[part 1 of 3: package /STLASWCs]
AUTOSAR XML (schema 00044)
package /STLASWCs
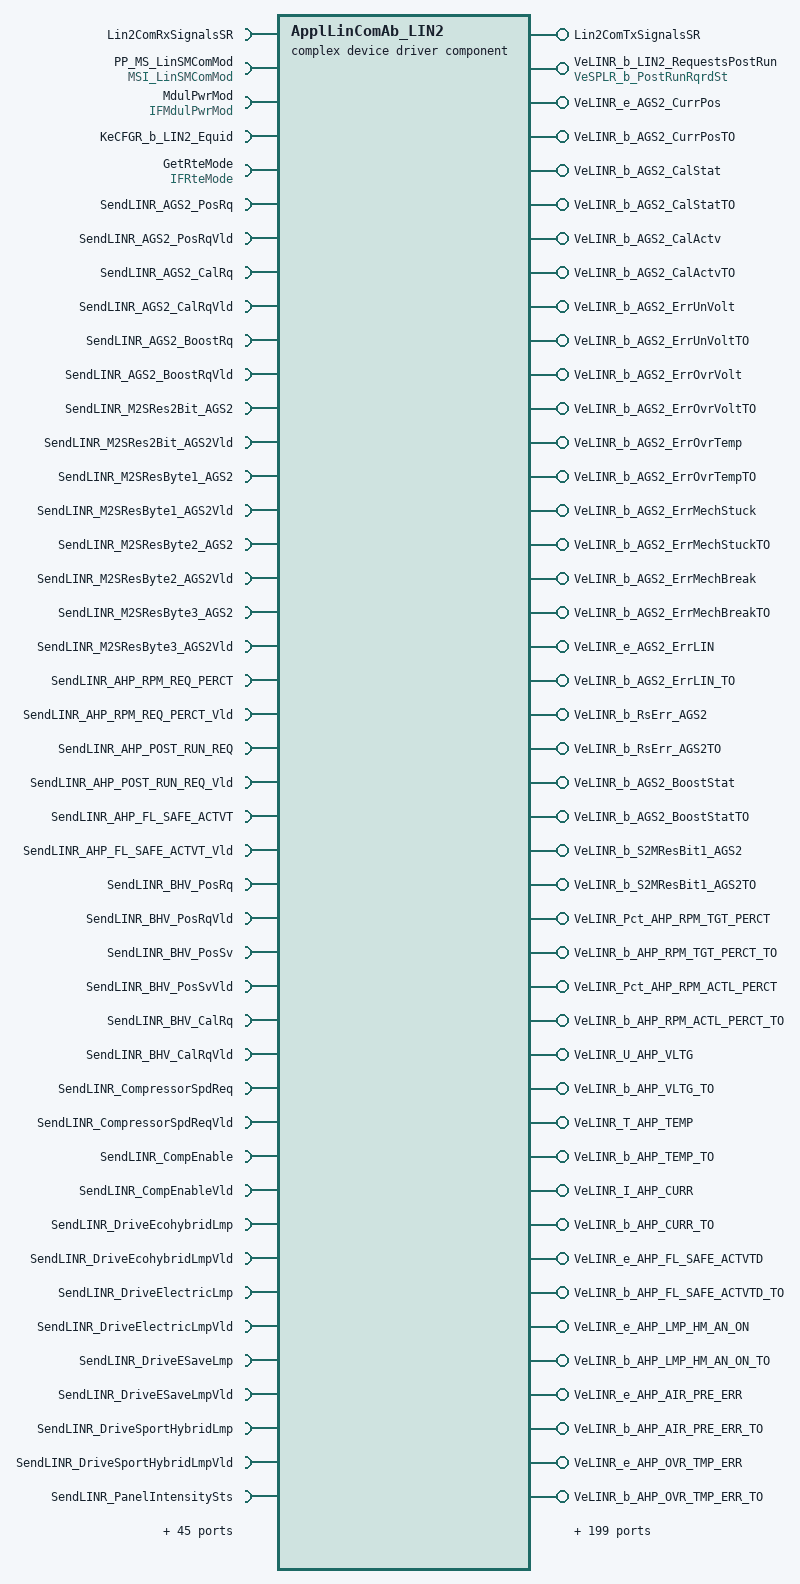
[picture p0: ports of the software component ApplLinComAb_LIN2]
  complex device driver sw component type ApplLinComAb_LIN2  # Application CAN Communication Abstraction Component - is responsible with receiving and sending CAN data from/to the lower BSW COM layers
    provide port Lin2ComTxSignalsSR: provided-interface=Lin2ComTxSignalsSR
      provided-com-specs:
        data-element=COMTXL_AGS2_PosRq_ECM_AGS2_DEMAND_Lin2, init-value=constant-reference=COMTXL_AGS2_PosRq_ECM_AGS2_DEMAND_Lin2_Init
        data-element=COMTXL_AGS2_CalRq_ECM_AGS2_DEMAND_Lin2, init-value=constant-reference=COMTXL_AGS2_CalRq_ECM_AGS2_DEMAND_Lin2_Init
        data-element=COMTXL_AGS2_BoostRq_ECM_AGS2_DEMAND_Lin2, init-value=constant-reference=COMTXL_AGS2_BoostRq_ECM_AGS2_DEMAND_Lin2_Init
        data-element=COMTXL_M2SRes2Bit_AGS2_ECM_AGS2_DEMAND_Lin2, init-value=constant-reference=COMTXL_M2SRes2Bit_AGS2_ECM_AGS2_DEMAND_Lin2_Init
        data-element=COMTXL_M2SResByte{1..3}_AGS2_ECM_AGS2_DEMAND_Lin2, init-value=constant-reference=COMTXL_M2SResByte{1..3}_AGS2_ECM_AGS2_DEMAND_Lin2_Init
        data-element=COMTXL_AHP_RPM_REQ_PERCT_AHP_REQ_GLOBAL_Lin2, init-value=constant-reference=COMTXL_AHP_RPM_REQ_PERCT_AHP_REQ_GLOBAL_Lin2_Init
        data-element=COMTXL_AHP_POST_RUN_REQ_AHP_REQ_GLOBAL_Lin2, init-value=constant-reference=COMTXL_AHP_POST_RUN_REQ_AHP_REQ_GLOBAL_Lin2_Init
        data-element=COMTXL_AHP_FL_SAFE_ACTVT_AHP_REQ_GLOBAL_Lin2, init-value=constant-reference=COMTXL_AHP_FL_SAFE_ACTVT_AHP_REQ_GLOBAL_Lin2_Init
        data-element=COMTXL_BHV_PosRq_BHV_REQ_Lin2, init-value=constant-reference=COMTXL_BHV_PosRq_BHV_REQ_Lin2_Init
        data-element=COMTXL_BHV_PosSv_BHV_REQ_Lin2, init-value=constant-reference=COMTXL_BHV_PosSv_BHV_REQ_Lin2_Init
        data-element=COMTXL_BHV_CalRq_BHV_REQ_Lin2, init-value=constant-reference=COMTXL_BHV_CalRq_BHV_REQ_Lin2_Init
        data-element=COMTXL_CompressorSpdReq_COMP_REQ_Lin2, init-value=constant-reference=COMTXL_CompressorSpdReq_COMP_REQ_Lin2_Init
        data-element=COMTXL_CompEnable_COMP_REQ_Lin2, init-value=constant-reference=COMTXL_CompEnable_COMP_REQ_Lin2_Init
        data-element=COMTXL_DriveEcohybridLmp_MASTER_ESBM_1_Lin2, init-value=constant-reference=COMTXL_DriveEcohybridLmp_MASTER_ESBM_1_Lin2_Init
        data-element=COMTXL_DriveElectricLmp_MASTER_ESBM_1_Lin2, init-value=constant-reference=COMTXL_DriveElectricLmp_MASTER_ESBM_1_Lin2_Init
        data-element=COMTXL_DriveESaveLmp_MASTER_ESBM_1_Lin2, init-value=constant-reference=COMTXL_DriveESaveLmp_MASTER_ESBM_1_Lin2_Init
        data-element=COMTXL_DriveSportHybridLmp_MASTER_ESBM_1_Lin2, init-value=constant-reference=COMTXL_DriveSportHybridLmp_MASTER_ESBM_1_Lin2_Init
        data-element=COMTXL_PanelIntensitySts_MASTER_ESBM_1_Lin2, init-value=constant-reference=COMTXL_PanelIntensitySts_MASTER_ESBM_1_Lin2_Init
        data-element=COMTXL_DAY_LGT_MD_MASTER_ESBM_1_Lin2, init-value=constant-reference=COMTXL_DAY_LGT_MD_MASTER_ESBM_1_Lin2_Init
        data-element=COMTXL_PECP_RPM_REQ_PERCT_PECP_REQ_GLOBAL_Lin2, init-value=constant-reference=COMTXL_PECP_RPM_REQ_PERCT_PECP_REQ_GLOBAL_Lin2_Init
        data-element=COMTXL_PECP_POST_RUN_REQ_PECP_REQ_GLOBAL_Lin2, init-value=constant-reference=COMTXL_PECP_POST_RUN_REQ_PECP_REQ_GLOBAL_Lin2_Init
        data-element=COMTXL_PECP_FL_SAFE_ACTVT_PECP_REQ_GLOBAL_Lin2, init-value=constant-reference=COMTXL_PECP_FL_SAFE_ACTVT_PECP_REQ_GLOBAL_Lin2_Init
        data-element=COMTXL_PowerPanel_LED_A_Command_PowerPanel_REQ_Lin2, init-value=constant-reference=COMTXL_PowerPanel_LED_A_Command_PowerPanel_REQ_Lin2_Init
        data-element=COMTXL_PowerPanel_LED_B_Command_PowerPanel_REQ_Lin2, init-value=constant-reference=COMTXL_PowerPanel_LED_B_Command_PowerPanel_REQ_Lin2_Init
        data-element=COMTXL_DAY_LGT_MD_PowerPanel_PowerPanel_REQ_Lin2, init-value=constant-reference=COMTXL_DAY_LGT_MD_PowerPanel_PowerPanel_REQ_Lin2_Init
        data-element=COMTXL_OEXV_PosRq_OEXV_REQ_Lin2, init-value=constant-reference=COMTXL_OEXV_PosRq_OEXV_REQ_Lin2_Init
        data-element=COMTXL_OEXV_CalCmd_OEXV_REQ_Lin2, init-value=constant-reference=COMTXL_OEXV_CalCmd_OEXV_REQ_Lin2_Init
        data-element=COMTXL_PowerPanel_LED_C_Command_PowerPanel_REQ_Lin2, init-value=constant-reference=COMTXL_PowerPanel_LED_C_Command_PowerPanel_REQ_Lin2_Init
        data-element=COMTXL_PowerPanel_LED_A_Color_Command_PowerPanel_REQ_Lin2, init-value=constant-reference=COMTXL_PowerPanel_LED_A_Color_Command_PowerPanel_REQ_Lin2_Init
        data-element=COMTXL_PowerPanel_LED_B_Color_Command_PowerPanel_REQ_Lin2, init-value=constant-reference=COMTXL_PowerPanel_LED_B_Color_Command_PowerPanel_REQ_Lin2_Init
        data-element=COMTXL_PowerPanel_LED_C_Color_Command_PowerPanel_REQ_Lin2, init-value=constant-reference=COMTXL_PowerPanel_LED_C_Color_Command_PowerPanel_REQ_Lin2_Init
    provide port VeLINR_b_LIN2_RequestsPostRun: nonqueued-sender-com-spec{data-element=VeSPLR_b_PostRunRqrdSt, init-value=1}, provided-interface=VeSPLR_b_PostRunRqrdSt  # Indicates LIN is ready for power down
    5 x require port:
      Lin2ComRxSignalsSR: required-interface=Lin2ComRxSignalsSR
        required-com-specs:
          data-element=COMRXL_AGS2_CurrPos_AGS2_ECM_STATUS_Lin2, alive-timeout=2.5, handle-never-received=true, init-value=constant-reference=COMRXL_AGS2_CurrPos_AGS2_ECM_STATUS_Lin2_Init
          data-element=COMRXL_AGS2_CalStat_AGS2_ECM_STATUS_Lin2, alive-timeout=2.5, handle-never-received=true, init-value=constant-reference=COMRXL_AGS2_CalStat_AGS2_ECM_STATUS_Lin2_Init
          data-element=COMRXL_AGS2_CalActv_AGS2_ECM_STATUS_Lin2, alive-timeout=2.5, handle-never-received=true, init-value=constant-reference=COMRXL_AGS2_CalActv_AGS2_ECM_STATUS_Lin2_Init
          data-element=COMRXL_AGS2_ErrUnVolt_AGS2_ECM_STATUS_Lin2, alive-timeout=2.5, handle-never-received=true, init-value=constant-reference=COMRXL_AGS2_ErrUnVolt_AGS2_ECM_STATUS_Lin2_Init
          data-element=COMRXL_AGS2_ErrOvrVolt_AGS2_ECM_STATUS_Lin2, alive-timeout=2.5, handle-never-received=true, init-value=constant-reference=COMRXL_AGS2_ErrOvrVolt_AGS2_ECM_STATUS_Lin2_Init
          data-element=COMRXL_AGS2_ErrOvrTemp_AGS2_ECM_STATUS_Lin2, alive-timeout=2.5, handle-never-received=true, init-value=constant-reference=COMRXL_AGS2_ErrOvrTemp_AGS2_ECM_STATUS_Lin2_Init
          data-element=COMRXL_AGS2_ErrMechStuck_AGS2_ECM_STATUS_Lin2, alive-timeout=2.5, handle-never-received=true, init-value=constant-reference=COMRXL_AGS2_ErrMechStuck_AGS2_ECM_STATUS_Lin2_Init
          data-element=COMRXL_AGS2_ErrMechBreak_AGS2_ECM_STATUS_Lin2, alive-timeout=2.5, handle-never-received=true, init-value=constant-reference=COMRXL_AGS2_ErrMechBreak_AGS2_ECM_STATUS_Lin2_Init
          data-element=COMRXL_AGS2_ErrLIN_AGS2_ECM_STATUS_Lin2, alive-timeout=2.5, handle-never-received=true, init-value=constant-reference=COMRXL_AGS2_ErrLIN_AGS2_ECM_STATUS_Lin2_Init
          data-element=COMRXL_RsErr_AGS2_AGS2_ECM_STATUS_Lin2, alive-timeout=2.5, handle-never-received=true, init-value=constant-reference=COMRXL_RsErr_AGS2_AGS2_ECM_STATUS_Lin2_Init
          data-element=COMRXL_AGS2_BoostStat_AGS2_ECM_STATUS_Lin2, alive-timeout=2.5, handle-never-received=true, init-value=constant-reference=COMRXL_AGS2_BoostStat_AGS2_ECM_STATUS_Lin2_Init
          data-element=COMRXL_S2MResBit1_AGS2_AGS2_ECM_STATUS_Lin2, alive-timeout=2.5, handle-never-received=true, init-value=constant-reference=COMRXL_S2MResBit1_AGS2_AGS2_ECM_STATUS_Lin2_Init
          data-element=COMRXL_AHP_RPM_TGT_PERCT_AHP_STAT_GLOBAL_Lin2, alive-timeout=2.5, handle-never-received=true, init-value=constant-reference=COMRXL_AHP_RPM_TGT_PERCT_AHP_STAT_GLOBAL_Lin2_Init
          data-element=COMRXL_AHP_RPM_ACTL_PERCT_AHP_STAT_GLOBAL_Lin2, alive-timeout=2.5, handle-never-received=true, init-value=constant-reference=COMRXL_AHP_RPM_ACTL_PERCT_AHP_STAT_GLOBAL_Lin2_Init
          data-element=COMRXL_AHP_VLTG_AHP_STAT_GLOBAL_Lin2, alive-timeout=2.5, handle-never-received=true, init-value=constant-reference=COMRXL_AHP_VLTG_AHP_STAT_GLOBAL_Lin2_Init
          data-element=COMRXL_AHP_TEMP_AHP_STAT_GLOBAL_Lin2, alive-timeout=2.5, handle-never-received=true, init-value=constant-reference=COMRXL_AHP_TEMP_AHP_STAT_GLOBAL_Lin2_Init
          data-element=COMRXL_AHP_CURR_AHP_STAT_GLOBAL_Lin2, alive-timeout=2.5, handle-never-received=true, init-value=constant-reference=COMRXL_AHP_CURR_AHP_STAT_GLOBAL_Lin2_Init
          data-element=COMRXL_AHP_FL_SAFE_ACTVTD_AHP_STAT_GLOBAL_Lin2, alive-timeout=2.5, handle-never-received=true, init-value=constant-reference=COMRXL_AHP_FL_SAFE_ACTVTD_AHP_STAT_GLOBAL_Lin2_Init
          data-element=COMRXL_AHP_LMP_HM_AN_ON_AHP_STAT_GLOBAL_Lin2, alive-timeout=2.5, handle-never-received=true, init-value=constant-reference=COMRXL_AHP_LMP_HM_AN_ON_AHP_STAT_GLOBAL_Lin2_Init
          data-element=COMRXL_AHP_AIR_PRE_ERR_AHP_STAT_GLOBAL_Lin2, alive-timeout=2.5, handle-never-received=true, init-value=constant-reference=COMRXL_AHP_AIR_PRE_ERR_AHP_STAT_GLOBAL_Lin2_Init
          data-element=COMRXL_AHP_OVR_TMP_ERR_AHP_STAT_GLOBAL_Lin2, alive-timeout=2.5, handle-never-received=true, init-value=constant-reference=COMRXL_AHP_OVR_TMP_ERR_AHP_STAT_GLOBAL_Lin2_Init
          data-element=COMRXL_AHP_OVR_CUR_ERR_AHP_STAT_GLOBAL_Lin2, alive-timeout=2.5, handle-never-received=true, init-value=constant-reference=COMRXL_AHP_OVR_CUR_ERR_AHP_STAT_GLOBAL_Lin2_Init
          data-element=COMRXL_AHP_DR_RN_ERR_AHP_STAT_GLOBAL_Lin2, alive-timeout=2.5, handle-never-received=true, init-value=constant-reference=COMRXL_AHP_DR_RN_ERR_AHP_STAT_GLOBAL_Lin2_Init
          data-element=COMRXL_AHP_VLTG_ERR_AHP_STAT_GLOBAL_Lin2, alive-timeout=2.5, handle-never-received=true, init-value=constant-reference=COMRXL_AHP_VLTG_ERR_AHP_STAT_GLOBAL_Lin2_Init
          data-element=COMRXL_AHP_DBLK_ACTV_AHP_STAT_GLOBAL_Lin2, alive-timeout=2.5, handle-never-received=true, init-value=constant-reference=COMRXL_AHP_DBLK_ACTV_AHP_STAT_GLOBAL_Lin2_Init
          data-element=COMRXL_AHP_MONTRNG_RPM_AHP_STAT_GLOBAL_Lin2, alive-timeout=2.5, handle-never-received=true, init-value=constant-reference=COMRXL_AHP_MONTRNG_RPM_AHP_STAT_GLOBAL_Lin2_Init
          data-element=COMRXL_AHP_NODE_ERR_AHP_STAT_GLOBAL_Lin2, alive-timeout=2.5, handle-never-received=true, init-value=constant-reference=COMRXL_AHP_NODE_ERR_AHP_STAT_GLOBAL_Lin2_Init
          data-element=COMRXL_AHP_POST_RUN_STAT_AHP_STAT_GLOBAL_Lin2, alive-timeout=2.5, handle-never-received=true, init-value=constant-reference=COMRXL_AHP_POST_RUN_STAT_AHP_STAT_GLOBAL_Lin2_Init
          data-element=COMRXL_RsErr_AHP_PUMP_AHP_STAT_GLOBAL_Lin2, alive-timeout=2.5, handle-never-received=true, init-value=constant-reference=COMRXL_RsErr_AHP_PUMP_AHP_STAT_GLOBAL_Lin2_Init
          data-element=COMRXL_AHP_SUPPLIER_AHP_VER_Lin2, alive-timeout=2.5, handle-never-received=true, init-value=constant-reference=COMRXL_AHP_SUPPLIER_AHP_VER_Lin2_Init
          data-element=COMRXL_BHV_PosAct_BHV_STAT_V2_Lin2, alive-timeout=2.5, handle-never-received=true, init-value=constant-reference=COMRXL_BHV_PosAct_BHV_STAT_V2_Lin2_Init
          data-element=COMRXL_BHV_ERR_BHV_STAT_V2_Lin2, alive-timeout=2.5, handle-never-received=true, init-value=constant-reference=COMRXL_BHV_ERR_BHV_STAT_V2_Lin2_Init
          data-element=COMRXL_BHV_Sts_BHV_STAT_V2_Lin2, alive-timeout=2.5, handle-never-received=true, init-value=constant-reference=COMRXL_BHV_Sts_BHV_STAT_V2_Lin2_Init
          data-element=COMRXL_RsErr_BHV_BHV_STAT_V2_Lin2, alive-timeout=2.5, handle-never-received=true, init-value=constant-reference=COMRXL_RsErr_BHV_BHV_STAT_V2_Lin2_Init
          data-element=COMRXL_CompFaultStat_EAC_STAT_Lin2, alive-timeout=2.5, handle-never-received=true, init-value=constant-reference=COMRXL_CompFaultStat_EAC_STAT_Lin2_Init
          data-element=COMRXL_CompStat_EAC_STAT_Lin2, alive-timeout=2.5, handle-never-received=true, init-value=constant-reference=COMRXL_CompStat_EAC_STAT_Lin2_Init
          data-element=COMRXL_CompressorSpd_EAC_STAT_Lin2, alive-timeout=2.5, handle-never-received=true, init-value=constant-reference=COMRXL_CompressorSpd_EAC_STAT_Lin2_Init
          data-element=COMRXL_CompSpdIncrReq_EAC_STAT_Lin2, alive-timeout=2.5, handle-never-received=true, init-value=constant-reference=COMRXL_CompSpdIncrReq_EAC_STAT_Lin2_Init
          data-element=COMRXL_CompElecPwr_EAC_STAT_Lin2, alive-timeout=2.5, handle-never-received=true, init-value=constant-reference=COMRXL_CompElecPwr_EAC_STAT_Lin2_Init
          data-element=COMRXL_CompBoardTemp_EAC_STAT_Lin2, alive-timeout=2.5, handle-never-received=true, init-value=constant-reference=COMRXL_CompBoardTemp_EAC_STAT_Lin2_Init
          data-element=COMRXL_CompIGBTTemp_EAC_STAT_Lin2, alive-timeout=2.5, handle-never-received=true, init-value=constant-reference=COMRXL_CompIGBTTemp_EAC_STAT_Lin2_Init
          data-element=COMRXL_CompElecCurr_EAC_STAT_Lin2, alive-timeout=2.5, handle-never-received=true, init-value=constant-reference=COMRXL_CompElecCurr_EAC_STAT_Lin2_Init
          data-element=COMRXL_CompHVInput_EAC_STAT_Lin2, alive-timeout=2.5, handle-never-received=true, init-value=constant-reference=COMRXL_CompHVInput_EAC_STAT_Lin2_Init
          data-element=COMRXL_DriveMdReq_ESBM_1_Lin2, alive-timeout=2.5, handle-never-received=true, init-value=constant-reference=COMRXL_DriveMdReq_ESBM_1_Lin2_Init
          data-element=COMRXL_HybridModeRq_LIN_ESBM_1_Lin2, alive-timeout=2.5, handle-never-received=true, init-value=constant-reference=COMRXL_HybridModeRq_LIN_ESBM_1_Lin2_Init
          data-element=COMRXL_ESaveModeRq_LIN_ESBM_1_Lin2, alive-timeout=2.5, handle-never-received=true, init-value=constant-reference=COMRXL_ESaveModeRq_LIN_ESBM_1_Lin2_Init
          data-element=COMRXL_ElectricModeRq_LIN_ESBM_1_Lin2, alive-timeout=2.5, handle-never-received=true, init-value=constant-reference=COMRXL_ElectricModeRq_LIN_ESBM_1_Lin2_Init
          data-element=COMRXL_RsErr_ESBM_ESBM_1_Lin2, alive-timeout=2.5, handle-never-received=true, init-value=constant-reference=COMRXL_RsErr_ESBM_ESBM_1_Lin2_Init
          data-element=COMRXL_PECP_RPM_TGT_PERCT_PECP_STAT_GLOBAL_Lin2, alive-timeout=2.5, handle-never-received=true, init-value=constant-reference=COMRXL_PECP_RPM_TGT_PERCT_PECP_STAT_GLOBAL_Lin2_Init
          data-element=COMRXL_PECP_RPM_ACTL_PERCT_PECP_STAT_GLOBAL_Lin2, alive-timeout=2.5, handle-never-received=true, init-value=constant-reference=COMRXL_PECP_RPM_ACTL_PERCT_PECP_STAT_GLOBAL_Lin2_Init
          data-element=COMRXL_PECP_VLTG_PECP_STAT_GLOBAL_Lin2, alive-timeout=2.5, handle-never-received=true, init-value=constant-reference=COMRXL_PECP_VLTG_PECP_STAT_GLOBAL_Lin2_Init
          data-element=COMRXL_PECP_TEMP_PECP_STAT_GLOBAL_Lin2, alive-timeout=2.5, handle-never-received=true, init-value=constant-reference=COMRXL_PECP_TEMP_PECP_STAT_GLOBAL_Lin2_Init
          data-element=COMRXL_PECP_CURR_PECP_STAT_GLOBAL_Lin2, alive-timeout=2.5, handle-never-received=true, init-value=constant-reference=COMRXL_PECP_CURR_PECP_STAT_GLOBAL_Lin2_Init
          data-element=COMRXL_PECP_FL_SAFE_ACTVTD_PECP_STAT_GLOBAL_Lin2, alive-timeout=2.5, handle-never-received=true, init-value=constant-reference=COMRXL_PECP_FL_SAFE_ACTVTD_PECP_STAT_GLOBAL_Lin2_Init
          data-element=COMRXL_PECP_LMP_HM_AN_ON_PECP_STAT_GLOBAL_Lin2, alive-timeout=2.5, handle-never-received=true, init-value=constant-reference=COMRXL_PECP_LMP_HM_AN_ON_PECP_STAT_GLOBAL_Lin2_Init
          data-element=COMRXL_PECP_AIR_PRE_ERR_PECP_STAT_GLOBAL_Lin2, alive-timeout=2.5, handle-never-received=true, init-value=constant-reference=COMRXL_PECP_AIR_PRE_ERR_PECP_STAT_GLOBAL_Lin2_Init
          data-element=COMRXL_PECP_OVR_TMP_ERR_PECP_STAT_GLOBAL_Lin2, alive-timeout=2.5, handle-never-received=true, init-value=constant-reference=COMRXL_PECP_OVR_TMP_ERR_PECP_STAT_GLOBAL_Lin2_Init
          data-element=COMRXL_PECP_OVR_CUR_ERR_PECP_STAT_GLOBAL_Lin2, alive-timeout=2.5, handle-never-received=true, init-value=constant-reference=COMRXL_PECP_OVR_CUR_ERR_PECP_STAT_GLOBAL_Lin2_Init
          data-element=COMRXL_PECP_DR_RN_ERR_PECP_STAT_GLOBAL_Lin2, alive-timeout=2.5, handle-never-received=true, init-value=constant-reference=COMRXL_PECP_DR_RN_ERR_PECP_STAT_GLOBAL_Lin2_Init
          data-element=COMRXL_PECP_VLTG_ERR_PECP_STAT_GLOBAL_Lin2, alive-timeout=2.5, handle-never-received=true, init-value=constant-reference=COMRXL_PECP_VLTG_ERR_PECP_STAT_GLOBAL_Lin2_Init
          data-element=COMRXL_PECP_DBLK_ACTV_PECP_STAT_GLOBAL_Lin2, alive-timeout=2.5, handle-never-received=true, init-value=constant-reference=COMRXL_PECP_DBLK_ACTV_PECP_STAT_GLOBAL_Lin2_Init
          data-element=COMRXL_PECP_MONTRNG_RPM_PECP_STAT_GLOBAL_Lin2, alive-timeout=2.5, handle-never-received=true, init-value=constant-reference=COMRXL_PECP_MONTRNG_RPM_PECP_STAT_GLOBAL_Lin2_Init
          data-element=COMRXL_PECP_NODE_ERR_PECP_STAT_GLOBAL_Lin2, alive-timeout=2.5, handle-never-received=true, init-value=constant-reference=COMRXL_PECP_NODE_ERR_PECP_STAT_GLOBAL_Lin2_Init
          data-element=COMRXL_PECP_POST_RUN_STAT_PECP_STAT_GLOBAL_Lin2, alive-timeout=2.5, handle-never-received=true, init-value=constant-reference=COMRXL_PECP_POST_RUN_STAT_PECP_STAT_GLOBAL_Lin2_Init
          data-element=COMRXL_RsErr_PECP_PUMP_PECP_STAT_GLOBAL_Lin2, alive-timeout=2.5, handle-never-received=true, init-value=constant-reference=COMRXL_RsErr_PECP_PUMP_PECP_STAT_GLOBAL_Lin2_Init
          data-element=COMRXL_PECP_SUPPLIER_PECP_VER_Lin2, alive-timeout=2.5, handle-never-received=true, init-value=constant-reference=COMRXL_PECP_SUPPLIER_PECP_VER_Lin2_Init
          data-element=COMRXL_PowerPanel_Button_State_PowerPanel_STAT_Lin2, alive-timeout=2.5, handle-never-received=true, init-value=constant-reference=COMRXL_PowerPanel_Button_State_PowerPanel_STAT_Lin2_Init
          data-element=COMRXL_PowerPanel_Lid_Switch_Sts_120A_PowerPanel_STAT_Lin2, alive-timeout=2.5, handle-never-received=true, init-value=constant-reference=COMRXL_PowerPanel_Lid_Switch_Sts_120A_PowerPanel_STAT_Lin2_Init
          data-element=COMRXL_PowerPanel_Lid_Switch_Sts_120B_PowerPanel_STAT_Lin2, alive-timeout=2.5, handle-never-received=true, init-value=constant-reference=COMRXL_PowerPanel_Lid_Switch_Sts_120B_PowerPanel_STAT_Lin2_Init
          data-element=COMRXL_PowerPanel_Lid_Switch_Sts_240_PowerPanel_STAT_Lin2, alive-timeout=2.5, handle-never-received=true, init-value=constant-reference=COMRXL_PowerPanel_Lid_Switch_Sts_240_PowerPanel_STAT_Lin2_Init
          data-element=COMRXL_PowerPanel_Fault_Reason_PowerPanel_STAT_Lin2, alive-timeout=2.5, handle-never-received=true, init-value=constant-reference=COMRXL_PowerPanel_Fault_Reason_PowerPanel_STAT_Lin2_Init
          data-element=COMRXL_RsErr_SPP_PowerPanel_STAT_Lin2, alive-timeout=2.5, handle-never-received=true, init-value=constant-reference=COMRXL_RsErr_SPP_PowerPanel_STAT_Lin2_Init
          data-element=COMRXL_AHP_VERSION_AHP_VER_Lin2, alive-timeout=2.5, handle-never-received=true, init-value=constant-reference=COMRXL_AHP_VERSION_AHP_VER_Lin2_Init
          data-element=COMRXL_PECP_VERSION_PECP_VER_Lin2, alive-timeout=2.5, handle-never-received=true, init-value=constant-reference=COMRXL_PECP_VERSION_PECP_VER_Lin2_Init
          data-element=COMRXL_S2MResByte1_AGS2_AGS2_ECM_STATUS_Lin2, alive-timeout=2.5, handle-never-received=true, init-value=constant-reference=COMRXL_S2MResByte1_AGS2_AGS2_ECM_STATUS_Lin2_Init
          data-element=COMRXL_S2MResByte2_AGS2_AGS2_ECM_STATUS_Lin2, alive-timeout=2.5, handle-never-received=true, init-value=constant-reference=COMRXL_S2MResByte2_AGS2_AGS2_ECM_STATUS_Lin2_Init
          data-element=COMRXL_BHV_MotorVolt_BHV_STAT_V2_Lin2, alive-timeout=2.5, handle-never-received=true, init-value=constant-reference=COMRXL_BHV_MotorVolt_BHV_STAT_V2_Lin2_Init
          data-element=COMRXL_BHV_CalStat_BHV_STAT_V2_Lin2, alive-timeout=2.5, handle-never-received=true, init-value=constant-reference=COMRXL_BHV_CalStat_BHV_STAT_V2_Lin2_Init
          data-element=COMRXL_OEXV_PosAct_OEXV_STAT_Lin2, alive-timeout=2.5, handle-never-received=true, init-value=constant-reference=COMRXL_OEXV_PosAct_OEXV_STAT_Lin2_Init
          data-element=COMRXL_OEXV_CalStat_OEXV_STAT_Lin2, alive-timeout=2.5, handle-never-received=true, init-value=constant-reference=COMRXL_OEXV_CalStat_OEXV_STAT_Lin2_Init
          data-element=COMRXL_OEXV_CalRq_OEXV_STAT_Lin2, alive-timeout=2.5, handle-never-received=true, init-value=constant-reference=COMRXL_OEXV_CalRq_OEXV_STAT_Lin2_Init
          data-element=COMRXL_RsErr_OEXV_OEXV_STAT_Lin2, alive-timeout=2.5, handle-never-received=true, init-value=constant-reference=COMRXL_RsErr_OEXV_OEXV_STAT_Lin2_Init
          data-element=COMRXL_OEXV_Sts_OEXV_STAT_Lin2, alive-timeout=2.5, handle-never-received=true, init-value=constant-reference=COMRXL_OEXV_Sts_OEXV_STAT_Lin2_Init
          data-element=COMRXL_OEXV_ERR_OEXV_STAT_Lin2, alive-timeout=2.5, handle-never-received=true, init-value=constant-reference=COMRXL_OEXV_ERR_OEXV_STAT_Lin2_Init
          data-element=COMRXL_OEXV_SupplyVolt_OEXV_STAT_Lin2, alive-timeout=2.5, handle-never-received=true, init-value=constant-reference=COMRXL_OEXV_SupplyVolt_OEXV_STAT_Lin2_Init
          data-element=COMRXL_OEXV_Refrigerant_Pressure_OEXV_STAT_Lin2, alive-timeout=2.5, handle-never-received=true, init-value=constant-reference=COMRXL_OEXV_Refrigerant_Pressure_OEXV_STAT_Lin2_Init
          data-element=COMRXL_OEXV_Board_Temp_OEXV_STAT_Lin2, alive-timeout=2.5, handle-never-received=true, init-value=constant-reference=COMRXL_OEXV_Board_Temp_OEXV_STAT_Lin2_Init
          data-element=COMRXL_OEXV_Refrigerant_Temp_OEXV_STAT_Lin2, alive-timeout=2.5, handle-never-received=true, init-value=constant-reference=COMRXL_OEXV_Refrigerant_Temp_OEXV_STAT_Lin2_Init
          data-element=COMRXL_CompFaultStat_800_EAC_STAT_800_Lin2, alive-timeout=2.5, handle-never-received=true, init-value=constant-reference=COMRXL_CompFaultStat_800_EAC_STAT_800_Lin2_Init
          data-element=COMRXL_CompStat_800_EAC_STAT_800_Lin2, alive-timeout=2.5, handle-never-received=true, init-value=constant-reference=COMRXL_CompStat_800_EAC_STAT_800_Lin2_Init
          data-element=COMRXL_CompressorSpd_800_EAC_STAT_800_Lin2, alive-timeout=2.5, handle-never-received=true, init-value=constant-reference=COMRXL_CompressorSpd_800_EAC_STAT_800_Lin2_Init
          data-element=COMRXL_CompSpdIncrReq_800_EAC_STAT_800_Lin2, alive-timeout=2.5, handle-never-received=true, init-value=constant-reference=COMRXL_CompSpdIncrReq_800_EAC_STAT_800_Lin2_Init
          data-element=COMRXL_RsErr_EAC2_800_EAC_STAT_800_Lin2, alive-timeout=2.5, handle-never-received=true, init-value=constant-reference=COMRXL_RsErr_EAC2_800_EAC_STAT_800_Lin2_Init
          data-element=COMRXL_CompElecPwr_800_EAC_STAT_800_Lin2, alive-timeout=2.5, handle-never-received=true, init-value=constant-reference=COMRXL_CompElecPwr_800_EAC_STAT_800_Lin2_Init
          data-element=COMRXL_CompBoardTemp_800_EAC_STAT_800_Lin2, alive-timeout=2.5, handle-never-received=true, init-value=constant-reference=COMRXL_CompBoardTemp_800_EAC_STAT_800_Lin2_Init
          data-element=COMRXL_CompIGBTTemp_800_EAC_STAT_800_Lin2, alive-timeout=2.5, handle-never-received=true, init-value=constant-reference=COMRXL_CompIGBTTemp_800_EAC_STAT_800_Lin2_Init
          data-element=COMRXL_CompElecCurr_800_EAC_STAT_800_Lin2, alive-timeout=2.5, handle-never-received=true, init-value=constant-reference=COMRXL_CompElecCurr_800_EAC_STAT_800_Lin2_Init
          data-element=COMRXL_CompHVInput_800_EAC_STAT_800_Lin2, alive-timeout=2.5, handle-never-received=true, init-value=constant-reference=COMRXL_CompHVInput_800_EAC_STAT_800_Lin2_Init
          data-element=COMRXL_PowerPanel_LED_A_Feedback_PowerPanel_STAT_Lin2, alive-timeout=2.5, handle-never-received=true, init-value=constant-reference=COMRXL_PowerPanel_LED_A_Feedback_PowerPanel_STAT_Lin2_Init
          data-element=COMRXL_PowerPanel_LED_B_Feedback_PowerPanel_STAT_Lin2, alive-timeout=2.5, handle-never-received=true, init-value=constant-reference=COMRXL_PowerPanel_LED_B_Feedback_PowerPanel_STAT_Lin2_Init
          data-element=COMRXL_PowerPanel_LED_C_Feedback_PowerPanel_STAT_Lin2, alive-timeout=2.5, handle-never-received=true, init-value=constant-reference=COMRXL_PowerPanel_LED_C_Feedback_PowerPanel_STAT_Lin2_Init
          data-element=COMRXL_PowerPanel_LED_A_FailStatus_PowerPanel_STAT_Lin2, alive-timeout=2.5, handle-never-received=true, init-value=constant-reference=COMRXL_PowerPanel_LED_A_FailStatus_PowerPanel_STAT_Lin2_Init
          data-element=COMRXL_PowerPanel_LED_B_FailStatus_PowerPanel_STAT_Lin2, alive-timeout=2.5, handle-never-received=true, init-value=constant-reference=COMRXL_PowerPanel_LED_B_FailStatus_PowerPanel_STAT_Lin2_Init
          data-element=COMRXL_PowerPanel_LED_C_FailStatus_PowerPanel_STAT_Lin2, alive-timeout=2.5, handle-never-received=true, init-value=constant-reference=COMRXL_PowerPanel_LED_C_FailStatus_PowerPanel_STAT_Lin2_Init
          data-element=COMRXL_PowerPanel_LED_A_Color_Feedback_PowerPanel_STAT_Lin2, alive-timeout=2.5, handle-never-received=true, init-value=constant-reference=COMRXL_PowerPanel_LED_A_Color_Feedback_PowerPanel_STAT_Lin2_Init
          data-element=COMRXL_PowerPanel_LED_B_Color_Feedback_PowerPanel_STAT_Lin2, alive-timeout=2.5, handle-never-received=true, init-value=constant-reference=COMRXL_PowerPanel_LED_B_Color_Feedback_PowerPanel_STAT_Lin2_Init
          data-element=COMRXL_PowerPanel_LED_C_Color_Feedback_PowerPanel_STAT_Lin2, alive-timeout=2.5, handle-never-received=true, init-value=constant-reference=COMRXL_PowerPanel_LED_C_Color_Feedback_PowerPanel_STAT_Lin2_Init
          data-element=COMRXL_PowerPanel_LIN_Checksum_Error_PowerPanel_STAT_Lin2, alive-timeout=2.5, handle-never-received=true, init-value=constant-reference=COMRXL_PowerPanel_LIN_Checksum_Error_PowerPanel_STAT_Lin2_Init
          data-element=COMRXL_PowerPanel_LIN_Data_Error_PowerPanel_STAT_Lin2, alive-timeout=2.5, handle-never-received=true, init-value=constant-reference=COMRXL_PowerPanel_LIN_Data_Error_PowerPanel_STAT_Lin2_Init
          data-element=COMRXL_PowerPanel_LIN_Parity_Error_PowerPanel_STAT_Lin2, alive-timeout=2.5, handle-never-received=true, init-value=constant-reference=COMRXL_PowerPanel_LIN_Parity_Error_PowerPanel_STAT_Lin2_Init
          data-element=COMRXL_PowerPanel_Gnd_Fault_Detected_PowerPanel_STAT_Lin2, alive-timeout=2.5, handle-never-received=true, init-value=constant-reference=COMRXL_PowerPanel_Gnd_Fault_Detected_PowerPanel_STAT_Lin2_Init
          data-element=COMRXL_RsErr_EAC2_EAC_STAT_Lin2, alive-timeout=2.5, handle-never-received=true, init-value=constant-reference=COMRXL_RsErr_EAC2_EAC_STAT_Lin2_Init
          data-element=COMRXL_PowerPanel_Fault_PowerPanel_STAT_Lin2, alive-timeout=2.5, handle-never-received=true, init-value=constant-reference=COMRXL_PowerPanel_Fault_PowerPanel_STAT_Lin2_Init
          data-element=COMRXL_PowerPanel_RatedPower_PowerPanel_STAT_Lin2, alive-timeout=2.5, handle-never-received=true, init-value=constant-reference=COMRXL_PowerPanel_RatedPower_PowerPanel_STAT_Lin2_Init
          data-element=COMRXL_PowerPanel_Current_Draw_Sens2_PowerPanel_STAT_Lin2, alive-timeout=2.5, handle-never-received=true, init-value=constant-reference=COMRXL_PowerPanel_Current_Draw_Sens2_PowerPanel_STAT_Lin2_Init
          data-element=COMRXL_PowerPanel_AC_Present_Sens1_PowerPanel_STAT_Lin2, alive-timeout=2.5, handle-never-received=true, init-value=constant-reference=COMRXL_PowerPanel_AC_Present_Sens1_PowerPanel_STAT_Lin2_Init
          data-element=COMRXL_PowerPanel_AC_Present_Sens2_PowerPanel_STAT_Lin2, alive-timeout=2.5, handle-never-received=true, init-value=constant-reference=COMRXL_PowerPanel_AC_Present_Sens2_PowerPanel_STAT_Lin2_Init
          data-element=COMRXL_PowerPanel_Current_Draw_Sens1_PowerPanel_STAT_Lin2, alive-timeout=2.5, handle-never-received=true, init-value=constant-reference=COMRXL_PowerPanel_Current_Draw_Sens1_PowerPanel_STAT_Lin2_Init
      PP_MS_LinSMComMod: mode-switch-receiver-com-spec=MDGP_MSI_LinSMComMod, required-interface=MSI_LinSMComMod  # Mode switch port used to indicate Linsm comm state
      MdulPwrMod: mode-switch-receiver-com-spec=AppMode_MDGP_ESH_Mode, required-interface=IFMdulPwrMod  # Mode switch port used to indicate ECU state
      KeCFGR_b_LIN2_Equid: parameter-require-com-spec{init-value=Value:1, parameter=KeCFGR_b_LIN2_Equid}, required-interface=KeCFGR_b_LIN2_Equid
      GetRteMode: client-com-spec=GetMODR_b_InPostRunMode, required-interface=IFRteMode
    151 x provide port:
      VeLINR_e_AGS2_CurrPos: nonqueued-sender-com-spec{data-element=VeLINR_e_AGS2_CurrPos, init-value=VeLINR_e_AGS2_CurrPosValue:0}, provided-interface=VeLINR_e_AGS2_CurrPos
      VeLINR_b_AGS2_CurrPosTO: nonqueued-sender-com-spec{data-element=VeLINR_b_AGS2_CurrPosTO, init-value=VeLINR_b_AGS2_CurrPosTOValue:0}, provided-interface=VeLINR_b_AGS2_CurrPosTO
      VeLINR_b_AGS2_CalStat: nonqueued-sender-com-spec{data-element=VeLINR_b_AGS2_CalStat, init-value=VeLINR_b_AGS2_CalStatValue:0}, provided-interface=VeLINR_b_AGS2_CalStat
      VeLINR_b_AGS2_CalStatTO: nonqueued-sender-com-spec{data-element=VeLINR_b_AGS2_CalStatTO, init-value=VeLINR_b_AGS2_CalStatTOValue:0}, provided-interface=VeLINR_b_AGS2_CalStatTO
      VeLINR_b_AGS2_CalActv: nonqueued-sender-com-spec{data-element=VeLINR_b_AGS2_CalActv, init-value=VeLINR_b_AGS2_CalActvValue:0}, provided-interface=VeLINR_b_AGS2_CalActv
      VeLINR_b_AGS2_CalActvTO: nonqueued-sender-com-spec{data-element=VeLINR_b_AGS2_CalActvTO, init-value=VeLINR_b_AGS2_CalActvTOValue:0}, provided-interface=VeLINR_b_AGS2_CalActvTO
      VeLINR_b_AGS2_ErrUnVolt: nonqueued-sender-com-spec{data-element=VeLINR_b_AGS2_ErrUnVolt, init-value=VeLINR_b_AGS2_ErrUnVoltValue:0}, provided-interface=VeLINR_b_AGS2_ErrUnVolt
      VeLINR_b_AGS2_ErrUnVoltTO: nonqueued-sender-com-spec{data-element=VeLINR_b_AGS2_ErrUnVoltTO, init-value=VeLINR_b_AGS2_ErrUnVoltTOValue:0}, provided-interface=VeLINR_b_AGS2_ErrUnVoltTO
      VeLINR_b_AGS2_ErrOvrVolt: nonqueued-sender-com-spec{data-element=VeLINR_b_AGS2_ErrOvrVolt, init-value=VeLINR_b_AGS2_ErrOvrVoltValue:0}, provided-interface=VeLINR_b_AGS2_ErrOvrVolt
      VeLINR_b_AGS2_ErrOvrVoltTO: nonqueued-sender-com-spec{data-element=VeLINR_b_AGS2_ErrOvrVoltTO, init-value=VeLINR_b_AGS2_ErrOvrVoltTOValue:0}, provided-interface=VeLINR_b_AGS2_ErrOvrVoltTO
      VeLINR_b_AGS2_ErrOvrTemp: nonqueued-sender-com-spec{data-element=VeLINR_b_AGS2_ErrOvrTemp, init-value=VeLINR_b_AGS2_ErrOvrTempValue:0}, provided-interface=VeLINR_b_AGS2_ErrOvrTemp
      VeLINR_b_AGS2_ErrOvrTempTO: nonqueued-sender-com-spec{data-element=VeLINR_b_AGS2_ErrOvrTempTO, init-value=VeLINR_b_AGS2_ErrOvrTempTOValue:0}, provided-interface=VeLINR_b_AGS2_ErrOvrTempTO
      VeLINR_b_AGS2_ErrMechStuck: nonqueued-sender-com-spec{data-element=VeLINR_b_AGS2_ErrMechStuck, init-value=VeLINR_b_AGS2_ErrMechStuckValue:0}, provided-interface=VeLINR_b_AGS2_ErrMechStuck
      VeLINR_b_AGS2_ErrMechStuckTO: nonqueued-sender-com-spec{data-element=VeLINR_b_AGS2_ErrMechStuckTO, init-value=VeLINR_b_AGS2_ErrMechStuckTOValue:0}, provided-interface=VeLINR_b_AGS2_ErrMechStuckTO
      VeLINR_b_AGS2_ErrMechBreak: nonqueued-sender-com-spec{data-element=VeLINR_b_AGS2_ErrMechBreak, init-value=VeLINR_b_AGS2_ErrMechBreakValue:0}, provided-interface=VeLINR_b_AGS2_ErrMechBreak
      VeLINR_b_AGS2_ErrMechBreakTO: nonqueued-sender-com-spec{data-element=VeLINR_b_AGS2_ErrMechBreakTO, init-value=VeLINR_b_AGS2_ErrMechBreakTOValue:0}, provided-interface=VeLINR_b_AGS2_ErrMechBreakTO
      VeLINR_e_AGS2_ErrLIN: nonqueued-sender-com-spec{data-element=VeLINR_e_AGS2_ErrLIN, init-value=VeLINR_e_AGS2_ErrLINValue:0}, provided-interface=VeLINR_e_AGS2_ErrLIN
      VeLINR_b_AGS2_ErrLIN_TO: nonqueued-sender-com-spec{data-element=VeLINR_b_AGS2_ErrLIN_TO, init-value=VeLINR_b_AGS2_ErrLIN_TOValue:0}, provided-interface=VeLINR_b_AGS2_ErrLIN_TO
      VeLINR_b_RsErr_AGS2: nonqueued-sender-com-spec{data-element=VeLINR_b_RsErr_AGS2, init-value=VeLINR_b_RsErr_AGS2Value:0}, provided-interface=VeLINR_b_RsErr_AGS2
      VeLINR_b_RsErr_AGS2TO: nonqueued-sender-com-spec{data-element=VeLINR_b_RsErr_AGS2TO, init-value=VeLINR_b_RsErr_AGS2TOValue:0}, provided-interface=VeLINR_b_RsErr_AGS2TO
      VeLINR_b_AGS2_BoostStat: nonqueued-sender-com-spec{data-element=VeLINR_b_AGS2_BoostStat, init-value=VeLINR_b_AGS2_BoostStatValue:0}, provided-interface=VeLINR_b_AGS2_BoostStat
      VeLINR_b_AGS2_BoostStatTO: nonqueued-sender-com-spec{data-element=VeLINR_b_AGS2_BoostStatTO, init-value=VeLINR_b_AGS2_BoostStatTOValue:0}, provided-interface=VeLINR_b_AGS2_BoostStatTO
      VeLINR_b_S2MResBit1_AGS2: nonqueued-sender-com-spec{data-element=VeLINR_b_S2MResBit1_AGS2, init-value=VeLINR_b_S2MResBit1_AGS2Value:0}, provided-interface=VeLINR_b_S2MResBit1_AGS2
      VeLINR_b_S2MResBit1_AGS2TO: nonqueued-sender-com-spec{data-element=VeLINR_b_S2MResBit1_AGS2TO, init-value=VeLINR_b_S2MResBit1_AGS2TOValue:0}, provided-interface=VeLINR_b_S2MResBit1_AGS2TO
      VeLINR_Pct_AHP_RPM_TGT_PERCT: nonqueued-sender-com-spec{data-element=VeLINR_Pct_AHP_RPM_TGT_PERCT, init-value=VeLINR_Pct_AHP_RPM_TGT_PERCTValue:100.3935}, provided-interface=VeLINR_Pct_AHP_RPM_TGT_PERCT
      VeLINR_b_AHP_RPM_TGT_PERCT_TO: nonqueued-sender-com-spec{data-element=VeLINR_b_AHP_RPM_TGT_PERCT_TO, init-value=VeLINR_b_AHP_RPM_TGT_PERCT_TOValue:0}, provided-interface=VeLINR_b_AHP_RPM_TGT_PERCT_TO
      VeLINR_Pct_AHP_RPM_ACTL_PERCT: nonqueued-sender-com-spec{data-element=VeLINR_Pct_AHP_RPM_ACTL_PERCT, init-value=VeLINR_Pct_AHP_RPM_ACTL_PERCTValue:100.3935}, provided-interface=VeLINR_Pct_AHP_RPM_ACTL_PERCT
      VeLINR_b_AHP_RPM_ACTL_PERCT_TO: nonqueued-sender-com-spec{data-element=VeLINR_b_AHP_RPM_ACTL_PERCT_TO, init-value=VeLINR_b_AHP_RPM_ACTL_PERCT_TOValue:0}, provided-interface=VeLINR_b_AHP_RPM_ACTL_PERCT_TO
      VeLINR_U_AHP_VLTG: nonqueued-sender-com-spec{data-element=VeLINR_U_AHP_VLTG, init-value=VeLINR_U_AHP_VLTGValue:25.5}, provided-interface=VeLINR_U_AHP_VLTG
      VeLINR_b_AHP_VLTG_TO: nonqueued-sender-com-spec{data-element=VeLINR_b_AHP_VLTG_TO, init-value=VeLINR_b_AHP_VLTG_TOValue:0}, provided-interface=VeLINR_b_AHP_VLTG_TO
      VeLINR_T_AHP_TEMP: nonqueued-sender-com-spec{data-element=VeLINR_T_AHP_TEMP, init-value=VeLINR_T_AHP_TEMPValue:205}, provided-interface=VeLINR_T_AHP_TEMP
      VeLINR_b_AHP_TEMP_TO: nonqueued-sender-com-spec{data-element=VeLINR_b_AHP_TEMP_TO, init-value=VeLINR_b_AHP_TEMP_TOValue:0}, provided-interface=VeLINR_b_AHP_TEMP_TO
      VeLINR_I_AHP_CURR: nonqueued-sender-com-spec{data-element=VeLINR_I_AHP_CURR, init-value=VeLINR_I_AHP_CURRValue:51}, provided-interface=VeLINR_I_AHP_CURR
      VeLINR_b_AHP_CURR_TO: nonqueued-sender-com-spec{data-element=VeLINR_b_AHP_CURR_TO, init-value=VeLINR_b_AHP_CURR_TOValue:0}, provided-interface=VeLINR_b_AHP_CURR_TO
      VeLINR_e_AHP_FL_SAFE_ACTVTD: nonqueued-sender-com-spec{data-element=VeLINR_e_AHP_FL_SAFE_ACTVTD, init-value=VeLINR_e_AHP_FL_SAFE_ACTVTDValue:3}, provided-interface=VeLINR_e_AHP_FL_SAFE_ACTVTD
      VeLINR_b_AHP_FL_SAFE_ACTVTD_TO: nonqueued-sender-com-spec{data-element=VeLINR_b_AHP_FL_SAFE_ACTVTD_TO, init-value=VeLINR_b_AHP_FL_SAFE_ACTVTD_TOValue:0}, provided-interface=VeLINR_b_AHP_FL_SAFE_ACTVTD_TO
      VeLINR_e_AHP_LMP_HM_AN_ON: nonqueued-sender-com-spec{data-element=VeLINR_e_AHP_LMP_HM_AN_ON, init-value=VeLINR_e_AHP_LMP_HM_AN_ONValue:3}, provided-interface=VeLINR_e_AHP_LMP_HM_AN_ON
      VeLINR_b_AHP_LMP_HM_AN_ON_TO: nonqueued-sender-com-spec{data-element=VeLINR_b_AHP_LMP_HM_AN_ON_TO, init-value=VeLINR_b_AHP_LMP_HM_AN_ON_TOValue:0}, provided-interface=VeLINR_b_AHP_LMP_HM_AN_ON_TO
      VeLINR_e_AHP_AIR_PRE_ERR: nonqueued-sender-com-spec{data-element=VeLINR_e_AHP_AIR_PRE_ERR, init-value=VeLINR_e_AHP_AIR_PRE_ERRValue:3}, provided-interface=VeLINR_e_AHP_AIR_PRE_ERR
      VeLINR_b_AHP_AIR_PRE_ERR_TO: nonqueued-sender-com-spec{data-element=VeLINR_b_AHP_AIR_PRE_ERR_TO, init-value=VeLINR_b_AHP_AIR_PRE_ERR_TOValue:0}, provided-interface=VeLINR_b_AHP_AIR_PRE_ERR_TO
      VeLINR_e_AHP_OVR_TMP_ERR: nonqueued-sender-com-spec{data-element=VeLINR_e_AHP_OVR_TMP_ERR, init-value=VeLINR_e_AHP_OVR_TMP_ERRValue:3}, provided-interface=VeLINR_e_AHP_OVR_TMP_ERR
      VeLINR_b_AHP_OVR_TMP_ERR_TO: nonqueued-sender-com-spec{data-element=VeLINR_b_AHP_OVR_TMP_ERR_TO, init-value=VeLINR_b_AHP_OVR_TMP_ERR_TOValue:0}, provided-interface=VeLINR_b_AHP_OVR_TMP_ERR_TO
      VeLINR_e_AHP_OVR_CUR_ERR: nonqueued-sender-com-spec{data-element=VeLINR_e_AHP_OVR_CUR_ERR, init-value=VeLINR_e_AHP_OVR_CUR_ERRValue:3}, provided-interface=VeLINR_e_AHP_OVR_CUR_ERR
      VeLINR_b_AHP_OVR_CUR_ERR_TO: nonqueued-sender-com-spec{data-element=VeLINR_b_AHP_OVR_CUR_ERR_TO, init-value=VeLINR_b_AHP_OVR_CUR_ERR_TOValue:0}, provided-interface=VeLINR_b_AHP_OVR_CUR_ERR_TO
      VeLINR_e_AHP_DR_RN_ERR: nonqueued-sender-com-spec{data-element=VeLINR_e_AHP_DR_RN_ERR, init-value=VeLINR_e_AHP_DR_RN_ERRValue:3}, provided-interface=VeLINR_e_AHP_DR_RN_ERR
      VeLINR_b_AHP_DR_RN_ERR_TO: nonqueued-sender-com-spec{data-element=VeLINR_b_AHP_DR_RN_ERR_TO, init-value=VeLINR_b_AHP_DR_RN_ERR_TOValue:0}, provided-interface=VeLINR_b_AHP_DR_RN_ERR_TO
      VeLINR_e_AHP_VLTG_ERR: nonqueued-sender-com-spec{data-element=VeLINR_e_AHP_VLTG_ERR, init-value=VeLINR_e_AHP_VLTG_ERRValue:3}, provided-interface=VeLINR_e_AHP_VLTG_ERR
      VeLINR_b_AHP_VLTG_ERR_TO: nonqueued-sender-com-spec{data-element=VeLINR_b_AHP_VLTG_ERR_TO, init-value=VeLINR_b_AHP_VLTG_ERR_TOValue:0}, provided-interface=VeLINR_b_AHP_VLTG_ERR_TO
      VeLINR_e_AHP_DBLK_ACTV: nonqueued-sender-com-spec{data-element=VeLINR_e_AHP_DBLK_ACTV, init-value=VeLINR_e_AHP_DBLK_ACTVValue:3}, provided-interface=VeLINR_e_AHP_DBLK_ACTV
      VeLINR_b_AHP_DBLK_ACTV_TO: nonqueued-sender-com-spec{data-element=VeLINR_b_AHP_DBLK_ACTV_TO, init-value=VeLINR_b_AHP_DBLK_ACTV_TOValue:0}, provided-interface=VeLINR_b_AHP_DBLK_ACTV_TO
      VeLINR_e_AHP_MONTRNG_RPM: nonqueued-sender-com-spec{data-element=VeLINR_e_AHP_MONTRNG_RPM, init-value=VeLINR_e_AHP_MONTRNG_RPMValue:3}, provided-interface=VeLINR_e_AHP_MONTRNG_RPM
      VeLINR_b_AHP_MONTRNG_RPM_TO: nonqueued-sender-com-spec{data-element=VeLINR_b_AHP_MONTRNG_RPM_TO, init-value=VeLINR_b_AHP_MONTRNG_RPM_TOValue:0}, provided-interface=VeLINR_b_AHP_MONTRNG_RPM_TO
      VeLINR_e_AHP_NODE_ERR: nonqueued-sender-com-spec{data-element=VeLINR_e_AHP_NODE_ERR, init-value=VeLINR_e_AHP_NODE_ERRValue:3}, provided-interface=VeLINR_e_AHP_NODE_ERR
      VeLINR_b_AHP_NODE_ERR_TO: nonqueued-sender-com-spec{data-element=VeLINR_b_AHP_NODE_ERR_TO, init-value=VeLINR_b_AHP_NODE_ERR_TOValue:0}, provided-interface=VeLINR_b_AHP_NODE_ERR_TO
      VeLINR_e_AHP_POST_RUN_STAT: nonqueued-sender-com-spec{data-element=VeLINR_e_AHP_POST_RUN_STAT, init-value=VeLINR_e_AHP_POST_RUN_STATValue:7}, provided-interface=VeLINR_e_AHP_POST_RUN_STAT
      VeLINR_b_AHP_POST_RUN_STAT_TO: nonqueued-sender-com-spec{data-element=VeLINR_b_AHP_POST_RUN_STAT_TO, init-value=VeLINR_b_AHP_POST_RUN_STAT_TOValue:0}, provided-interface=VeLINR_b_AHP_POST_RUN_STAT_TO
      VeLINR_b_RsErr_AHP_PUMP: nonqueued-sender-com-spec{data-element=VeLINR_b_RsErr_AHP_PUMP, init-value=VeLINR_b_RsErr_AHP_PUMPValue:0}, provided-interface=VeLINR_b_RsErr_AHP_PUMP
      VeLINR_b_RsErr_AHP_PUMP_TO: nonqueued-sender-com-spec{data-element=VeLINR_b_RsErr_AHP_PUMP_TO, init-value=VeLINR_b_RsErr_AHP_PUMP_TOValue:0}, provided-interface=VeLINR_b_RsErr_AHP_PUMP_TO
      VeLINR_e_AHP_SUPPLIER: nonqueued-sender-com-spec{data-element=VeLINR_e_AHP_SUPPLIER, init-value=VeLINR_e_AHP_SUPPLIERValue:0}, provided-interface=VeLINR_e_AHP_SUPPLIER
      VeLINR_b_AHP_SUPPLIER_TO: nonqueued-sender-com-spec{data-element=VeLINR_b_AHP_SUPPLIER_TO, init-value=VeLINR_b_AHP_SUPPLIER_TOValue:0}, provided-interface=VeLINR_b_AHP_SUPPLIER_TO
      VeLINR_Pct_BHV_PosAct: nonqueued-sender-com-spec{data-element=VeLINR_Pct_BHV_PosAct, init-value=VeLINR_Pct_BHV_PosActValue:0}, provided-interface=VeLINR_Pct_BHV_PosAct
      VeLINR_b_BHV_PosActTO: nonqueued-sender-com-spec{data-element=VeLINR_b_BHV_PosActTO, init-value=VeLINR_b_BHV_PosActTOValue:0}, provided-interface=VeLINR_b_BHV_PosActTO
      VeLINR_e_BHV_ERR: nonqueued-sender-com-spec{data-element=VeLINR_e_BHV_ERR, init-value=VeLINR_e_BHV_ERRValue:0}, provided-interface=VeLINR_e_BHV_ERR
      VeLINR_b_BHV_ERR_TO: nonqueued-sender-com-spec{data-element=VeLINR_b_BHV_ERR_TO, init-value=VeLINR_b_BHV_ERR_TOValue:0}, provided-interface=VeLINR_b_BHV_ERR_TO
      VeLINR_e_BHV_Sts: nonqueued-sender-com-spec{data-element=VeLINR_e_BHV_Sts, init-value=VeLINR_e_BHV_StsValue:0}, provided-interface=VeLINR_e_BHV_Sts
      VeLINR_b_BHV_StsTO: nonqueued-sender-com-spec{data-element=VeLINR_b_BHV_StsTO, init-value=VeLINR_b_BHV_StsTOValue:0}, provided-interface=VeLINR_b_BHV_StsTO
      VeLINR_b_RsErr_BHV: nonqueued-sender-com-spec{data-element=VeLINR_b_RsErr_BHV, init-value=VeLINR_b_RsErr_BHVValue:0}, provided-interface=VeLINR_b_RsErr_BHV
      VeLINR_b_RsErr_BHV_TO: nonqueued-sender-com-spec{data-element=VeLINR_b_RsErr_BHV_TO, init-value=VeLINR_b_RsErr_BHV_TOValue:0}, provided-interface=VeLINR_b_RsErr_BHV_TO
      VeLINR_e_CompFaultStat: nonqueued-sender-com-spec{data-element=VeLINR_e_CompFaultStat, init-value=VeLINR_e_CompFaultStatValue:0}, provided-interface=VeLINR_e_CompFaultStat
      VeLINR_b_CompFaultStatTO: nonqueued-sender-com-spec{data-element=VeLINR_b_CompFaultStatTO, init-value=VeLINR_b_CompFaultStatTOValue:0}, provided-interface=VeLINR_b_CompFaultStatTO
      VeLINR_e_CompStat: nonqueued-sender-com-spec{data-element=VeLINR_e_CompStat, init-value=VeLINR_e_CompStatValue:0}, provided-interface=VeLINR_e_CompStat
      VeLINR_b_CompStatTO: nonqueued-sender-com-spec{data-element=VeLINR_b_CompStatTO, init-value=VeLINR_b_CompStatTOValue:0}, provided-interface=VeLINR_b_CompStatTO
      VeLINR_n_CompressorSpd: nonqueued-sender-com-spec{data-element=VeLINR_n_CompressorSpd, init-value=VeLINR_n_CompressorSpdValue:0}, provided-interface=VeLINR_n_CompressorSpd
      VeLINR_b_CompressorSpdTO: nonqueued-sender-com-spec{data-element=VeLINR_b_CompressorSpdTO, init-value=VeLINR_b_CompressorSpdTOValue:0}, provided-interface=VeLINR_b_CompressorSpdTO
      VeLINR_b_CompSpdIncrReq: nonqueued-sender-com-spec{data-element=VeLINR_b_CompSpdIncrReq, init-value=VeLINR_b_CompSpdIncrReqValue:0}, provided-interface=VeLINR_b_CompSpdIncrReq
      VeLINR_b_CompSpdIncrReqTO: nonqueued-sender-com-spec{data-element=VeLINR_b_CompSpdIncrReqTO, init-value=VeLINR_b_CompSpdIncrReqTOValue:0}, provided-interface=VeLINR_b_CompSpdIncrReqTO
      VeLINR_P_CompElecPwr: nonqueued-sender-com-spec{data-element=VeLINR_P_CompElecPwr, init-value=VeLINR_P_CompElecPwrValue:0}, provided-interface=VeLINR_P_CompElecPwr
      VeLINR_b_CompElecPwrTO: nonqueued-sender-com-spec{data-element=VeLINR_b_CompElecPwrTO, init-value=VeLINR_b_CompElecPwrTOValue:0}, provided-interface=VeLINR_b_CompElecPwrTO
      VeLINR_T_CompBoardTemp: nonqueued-sender-com-spec{data-element=VeLINR_T_CompBoardTemp, init-value=VeLINR_T_CompBoardTempValue:-40}, provided-interface=VeLINR_T_CompBoardTemp
      VeLINR_b_CompBoardTempTO: nonqueued-sender-com-spec{data-element=VeLINR_b_CompBoardTempTO, init-value=VeLINR_b_CompBoardTempTOValue:0}, provided-interface=VeLINR_b_CompBoardTempTO
      VeLINR_T_CompIGBTTemp: nonqueued-sender-com-spec{data-element=VeLINR_T_CompIGBTTemp, init-value=VeLINR_T_CompIGBTTempValue:-40}, provided-interface=VeLINR_T_CompIGBTTemp
      VeLINR_b_CompIGBTTempTO: nonqueued-sender-com-spec{data-element=VeLINR_b_CompIGBTTempTO, init-value=VeLINR_b_CompIGBTTempTOValue:0}, provided-interface=VeLINR_b_CompIGBTTempTO
      VeLINR_I_CompElecCurr: nonqueued-sender-com-spec{data-element=VeLINR_I_CompElecCurr, init-value=VeLINR_I_CompElecCurrValue:0}, provided-interface=VeLINR_I_CompElecCurr
      VeLINR_b_CompElecCurrTO: nonqueued-sender-com-spec{data-element=VeLINR_b_CompElecCurrTO, init-value=VeLINR_b_CompElecCurrTOValue:0}, provided-interface=VeLINR_b_CompElecCurrTO
      VeLINR_U_CompHVInput: nonqueued-sender-com-spec{data-element=VeLINR_U_CompHVInput, init-value=VeLINR_U_CompHVInputValue:0}, provided-interface=VeLINR_U_CompHVInput
      VeLINR_b_CompHVInputTO: nonqueued-sender-com-spec{data-element=VeLINR_b_CompHVInputTO, init-value=VeLINR_b_CompHVInputTOValue:0}, provided-interface=VeLINR_b_CompHVInputTO
      VeLINR_e_DriveMdReq: nonqueued-sender-com-spec{data-element=VeLINR_e_DriveMdReq, init-value=VeLINR_e_DriveMdReqValue:0}, provided-interface=VeLINR_e_DriveMdReq
      VeLINR_b_DriveMdReqTO: nonqueued-sender-com-spec{data-element=VeLINR_b_DriveMdReqTO, init-value=VeLINR_b_DriveMdReqTOValue:0}, provided-interface=VeLINR_b_DriveMdReqTO
      VeLINR_e_HybridModeRq_LIN: nonqueued-sender-com-spec{data-element=VeLINR_e_HybridModeRq_LIN, init-value=VeLINR_e_HybridModeRq_LINValue:0}, provided-interface=VeLINR_e_HybridModeRq_LIN
      VeLINR_b_HybridModeRq_LIN_TO: nonqueued-sender-com-spec{data-element=VeLINR_b_HybridModeRq_LIN_TO, init-value=VeLINR_b_HybridModeRq_LIN_TOValue:0}, provided-interface=VeLINR_b_HybridModeRq_LIN_TO
      VeLINR_e_ESaveModeRq_LIN: nonqueued-sender-com-spec{data-element=VeLINR_e_ESaveModeRq_LIN, init-value=VeLINR_e_ESaveModeRq_LINValue:0}, provided-interface=VeLINR_e_ESaveModeRq_LIN
      VeLINR_b_ESaveModeRq_LIN_TO: nonqueued-sender-com-spec{data-element=VeLINR_b_ESaveModeRq_LIN_TO, init-value=VeLINR_b_ESaveModeRq_LIN_TOValue:0}, provided-interface=VeLINR_b_ESaveModeRq_LIN_TO
      VeLINR_e_ElectricModeRq_LIN: nonqueued-sender-com-spec{data-element=VeLINR_e_ElectricModeRq_LIN, init-value=VeLINR_e_ElectricModeRq_LINValue:0}, provided-interface=VeLINR_e_ElectricModeRq_LIN
      VeLINR_b_ElectricModeRq_LIN_TO: nonqueued-sender-com-spec{data-element=VeLINR_b_ElectricModeRq_LIN_TO, init-value=VeLINR_b_ElectricModeRq_LIN_TOValue:0}, provided-interface=VeLINR_b_ElectricModeRq_LIN_TO
      VeLINR_b_RsErr_ESBM: nonqueued-sender-com-spec{data-element=VeLINR_b_RsErr_ESBM, init-value=VeLINR_b_RsErr_ESBMValue:0}, provided-interface=VeLINR_b_RsErr_ESBM
      VeLINR_b_RsErr_ESBM_TO: nonqueued-sender-com-spec{data-element=VeLINR_b_RsErr_ESBM_TO, init-value=VeLINR_b_RsErr_ESBM_TOValue:0}, provided-interface=VeLINR_b_RsErr_ESBM_TO
      VeLINR_b_Refrig_Temp_LIN2TO: nonqueued-sender-com-spec{data-element=VeLINR_b_Refrig_Temp_LIN2TO, init-value=VeLINR_b_Refrig_Temp_LIN2TOValue:0}, provided-interface=VeLINR_b_Refrig_Temp_LIN2TO
      VeLINR_Pct_PECP_RPM_TGT_PERCT: nonqueued-sender-com-spec{data-element=VeLINR_Pct_PECP_RPM_TGT_PERCT, init-value=VeLINR_Pct_PECP_RPM_TGT_PERCTValue:100.3935}, provided-interface=VeLINR_Pct_PECP_RPM_TGT_PERCT
      VeLINR_b_PECP_RPM_TGT_PERCT_TO: nonqueued-sender-com-spec{data-element=VeLINR_b_PECP_RPM_TGT_PERCT_TO, init-value=VeLINR_b_PECP_RPM_TGT_PERCT_TOValue:0}, provided-interface=VeLINR_b_PECP_RPM_TGT_PERCT_TO
      VeLINR_Pct_PECP_RPM_ACTL_PERCT: nonqueued-sender-com-spec{data-element=VeLINR_Pct_PECP_RPM_ACTL_PERCT, init-value=VeLINR_Pct_PECP_RPM_ACTL_PERCTValue:100.3935}, provided-interface=VeLINR_Pct_PECP_RPM_ACTL_PERCT
      VeLINR_b_PECP_RPM_ACTL_PERCT_TO: nonqueued-sender-com-spec{data-element=VeLINR_b_PECP_RPM_ACTL_PERCT_TO, init-value=VeLINR_b_PECP_RPM_ACTL_PERCT_TOValue:0}, provided-interface=VeLINR_b_PECP_RPM_ACTL_PERCT_TO
      VeLINR_U_PECP_VLTG: nonqueued-sender-com-spec{data-element=VeLINR_U_PECP_VLTG, init-value=VeLINR_U_PECP_VLTGValue:25.5}, provided-interface=VeLINR_U_PECP_VLTG
      VeLINR_b_PECP_VLTG_TO: nonqueued-sender-com-spec{data-element=VeLINR_b_PECP_VLTG_TO, init-value=VeLINR_b_PECP_VLTG_TOValue:0}, provided-interface=VeLINR_b_PECP_VLTG_TO
      VeLINR_T_PECP_TEMP: nonqueued-sender-com-spec{data-element=VeLINR_T_PECP_TEMP, init-value=VeLINR_T_PECP_TEMPValue:205}, provided-interface=VeLINR_T_PECP_TEMP
      VeLINR_b_PECP_TEMP_TO: nonqueued-sender-com-spec{data-element=VeLINR_b_PECP_TEMP_TO, init-value=VeLINR_b_PECP_TEMP_TOValue:0}, provided-interface=VeLINR_b_PECP_TEMP_TO
      VeLINR_I_PECP_CURR: nonqueued-sender-com-spec{data-element=VeLINR_I_PECP_CURR, init-value=VeLINR_I_PECP_CURRValue:51}, provided-interface=VeLINR_I_PECP_CURR
      VeLINR_b_PECP_CURR_TO: nonqueued-sender-com-spec{data-element=VeLINR_b_PECP_CURR_TO, init-value=VeLINR_b_PECP_CURR_TOValue:0}, provided-interface=VeLINR_b_PECP_CURR_TO
      VeLINR_e_PECP_FL_SAFE_ACTVTD: nonqueued-sender-com-spec{data-element=VeLINR_e_PECP_FL_SAFE_ACTVTD, init-value=VeLINR_e_PECP_FL_SAFE_ACTVTDValue:3}, provided-interface=VeLINR_e_PECP_FL_SAFE_ACTVTD
      VeLINR_b_PECP_FL_SAFE_ACTVTD_TO: nonqueued-sender-com-spec{data-element=VeLINR_b_PECP_FL_SAFE_ACTVTD_TO, init-value=VeLINR_b_PECP_FL_SAFE_ACTVTD_TOValue:0}, provided-interface=VeLINR_b_PECP_FL_SAFE_ACTVTD_TO
      VeLINR_e_PECP_LMP_HM_AN_ON: nonqueued-sender-com-spec{data-element=VeLINR_e_PECP_LMP_HM_AN_ON, init-value=VeLINR_e_PECP_LMP_HM_AN_ONValue:3}, provided-interface=VeLINR_e_PECP_LMP_HM_AN_ON
      VeLINR_b_PECP_LMP_HM_AN_ON_TO: nonqueued-sender-com-spec{data-element=VeLINR_b_PECP_LMP_HM_AN_ON_TO, init-value=VeLINR_b_PECP_LMP_HM_AN_ON_TOValue:0}, provided-interface=VeLINR_b_PECP_LMP_HM_AN_ON_TO
      VeLINR_e_PECP_AIR_PRE_ERR: nonqueued-sender-com-spec{data-element=VeLINR_e_PECP_AIR_PRE_ERR, init-value=VeLINR_e_PECP_AIR_PRE_ERRValue:3}, provided-interface=VeLINR_e_PECP_AIR_PRE_ERR
      VeLINR_b_PECP_AIR_PRE_ERR_TO: nonqueued-sender-com-spec{data-element=VeLINR_b_PECP_AIR_PRE_ERR_TO, init-value=VeLINR_b_PECP_AIR_PRE_ERR_TOValue:0}, provided-interface=VeLINR_b_PECP_AIR_PRE_ERR_TO
      VeLINR_e_PECP_OVR_TMP_ERR: nonqueued-sender-com-spec{data-element=VeLINR_e_PECP_OVR_TMP_ERR, init-value=VeLINR_e_PECP_OVR_TMP_ERRValue:3}, provided-interface=VeLINR_e_PECP_OVR_TMP_ERR
      VeLINR_b_PECP_OVR_TMP_ERR_TO: nonqueued-sender-com-spec{data-element=VeLINR_b_PECP_OVR_TMP_ERR_TO, init-value=VeLINR_b_PECP_OVR_TMP_ERR_TOValue:0}, provided-interface=VeLINR_b_PECP_OVR_TMP_ERR_TO
      VeLINR_e_PECP_OVR_CUR_ERR: nonqueued-sender-com-spec{data-element=VeLINR_e_PECP_OVR_CUR_ERR, init-value=VeLINR_e_PECP_OVR_CUR_ERRValue:3}, provided-interface=VeLINR_e_PECP_OVR_CUR_ERR
      VeLINR_b_PECP_OVR_CUR_ERR_TO: nonqueued-sender-com-spec{data-element=VeLINR_b_PECP_OVR_CUR_ERR_TO, init-value=VeLINR_b_PECP_OVR_CUR_ERR_TOValue:0}, provided-interface=VeLINR_b_PECP_OVR_CUR_ERR_TO
      VeLINR_e_PECP_DR_RN_ERR: nonqueued-sender-com-spec{data-element=VeLINR_e_PECP_DR_RN_ERR, init-value=VeLINR_e_PECP_DR_RN_ERRValue:3}, provided-interface=VeLINR_e_PECP_DR_RN_ERR
      VeLINR_b_PECP_DR_RN_ERR_TO: nonqueued-sender-com-spec{data-element=VeLINR_b_PECP_DR_RN_ERR_TO, init-value=VeLINR_b_PECP_DR_RN_ERR_TOValue:0}, provided-interface=VeLINR_b_PECP_DR_RN_ERR_TO
      VeLINR_e_PECP_VLTG_ERR: nonqueued-sender-com-spec{data-element=VeLINR_e_PECP_VLTG_ERR, init-value=VeLINR_e_PECP_VLTG_ERRValue:3}, provided-interface=VeLINR_e_PECP_VLTG_ERR
      VeLINR_b_PECP_VLTG_ERR_TO: nonqueued-sender-com-spec{data-element=VeLINR_b_PECP_VLTG_ERR_TO, init-value=VeLINR_b_PECP_VLTG_ERR_TOValue:0}, provided-interface=VeLINR_b_PECP_VLTG_ERR_TO
      VeLINR_e_PECP_DBLK_ACTV: nonqueued-sender-com-spec{data-element=VeLINR_e_PECP_DBLK_ACTV, init-value=VeLINR_e_PECP_DBLK_ACTVValue:3}, provided-interface=VeLINR_e_PECP_DBLK_ACTV
      VeLINR_b_PECP_DBLK_ACTV_TO: nonqueued-sender-com-spec{data-element=VeLINR_b_PECP_DBLK_ACTV_TO, init-value=VeLINR_b_PECP_DBLK_ACTV_TOValue:0}, provided-interface=VeLINR_b_PECP_DBLK_ACTV_TO
      VeLINR_e_PECP_MONTRNG_RPM: nonqueued-sender-com-spec{data-element=VeLINR_e_PECP_MONTRNG_RPM, init-value=VeLINR_e_PECP_MONTRNG_RPMValue:3}, provided-interface=VeLINR_e_PECP_MONTRNG_RPM
      VeLINR_b_PECP_MONTRNG_RPM_TO: nonqueued-sender-com-spec{data-element=VeLINR_b_PECP_MONTRNG_RPM_TO, init-value=VeLINR_b_PECP_MONTRNG_RPM_TOValue:0}, provided-interface=VeLINR_b_PECP_MONTRNG_RPM_TO
      VeLINR_e_PECP_NODE_ERR: nonqueued-sender-com-spec{data-element=VeLINR_e_PECP_NODE_ERR, init-value=VeLINR_e_PECP_NODE_ERRValue:3}, provided-interface=VeLINR_e_PECP_NODE_ERR
      VeLINR_b_PECP_NODE_ERR_TO: nonqueued-sender-com-spec{data-element=VeLINR_b_PECP_NODE_ERR_TO, init-value=VeLINR_b_PECP_NODE_ERR_TOValue:0}, provided-interface=VeLINR_b_PECP_NODE_ERR_TO
      VeLINR_e_PECP_POST_RUN_STAT: nonqueued-sender-com-spec{data-element=VeLINR_e_PECP_POST_RUN_STAT, init-value=VeLINR_e_PECP_POST_RUN_STATValue:7}, provided-interface=VeLINR_e_PECP_POST_RUN_STAT
      VeLINR_b_PECP_POST_RUN_STAT_TO: nonqueued-sender-com-spec{data-element=VeLINR_b_PECP_POST_RUN_STAT_TO, init-value=VeLINR_b_PECP_POST_RUN_STAT_TOValue:0}, provided-interface=VeLINR_b_PECP_POST_RUN_STAT_TO
      VeLINR_b_RsErr_PECP_PUMP: nonqueued-sender-com-spec{data-element=VeLINR_b_RsErr_PECP_PUMP, init-value=VeLINR_b_RsErr_PECP_PUMPValue:0}, provided-interface=VeLINR_b_RsErr_PECP_PUMP
      VeLINR_b_RsErr_PECP_PUMP_TO: nonqueued-sender-com-spec{data-element=VeLINR_b_RsErr_PECP_PUMP_TO, init-value=VeLINR_b_RsErr_PECP_PUMP_TOValue:0}, provided-interface=VeLINR_b_RsErr_PECP_PUMP_TO
      VeLINR_e_PECP_SUPPLIER: nonqueued-sender-com-spec{data-element=VeLINR_e_PECP_SUPPLIER, init-value=VeLINR_e_PECP_SUPPLIERValue:0}, provided-interface=VeLINR_e_PECP_SUPPLIER
      VeLINR_b_PECP_SUPPLIER_TO: nonqueued-sender-com-spec{data-element=VeLINR_b_PECP_SUPPLIER_TO, init-value=VeLINR_b_PECP_SUPPLIER_TOValue:0}, provided-interface=VeLINR_b_PECP_SUPPLIER_TO
      VeLINR_I_PwrPanelCurrDrawSens1: nonqueued-sender-com-spec{data-element=VeLINR_I_PwrPanelCurrDrawSens1, init-value=VeLINR_I_PwrPanelCurrDrawSens1Value:0}, provided-interface=VeLINR_I_PwrPanelCurrDrawSens1
      VeLINR_b_PowerPanelButton_State: nonqueued-sender-com-spec{data-element=VeLINR_b_PowerPanelButton_State, init-value=VeLINR_b_PowerPanelButton_StateValue:0}, provided-interface=VeLINR_b_PowerPanelButton_State
      VeLINR_b_PowerPanelButton_StateTO: nonqueued-sender-com-spec{data-element=VeLINR_b_PowerPanelButton_StateTO, init-value=VeLINR_b_PowerPanelButton_StateTOValue:0}, provided-interface=VeLINR_b_PowerPanelButton_StateTO
      VeLINR_b_PwrPanelLidSwtSts120A: nonqueued-sender-com-spec{data-element=VeLINR_b_PwrPanelLidSwtSts120A, init-value=VeLINR_b_PwrPanelLidSwtSts120AValue:0}, provided-interface=VeLINR_b_PwrPanelLidSwtSts120A
      VeLINR_b_PwrPanelLidSwtSts120A_TO: nonqueued-sender-com-spec{data-element=VeLINR_b_PwrPanelLidSwtSts120A_TO, init-value=VeLINR_b_PwrPanelLidSwtSts120A_TOValue:0}, provided-interface=VeLINR_b_PwrPanelLidSwtSts120A_TO
      VeLINR_b_PwrPanelLidSwtSts120B: nonqueued-sender-com-spec{data-element=VeLINR_b_PwrPanelLidSwtSts120B, init-value=VeLINR_b_PwrPanelLidSwtSts120BValue:0}, provided-interface=VeLINR_b_PwrPanelLidSwtSts120B
      VeLINR_b_PwrPanelLidSwtSts120B_TO: nonqueued-sender-com-spec{data-element=VeLINR_b_PwrPanelLidSwtSts120B_TO, init-value=VeLINR_b_PwrPanelLidSwtSts120B_TOValue:0}, provided-interface=VeLINR_b_PwrPanelLidSwtSts120B_TO
      VeLINR_b_PwrPanelLidSwtSts240: nonqueued-sender-com-spec{data-element=VeLINR_b_PwrPanelLidSwtSts240, init-value=VeLINR_b_PwrPanelLidSwtSts240Value:0}, provided-interface=VeLINR_b_PwrPanelLidSwtSts240
      VeLINR_b_PwrPanelLidSwtSts240TO: nonqueued-sender-com-spec{data-element=VeLINR_b_PwrPanelLidSwtSts240TO, init-value=VeLINR_b_PwrPanelLidSwtSts240TOValue:0}, provided-interface=VeLINR_b_PwrPanelLidSwtSts240TO
      VeLINR_b_PwrPanelAC_PresntSens1: nonqueued-sender-com-spec{data-element=VeLINR_b_PwrPanelAC_PresntSens1, init-value=VeLINR_b_PwrPanelAC_PresntSens1Value:0}, provided-interface=VeLINR_b_PwrPanelAC_PresntSens1
      VeLINR_b_PwrPanelAC_PresntSens1TO: nonqueued-sender-com-spec{data-element=VeLINR_b_PwrPanelAC_PresntSens1TO, init-value=VeLINR_b_PwrPanelAC_PresntSens1TOValue:0}, provided-interface=VeLINR_b_PwrPanelAC_PresntSens1TO
      VeLINR_b_PwrPanelAC_PresntSens2: nonqueued-sender-com-spec{data-element=VeLINR_b_PwrPanelAC_PresntSens2, init-value=VeLINR_b_PwrPanelAC_PresntSens2Value:0}, provided-interface=VeLINR_b_PwrPanelAC_PresntSens2
      VeLINR_b_PwrPanelAC_PresntSens2TO: nonqueued-sender-com-spec{data-element=VeLINR_b_PwrPanelAC_PresntSens2TO, init-value=VeLINR_b_PwrPanelAC_PresntSens2TOValue:0}, provided-interface=VeLINR_b_PwrPanelAC_PresntSens2TO
      VeLINR_I_PwrPanelCurrDrawSens2: nonqueued-sender-com-spec{data-element=VeLINR_I_PwrPanelCurrDrawSens2, init-value=VeLINR_I_PwrPanelCurrDrawSens2Value:0}, provided-interface=VeLINR_I_PwrPanelCurrDrawSens2
      VeLINR_e_PowerPanel_FaultReason: nonqueued-sender-com-spec{data-element=VeLINR_e_PowerPanel_FaultReason, init-value=VeLINR_e_PowerPanel_FaultReasonValue:0}, provided-interface=VeLINR_e_PowerPanel_FaultReason
      VeLINR_b_PowerPanel_FaultReasonTO: nonqueued-sender-com-spec{data-element=VeLINR_b_PowerPanel_FaultReasonTO, init-value=VeLINR_b_PowerPanel_FaultReasonTOValue:0}, provided-interface=VeLINR_b_PowerPanel_FaultReasonTO
      VeLINR_b_RsErr_SPP: nonqueued-sender-com-spec{data-element=VeLINR_b_RsErr_SPP, init-value=VeLINR_b_RsErr_SPPValue:0}, provided-interface=VeLINR_b_RsErr_SPP
      VeLINR_b_RsErr_SPP_TO: nonqueued-sender-com-spec{data-element=VeLINR_b_RsErr_SPP_TO, init-value=VeLINR_b_RsErr_SPP_TOValue:0}, provided-interface=VeLINR_b_RsErr_SPP_TO
    71 x require port:
      SendLINR_AGS2_PosRq: nonqueued-receiver-com-spec{data-element=SendLINR_AGS2_PosRq, init-value=SendLINR_AGS2_PosRqValue:0}, required-interface=SendLINR_AGS2_PosRq
      SendLINR_AGS2_PosRqVld: nonqueued-receiver-com-spec{data-element=SendLINR_AGS2_PosRqVld, init-value=SendLINR_AGS2_PosRqVldValue:1}, required-interface=SendLINR_AGS2_PosRqVld
      SendLINR_AGS2_CalRq: nonqueued-receiver-com-spec{data-element=SendLINR_AGS2_CalRq, init-value=SendLINR_AGS2_CalRqValue:0}, required-interface=SendLINR_AGS2_CalRq
      SendLINR_AGS2_CalRqVld: nonqueued-receiver-com-spec{data-element=SendLINR_AGS2_CalRqVld, init-value=SendLINR_AGS2_CalRqVldValue:1}, required-interface=SendLINR_AGS2_CalRqVld
      SendLINR_AGS2_BoostRq: nonqueued-receiver-com-spec{data-element=SendLINR_AGS2_BoostRq, init-value=SendLINR_AGS2_BoostRqValue:0}, required-interface=SendLINR_AGS2_BoostRq
      SendLINR_AGS2_BoostRqVld: nonqueued-receiver-com-spec{data-element=SendLINR_AGS2_BoostRqVld, init-value=SendLINR_AGS2_BoostRqVldValue:1}, required-interface=SendLINR_AGS2_BoostRqVld
      SendLINR_M2SRes2Bit_AGS2: nonqueued-receiver-com-spec{data-element=SendLINR_M2SRes2Bit_AGS2, init-value=SendLINR_M2SRes2Bit_AGS2Value:0}, required-interface=SendLINR_M2SRes2Bit_AGS2
      SendLINR_M2SRes2Bit_AGS2Vld: nonqueued-receiver-com-spec{data-element=SendLINR_M2SRes2Bit_AGS2Vld, init-value=SendLINR_M2SRes2Bit_AGS2VldValue:1}, required-interface=SendLINR_M2SRes2Bit_AGS2Vld
      SendLINR_M2SResByte1_AGS2: nonqueued-receiver-com-spec{data-element=SendLINR_M2SResByte1_AGS2, init-value=SendLINR_M2SResByte1_AGS2Value:0}, required-interface=SendLINR_M2SResByte1_AGS2
      SendLINR_M2SResByte1_AGS2Vld: nonqueued-receiver-com-spec{data-element=SendLINR_M2SResByte1_AGS2Vld, init-value=SendLINR_M2SResByte1_AGS2VldValue:1}, required-interface=SendLINR_M2SResByte1_AGS2Vld
      SendLINR_M2SResByte2_AGS2: nonqueued-receiver-com-spec{data-element=SendLINR_M2SResByte2_AGS2, init-value=SendLINR_M2SResByte2_AGS2Value:0}, required-interface=SendLINR_M2SResByte2_AGS2
      SendLINR_M2SResByte2_AGS2Vld: nonqueued-receiver-com-spec{data-element=SendLINR_M2SResByte2_AGS2Vld, init-value=SendLINR_M2SResByte2_AGS2VldValue:1}, required-interface=SendLINR_M2SResByte2_AGS2Vld
      SendLINR_M2SResByte3_AGS2: nonqueued-receiver-com-spec{data-element=SendLINR_M2SResByte3_AGS2, init-value=SendLINR_M2SResByte3_AGS2Value:0}, required-interface=SendLINR_M2SResByte3_AGS2
      SendLINR_M2SResByte3_AGS2Vld: nonqueued-receiver-com-spec{data-element=SendLINR_M2SResByte3_AGS2Vld, init-value=SendLINR_M2SResByte3_AGS2VldValue:1}, required-interface=SendLINR_M2SResByte3_AGS2Vld
      SendLINR_AHP_RPM_REQ_PERCT: nonqueued-receiver-com-spec{data-element=SendLINR_AHP_RPM_REQ_PERCT, init-value=SendLINR_AHP_RPM_REQ_PERCTValue:100.3935}, required-interface=SendLINR_AHP_RPM_REQ_PERCT
      SendLINR_AHP_RPM_REQ_PERCT_Vld: nonqueued-receiver-com-spec{data-element=SendLINR_AHP_RPM_REQ_PERCT_Vld, init-value=SendLINR_AHP_RPM_REQ_PERCT_VldValue:1}, required-interface=SendLINR_AHP_RPM_REQ_PERCT_Vld
      SendLINR_AHP_POST_RUN_REQ: nonqueued-receiver-com-spec{data-element=SendLINR_AHP_POST_RUN_REQ, init-value=SendLINR_AHP_POST_RUN_REQValue:7}, required-interface=SendLINR_AHP_POST_RUN_REQ
      SendLINR_AHP_POST_RUN_REQ_Vld: nonqueued-receiver-com-spec{data-element=SendLINR_AHP_POST_RUN_REQ_Vld, init-value=SendLINR_AHP_POST_RUN_REQ_VldValue:1}, required-interface=SendLINR_AHP_POST_RUN_REQ_Vld
      SendLINR_AHP_FL_SAFE_ACTVT: nonqueued-receiver-com-spec{data-element=SendLINR_AHP_FL_SAFE_ACTVT, init-value=SendLINR_AHP_FL_SAFE_ACTVTValue:3}, required-interface=SendLINR_AHP_FL_SAFE_ACTVT
      SendLINR_AHP_FL_SAFE_ACTVT_Vld: nonqueued-receiver-com-spec{data-element=SendLINR_AHP_FL_SAFE_ACTVT_Vld, init-value=SendLINR_AHP_FL_SAFE_ACTVT_VldValue:1}, required-interface=SendLINR_AHP_FL_SAFE_ACTVT_Vld
      SendLINR_BHV_PosRq: nonqueued-receiver-com-spec{data-element=SendLINR_BHV_PosRq, init-value=SendLINR_BHV_PosRqValue:0}, required-interface=SendLINR_BHV_PosRq
      SendLINR_BHV_PosRqVld: nonqueued-receiver-com-spec{data-element=SendLINR_BHV_PosRqVld, init-value=SendLINR_BHV_PosRqVldValue:1}, required-interface=SendLINR_BHV_PosRqVld
      SendLINR_BHV_PosSv: nonqueued-receiver-com-spec{data-element=SendLINR_BHV_PosSv, init-value=SendLINR_BHV_PosSvValue:0}, required-interface=SendLINR_BHV_PosSv
      SendLINR_BHV_PosSvVld: nonqueued-receiver-com-spec{data-element=SendLINR_BHV_PosSvVld, init-value=SendLINR_BHV_PosSvVldValue:1}, required-interface=SendLINR_BHV_PosSvVld
      SendLINR_BHV_CalRq: nonqueued-receiver-com-spec{data-element=SendLINR_BHV_CalRq, init-value=SendLINR_BHV_CalRqValue:0}, required-interface=SendLINR_BHV_CalRq
      SendLINR_BHV_CalRqVld: nonqueued-receiver-com-spec{data-element=SendLINR_BHV_CalRqVld, init-value=SendLINR_BHV_CalRqVldValue:1}, required-interface=SendLINR_BHV_CalRqVld
      SendLINR_CompressorSpdReq: nonqueued-receiver-com-spec{data-element=SendLINR_CompressorSpdReq, init-value=SendLINR_CompressorSpdReqValue:0}, required-interface=SendLINR_CompressorSpdReq
      SendLINR_CompressorSpdReqVld: nonqueued-receiver-com-spec{data-element=SendLINR_CompressorSpdReqVld, init-value=SendLINR_CompressorSpdReqVldValue:1}, required-interface=SendLINR_CompressorSpdReqVld
      SendLINR_CompEnable: nonqueued-receiver-com-spec{data-element=SendLINR_CompEnable, init-value=SendLINR_CompEnableValue:3}, required-interface=SendLINR_CompEnable
      SendLINR_CompEnableVld: nonqueued-receiver-com-spec{data-element=SendLINR_CompEnableVld, init-value=SendLINR_CompEnableVldValue:1}, required-interface=SendLINR_CompEnableVld
      SendLINR_DriveEcohybridLmp: nonqueued-receiver-com-spec{data-element=SendLINR_DriveEcohybridLmp, init-value=SendLINR_DriveEcohybridLmpValue:0}, required-interface=SendLINR_DriveEcohybridLmp
      SendLINR_DriveEcohybridLmpVld: nonqueued-receiver-com-spec{data-element=SendLINR_DriveEcohybridLmpVld, init-value=SendLINR_DriveEcohybridLmpVldValue:1}, required-interface=SendLINR_DriveEcohybridLmpVld
      SendLINR_DriveElectricLmp: nonqueued-receiver-com-spec{data-element=SendLINR_DriveElectricLmp, init-value=SendLINR_DriveElectricLmpValue:0}, required-interface=SendLINR_DriveElectricLmp
      SendLINR_DriveElectricLmpVld: nonqueued-receiver-com-spec{data-element=SendLINR_DriveElectricLmpVld, init-value=SendLINR_DriveElectricLmpVldValue:1}, required-interface=SendLINR_DriveElectricLmpVld
      SendLINR_DriveESaveLmp: nonqueued-receiver-com-spec{data-element=SendLINR_DriveESaveLmp, init-value=SendLINR_DriveESaveLmpValue:0}, required-interface=SendLINR_DriveESaveLmp
      SendLINR_DriveESaveLmpVld: nonqueued-receiver-com-spec{data-element=SendLINR_DriveESaveLmpVld, init-value=SendLINR_DriveESaveLmpVldValue:1}, required-interface=SendLINR_DriveESaveLmpVld
      SendLINR_DriveSportHybridLmp: nonqueued-receiver-com-spec{data-element=SendLINR_DriveSportHybridLmp, init-value=SendLINR_DriveSportHybridLmpValue:0}, required-interface=SendLINR_DriveSportHybridLmp
      SendLINR_DriveSportHybridLmpVld: nonqueued-receiver-com-spec{data-element=SendLINR_DriveSportHybridLmpVld, init-value=SendLINR_DriveSportHybridLmpVldValue:1}, required-interface=SendLINR_DriveSportHybridLmpVld
      SendLINR_PanelIntensitySts: nonqueued-receiver-com-spec{data-element=SendLINR_PanelIntensitySts, init-value=SendLINR_PanelIntensityStsValue:0}, required-interface=SendLINR_PanelIntensitySts
      SendLINR_PanelIntensityStsVld: nonqueued-receiver-com-spec{data-element=SendLINR_PanelIntensityStsVld, init-value=SendLINR_PanelIntensityStsVldValue:1}, required-interface=SendLINR_PanelIntensityStsVld
      SendLINR_DAY_LGT_MD: nonqueued-receiver-com-spec{data-element=SendLINR_DAY_LGT_MD, init-value=SendLINR_DAY_LGT_MDValue:0}, required-interface=SendLINR_DAY_LGT_MD
      SendLINR_DAY_LGT_MD_Vld: nonqueued-receiver-com-spec{data-element=SendLINR_DAY_LGT_MD_Vld, init-value=SendLINR_DAY_LGT_MD_VldValue:1}, required-interface=SendLINR_DAY_LGT_MD_Vld
      SendLINR_PECP_RPM_REQ_PERCT: nonqueued-receiver-com-spec{data-element=SendLINR_PECP_RPM_REQ_PERCT, init-value=SendLINR_PECP_RPM_REQ_PERCTValue:100.3935}, required-interface=SendLINR_PECP_RPM_REQ_PERCT
      SendLINR_PECP_RPM_REQ_PERCT_Vld: nonqueued-receiver-com-spec{data-element=SendLINR_PECP_RPM_REQ_PERCT_Vld, init-value=SendLINR_PECP_RPM_REQ_PERCT_VldValue:1}, required-interface=SendLINR_PECP_RPM_REQ_PERCT_Vld
      SendLINR_PECP_POST_RUN_REQ_Vld: nonqueued-receiver-com-spec{data-element=SendLINR_PECP_POST_RUN_REQ_Vld, init-value=SendLINR_PECP_POST_RUN_REQ_VldValue:1}, required-interface=SendLINR_PECP_POST_RUN_REQ_Vld
      SendLINR_PECP_FL_SAFE_ACTVT: nonqueued-receiver-com-spec{data-element=SendLINR_PECP_FL_SAFE_ACTVT, init-value=SendLINR_PECP_FL_SAFE_ACTVTValue:3}, required-interface=SendLINR_PECP_FL_SAFE_ACTVT
      SendLINR_PECP_POST_RUN_REQ: nonqueued-receiver-com-spec{data-element=SendLINR_PECP_POST_RUN_REQ, init-value=SendLINR_PECP_POST_RUN_REQValue:7}, required-interface=SendLINR_PECP_POST_RUN_REQ
      SendLINR_PECP_FL_SAFE_ACTVT_Vld: nonqueued-receiver-com-spec{data-element=SendLINR_PECP_FL_SAFE_ACTVT_Vld, init-value=SendLINR_PECP_FL_SAFE_ACTVT_VldValue:1}, required-interface=SendLINR_PECP_FL_SAFE_ACTVT_Vld
      SendLINR_PwrPanel_LED_A_Command: nonqueued-receiver-com-spec{data-element=SendLINR_PwrPanel_LED_A_Command, init-value=SendLINR_PwrPanel_LED_A_CommandValue:0}, required-interface=SendLINR_PwrPanel_LED_A_Command
      SendLINR_PwrPanel_LED_A_CommandVld: nonqueued-receiver-com-spec{data-element=SendLINR_PwrPanel_LED_A_CommandVld, init-value=SendLINR_PwrPanel_LED_A_CommandVldValue:1}, required-interface=SendLINR_PwrPanel_LED_A_CommandVld
      SendLINR_PwrPanel_LED_B_Command: nonqueued-receiver-com-spec{data-element=SendLINR_PwrPanel_LED_B_Command, init-value=SendLINR_PwrPanel_LED_B_CommandValue:0}, required-interface=SendLINR_PwrPanel_LED_B_Command
      SendLINR_PwrPanel_LED_B_CommandVld: nonqueued-receiver-com-spec{data-element=SendLINR_PwrPanel_LED_B_CommandVld, init-value=SendLINR_PwrPanel_LED_B_CommandVldValue:1}, required-interface=SendLINR_PwrPanel_LED_B_CommandVld
      SendLINR_DAY_LGT_MD_PowerPanel: nonqueued-receiver-com-spec{data-element=SendLINR_DAY_LGT_MD_PowerPanel, init-value=SendLINR_DAY_LGT_MD_PowerPanelValue:0}, required-interface=SendLINR_DAY_LGT_MD_PowerPanel
      SendLINR_DAY_LGT_MD_PowerPanelVld: nonqueued-receiver-com-spec{data-element=SendLINR_DAY_LGT_MD_PowerPanelVld, init-value=SendLINR_DAY_LGT_MD_PowerPanelVldValue:1}, required-interface=SendLINR_DAY_LGT_MD_PowerPanelVld
      SignalLINR_AGS2_RdyForSleep: nonqueued-receiver-com-spec{data-element=SignalLINR_AGS2_RdyForSleep, init-value=SignalLINR_AGS2_RdyForSleepValue:0}, required-interface=SignalLINR_AGS2_RdyForSleep
      SignalLINR_AHP_RdyForSleep: nonqueued-receiver-com-spec{data-element=SignalLINR_AHP_RdyForSleep, init-value=SignalLINR_AHP_RdyForSleepValue:0}, required-interface=SignalLINR_AHP_RdyForSleep
      SignalLINR_BHV_RdyForSleep: nonqueued-receiver-com-spec{data-element=SignalLINR_BHV_RdyForSleep, init-value=SignalLINR_BHV_RdyForSleepValue:0}, required-interface=SignalLINR_BHV_RdyForSleep
      SignalLINR_EAC2_RdyForSleep: nonqueued-receiver-com-spec{data-element=SignalLINR_EAC2_RdyForSleep, init-value=SignalLINR_EAC2_RdyForSleepValue:0}, required-interface=SignalLINR_EAC2_RdyForSleep
      SignalLINR_ESBM_RdyForSleep: nonqueued-receiver-com-spec{data-element=SignalLINR_ESBM_RdyForSleep, init-value=SignalLINR_ESBM_RdyForSleepValue:0}, required-interface=SignalLINR_ESBM_RdyForSleep
      SignalLINR_OEXV_RdyForSleep: nonqueued-receiver-com-spec{data-element=SignalLINR_OEXV_RdyForSleep, init-value=SignalLINR_OEXV_RdyForSleepValue:0}, required-interface=SignalLINR_OEXV_RdyForSleep
      SignalLINR_PECP_RdyForSleep: nonqueued-receiver-com-spec{data-element=SignalLINR_PECP_RdyForSleep, init-value=SignalLINR_PECP_RdyForSleepValue:0}, required-interface=SignalLINR_PECP_RdyForSleep
      SignalLINR_SPP_RdyForSleep: nonqueued-receiver-com-spec{data-element=SignalLINR_SPP_RdyForSleep, init-value=SignalLINR_SPP_RdyForSleepValue:0}, required-interface=SignalLINR_SPP_RdyForSleep
      KeCFGR_b_AGS2_Equid: parameter-require-com-spec{init-value=Value:0, parameter=KeCFGR_b_AGS2_Equid}, required-interface=KeCFGR_b_AGS2_Equid
      KeCFGR_b_AHP_Equid: parameter-require-com-spec{init-value=Value:0, parameter=KeCFGR_b_AHP_Equid}, required-interface=KeCFGR_b_AHP_Equid
      KeCFGR_b_BHV_Equid: parameter-require-com-spec{init-value=Value:0, parameter=KeCFGR_b_BHV_Equid}, required-interface=KeCFGR_b_BHV_Equid
      KeCFGR_b_EAC2_Equid: parameter-require-com-spec{init-value=Value:0, parameter=KeCFGR_b_EAC2_Equid}, required-interface=KeCFGR_b_EAC2_Equid
      KeCFGR_b_ESBM_Equid: parameter-require-com-spec{init-value=Value:0, parameter=KeCFGR_b_ESBM_Equid}, required-interface=KeCFGR_b_ESBM_Equid
      KeCFGR_b_OEXV_Equid: parameter-require-com-spec{init-value=Value:0, parameter=KeCFGR_b_OEXV_Equid}, required-interface=KeCFGR_b_OEXV_Equid
      KeCFGR_b_PECP_Equid: parameter-require-com-spec{init-value=Value:0, parameter=KeCFGR_b_PECP_Equid}, required-interface=KeCFGR_b_PECP_Equid
      KeCFGR_b_SPP_Equid: parameter-require-com-spec{init-value=Value:0, parameter=KeCFGR_b_SPP_Equid}, required-interface=KeCFGR_b_SPP_Equid
      KeLINR_y_LIN2SwtSchdTbl: parameter-require-com-spec{init-value=Value:0, parameter=KeLINR_y_LIN2SwtSchdTbl}, required-interface=KeLINR_y_LIN2SwtSchdTbl
    34 x provide port:
      ApplLinComAbLin2EquidMN: mode-switch-sender-com-spec{mode-group=MDGP_MSI_Lin2Equid, queue-length=1}, provided-interface=MSI_Lin2Equid
      VeLINR_d_LIN_SlavePrsntSts_LIN2: nonqueued-sender-com-spec{data-element=VeLINR_d_LIN_SlavePrsntSts_LIN2, init-value=Value:0}, provided-interface=VeLINR_d_LIN_SlavePrsntSts_LIN2
      VeLINR_y_AHP_VERSION: nonqueued-sender-com-spec{data-element=VeLINR_y_AHP_VERSION, init-value=VeLINR_y_AHP_VERSIONValue:255}, provided-interface=VeLINR_y_AHP_VERSION
      VeLINR_b_AHP_VERSION_TO: nonqueued-sender-com-spec{data-element=VeLINR_b_AHP_VERSION_TO, init-value=VeLINR_b_AHP_VERSION_TOValue:0}, provided-interface=VeLINR_b_AHP_VERSION_TO
      VeLINR_y_PECP_VERSION: nonqueued-sender-com-spec{data-element=VeLINR_y_PECP_VERSION, init-value=VeLINR_y_PECP_VERSIONValue:255}, provided-interface=VeLINR_y_PECP_VERSION
      VeLINR_b_PECP_VERSION_TO: nonqueued-sender-com-spec{data-element=VeLINR_b_PECP_VERSION_TO, init-value=VeLINR_b_PECP_VERSION_TOValue:0}, provided-interface=VeLINR_b_PECP_VERSION_TO
      VeLINR_e_S2MResByte1_AGS2: nonqueued-sender-com-spec{data-element=VeLINR_e_S2MResByte1_AGS2, init-value=VeLINR_e_S2MResByte1_AGS2Value:0}, provided-interface=VeLINR_e_S2MResByte1_AGS2
      VeLINR_b_S2MResByte1_AGS2TO: nonqueued-sender-com-spec{data-element=VeLINR_b_S2MResByte1_AGS2TO, init-value=VeLINR_b_S2MResByte1_AGS2TOValue:0}, provided-interface=VeLINR_b_S2MResByte1_AGS2TO
      VeLINR_e_S2MResByte2_AGS2: nonqueued-sender-com-spec{data-element=VeLINR_e_S2MResByte2_AGS2, init-value=VeLINR_e_S2MResByte2_AGS2Value:0}, provided-interface=VeLINR_e_S2MResByte2_AGS2
      VeLINR_b_S2MResByte2_AGS2TO: nonqueued-sender-com-spec{data-element=VeLINR_b_S2MResByte2_AGS2TO, init-value=VeLINR_b_S2MResByte2_AGS2TOValue:0}, provided-interface=VeLINR_b_S2MResByte2_AGS2TO
      VeLINR_U_BHV_MotorVolt: nonqueued-sender-com-spec{data-element=VeLINR_U_BHV_MotorVolt, init-value=VeLINR_U_BHV_MotorVoltValue:0}, provided-interface=VeLINR_U_BHV_MotorVolt
      VeLINR_b_BHV_MotorVoltTO: nonqueued-sender-com-spec{data-element=VeLINR_b_BHV_MotorVoltTO, init-value=VeLINR_b_BHV_MotorVoltTOValue:0}, provided-interface=VeLINR_b_BHV_MotorVoltTO
      VeLINR_e_BHV_CalStat: nonqueued-sender-com-spec{data-element=VeLINR_e_BHV_CalStat, init-value=VeLINR_e_BHV_CalStatValue:0}, provided-interface=VeLINR_e_BHV_CalStat
      VeLINR_b_BHV_CalStatTO: nonqueued-sender-com-spec{data-element=VeLINR_b_BHV_CalStatTO, init-value=VeLINR_b_BHV_CalStatTOValue:0}, provided-interface=VeLINR_b_BHV_CalStatTO
      VeLINR_Pct_OEXV_PosAct: nonqueued-sender-com-spec{data-element=VeLINR_Pct_OEXV_PosAct, init-value=VeLINR_Pct_OEXV_PosActValue:0}, provided-interface=VeLINR_Pct_OEXV_PosAct
      VeLINR_b_OEXV_PosActTO: nonqueued-sender-com-spec{data-element=VeLINR_b_OEXV_PosActTO, init-value=VeLINR_b_OEXV_PosActTOValue:0}, provided-interface=VeLINR_b_OEXV_PosActTO
      VeLINR_e_OEXV_CalStat: nonqueued-sender-com-spec{data-element=VeLINR_e_OEXV_CalStat, init-value=VeLINR_e_OEXV_CalStatValue:0}, provided-interface=VeLINR_e_OEXV_CalStat
      VeLINR_b_OEXV_CalStatTO: nonqueued-sender-com-spec{data-element=VeLINR_b_OEXV_CalStatTO, init-value=VeLINR_b_OEXV_CalStatTOValue:0}, provided-interface=VeLINR_b_OEXV_CalStatTO
      VeLINR_b_OEXV_CalRq: nonqueued-sender-com-spec{data-element=VeLINR_b_OEXV_CalRq, init-value=VeLINR_b_OEXV_CalRqValue:0}, provided-interface=VeLINR_b_OEXV_CalRq
      VeLINR_b_OEXV_CalRqTO: nonqueued-sender-com-spec{data-element=VeLINR_b_OEXV_CalRqTO, init-value=VeLINR_b_OEXV_CalRqTOValue:0}, provided-interface=VeLINR_b_OEXV_CalRqTO
      VeLINR_b_RsErr_OEXV: nonqueued-sender-com-spec{data-element=VeLINR_b_RsErr_OEXV, init-value=VeLINR_b_RsErr_OEXVValue:0}, provided-interface=VeLINR_b_RsErr_OEXV
      VeLINR_b_RsErr_OEXV_TO: nonqueued-sender-com-spec{data-element=VeLINR_b_RsErr_OEXV_TO, init-value=VeLINR_b_RsErr_OEXV_TOValue:0}, provided-interface=VeLINR_b_RsErr_OEXV_TO
      VeLINR_e_OEXV_Sts: nonqueued-sender-com-spec{data-element=VeLINR_e_OEXV_Sts, init-value=VeLINR_e_OEXV_StsValue:0}, provided-interface=VeLINR_e_OEXV_Sts
      VeLINR_b_OEXV_StsTO: nonqueued-sender-com-spec{data-element=VeLINR_b_OEXV_StsTO, init-value=VeLINR_b_OEXV_StsTOValue:0}, provided-interface=VeLINR_b_OEXV_StsTO
      VeLINR_e_OEXV_ERR: nonqueued-sender-com-spec{data-element=VeLINR_e_OEXV_ERR, init-value=VeLINR_e_OEXV_ERRValue:0}, provided-interface=VeLINR_e_OEXV_ERR
      VeLINR_b_OEXV_ERR_TO: nonqueued-sender-com-spec{data-element=VeLINR_b_OEXV_ERR_TO, init-value=VeLINR_b_OEXV_ERR_TOValue:0}, provided-interface=VeLINR_b_OEXV_ERR_TO
      VeLINR_U_OEXV_SupplyVolt: nonqueued-sender-com-spec{data-element=VeLINR_U_OEXV_SupplyVolt, init-value=VeLINR_U_OEXV_SupplyVoltValue:0}, provided-interface=VeLINR_U_OEXV_SupplyVolt
      VeLINR_b_OEXV_SupplyVoltTO: nonqueued-sender-com-spec{data-element=VeLINR_b_OEXV_SupplyVoltTO, init-value=VeLINR_b_OEXV_SupplyVoltTOValue:0}, provided-interface=VeLINR_b_OEXV_SupplyVoltTO
      VeLINR_e_OEXV_Refrig_Pres: nonqueued-sender-com-spec{data-element=VeLINR_e_OEXV_Refrig_Pres, init-value=VeLINR_e_OEXV_Refrig_PresValue:8191.5}, provided-interface=VeLINR_e_OEXV_Refrig_Pres
      VeLINR_b_OEXV_Refrig_PresTO: nonqueued-sender-com-spec{data-element=VeLINR_b_OEXV_Refrig_PresTO, init-value=VeLINR_b_OEXV_Refrig_PresTOValue:0}, provided-interface=VeLINR_b_OEXV_Refrig_PresTO
      VeLINR_T_OEXV_Board_Temp: nonqueued-sender-com-spec{data-element=VeLINR_T_OEXV_Board_Temp, init-value=VeLINR_T_OEXV_Board_TempValue:-40}, provided-interface=VeLINR_T_OEXV_Board_Temp
      VeLINR_b_OEXV_Board_TempTO: nonqueued-sender-com-spec{data-element=VeLINR_b_OEXV_Board_TempTO, init-value=VeLINR_b_OEXV_Board_TempTOValue:0}, provided-interface=VeLINR_b_OEXV_Board_TempTO
      VeLINR_e_OEXV_Refrigerant_Temp: nonqueued-sender-com-spec{data-element=VeLINR_e_OEXV_Refrigerant_Temp, init-value=VeLINR_e_OEXV_Refrigerant_TempValue:-40}, provided-interface=VeLINR_e_OEXV_Refrigerant_Temp
      VeLINR_b_OEXV_Refrigerant_TempTO: nonqueued-sender-com-spec{data-element=VeLINR_b_OEXV_Refrigerant_TempTO, init-value=VeLINR_b_OEXV_Refrigerant_TempTOValue:0}, provided-interface=VeLINR_b_OEXV_Refrigerant_TempTO
    4 x require port:
      SendLINR_OEXV_PosRq: nonqueued-receiver-com-spec{data-element=SendLINR_OEXV_PosRq, init-value=SendLINR_OEXV_PosRqValue:0}, required-interface=SendLINR_OEXV_PosRq
      SendLINR_OEXV_PosRqVld: nonqueued-receiver-com-spec{data-element=SendLINR_OEXV_PosRqVld, init-value=SendLINR_OEXV_PosRqVldValue:1}, required-interface=SendLINR_OEXV_PosRqVld
      SendLINR_OEXV_CalCmd: nonqueued-receiver-com-spec{data-element=SendLINR_OEXV_CalCmd, init-value=SendLINR_OEXV_CalCmdValue:0}, required-interface=SendLINR_OEXV_CalCmd
      SendLINR_OEXV_CalCmdVld: nonqueued-receiver-com-spec{data-element=SendLINR_OEXV_CalCmdVld, init-value=SendLINR_OEXV_CalCmdVldValue:1}, required-interface=SendLINR_OEXV_CalCmdVld
    20 x provide port:
      VeLINR_e_CompFaultStat_800: nonqueued-sender-com-spec{data-element=VeLINR_e_CompFaultStat_800, init-value=VeLINR_e_CompFaultStat_800Value:0}, provided-interface=VeLINR_e_CompFaultStat_800
      VeLINR_b_CompFaultStat_800TO: nonqueued-sender-com-spec{data-element=VeLINR_b_CompFaultStat_800TO, init-value=VeLINR_b_CompFaultStat_800TOValue:0}, provided-interface=VeLINR_b_CompFaultStat_800TO
      VeLINR_e_CompStat_800: nonqueued-sender-com-spec{data-element=VeLINR_e_CompStat_800, init-value=VeLINR_e_CompStat_800Value:0}, provided-interface=VeLINR_e_CompStat_800
      VeLINR_b_CompStat_800TO: nonqueued-sender-com-spec{data-element=VeLINR_b_CompStat_800TO, init-value=VeLINR_b_CompStat_800TOValue:0}, provided-interface=VeLINR_b_CompStat_800TO
      VeLINR_n_CompressorSpd_800: nonqueued-sender-com-spec{data-element=VeLINR_n_CompressorSpd_800, init-value=VeLINR_n_CompressorSpd_800Value:0}, provided-interface=VeLINR_n_CompressorSpd_800
      VeLINR_b_CompressorSpd_800TO: nonqueued-sender-com-spec{data-element=VeLINR_b_CompressorSpd_800TO, init-value=VeLINR_b_CompressorSpd_800TOValue:0}, provided-interface=VeLINR_b_CompressorSpd_800TO
      VeLINR_b_CompSpdIncrReq_800: nonqueued-sender-com-spec{data-element=VeLINR_b_CompSpdIncrReq_800, init-value=VeLINR_b_CompSpdIncrReq_800Value:0}, provided-interface=VeLINR_b_CompSpdIncrReq_800
      VeLINR_b_CompSpdIncrReq_800TO: nonqueued-sender-com-spec{data-element=VeLINR_b_CompSpdIncrReq_800TO, init-value=VeLINR_b_CompSpdIncrReq_800TOValue:0}, provided-interface=VeLINR_b_CompSpdIncrReq_800TO
      VeLINR_b_RsErr_EAC2_800: nonqueued-sender-com-spec{data-element=VeLINR_b_RsErr_EAC2_800, init-value=VeLINR_b_RsErr_EAC2_800Value:0}, provided-interface=VeLINR_b_RsErr_EAC2_800
      VeLINR_b_RsErr_EAC2_800TO: nonqueued-sender-com-spec{data-element=VeLINR_b_RsErr_EAC2_800TO, init-value=VeLINR_b_RsErr_EAC2_800TOValue:0}, provided-interface=VeLINR_b_RsErr_EAC2_800TO
      VeLINR_P_CompElecPwr_800: nonqueued-sender-com-spec{data-element=VeLINR_P_CompElecPwr_800, init-value=VeLINR_P_CompElecPwr_800Value:0}, provided-interface=VeLINR_P_CompElecPwr_800
      VeLINR_b_CompElecPwr_800TO: nonqueued-sender-com-spec{data-element=VeLINR_b_CompElecPwr_800TO, init-value=VeLINR_b_CompElecPwr_800TOValue:0}, provided-interface=VeLINR_b_CompElecPwr_800TO
      VeLINR_T_CompBoardTemp_800: nonqueued-sender-com-spec{data-element=VeLINR_T_CompBoardTemp_800, init-value=VeLINR_T_CompBoardTemp_800Value:-40}, provided-interface=VeLINR_T_CompBoardTemp_800
      VeLINR_b_CompBoardTemp_800TO: nonqueued-sender-com-spec{data-element=VeLINR_b_CompBoardTemp_800TO, init-value=VeLINR_b_CompBoardTemp_800TOValue:0}, provided-interface=VeLINR_b_CompBoardTemp_800TO
      VeLINR_T_CompIGBTTemp_800: nonqueued-sender-com-spec{data-element=VeLINR_T_CompIGBTTemp_800, init-value=VeLINR_T_CompIGBTTemp_800Value:-40}, provided-interface=VeLINR_T_CompIGBTTemp_800
      VeLINR_b_CompIGBTTemp_800TO: nonqueued-sender-com-spec{data-element=VeLINR_b_CompIGBTTemp_800TO, init-value=VeLINR_b_CompIGBTTemp_800TOValue:0}, provided-interface=VeLINR_b_CompIGBTTemp_800TO
      VeLINR_I_CompElecCurr_800: nonqueued-sender-com-spec{data-element=VeLINR_I_CompElecCurr_800, init-value=VeLINR_I_CompElecCurr_800Value:0}, provided-interface=VeLINR_I_CompElecCurr_800
      VeLINR_b_CompElecCurr_800TO: nonqueued-sender-com-spec{data-element=VeLINR_b_CompElecCurr_800TO, init-value=VeLINR_b_CompElecCurr_800TOValue:0}, provided-interface=VeLINR_b_CompElecCurr_800TO
      VeLINR_U_CompHVInput_800: nonqueued-sender-com-spec{data-element=VeLINR_U_CompHVInput_800, init-value=VeLINR_U_CompHVInput_800Value:0}, provided-interface=VeLINR_U_CompHVInput_800
      VeLINR_b_CompHVInput_800TO: nonqueued-sender-com-spec{data-element=VeLINR_b_CompHVInput_800TO, init-value=VeLINR_b_CompHVInput_800TOValue:0}, provided-interface=VeLINR_b_CompHVInput_800TO
    9 x require port:
      SendLINR_PwrPanel_LED_C_Command: nonqueued-receiver-com-spec{data-element=SendLINR_PwrPanel_LED_C_Command, init-value=SendLINR_PwrPanel_LED_C_CommandValue:0}, required-interface=SendLINR_PwrPanel_LED_C_Command
      SendLINR_PwrPanel_LED_C_CommandVld: nonqueued-receiver-com-spec{data-element=SendLINR_PwrPanel_LED_C_CommandVld, init-value=SendLINR_PwrPanel_LED_C_CommandVldValue:1}, required-interface=SendLINR_PwrPanel_LED_C_CommandVld
      SendLINR_PwrPanel_LEDA_ColorCmd: nonqueued-receiver-com-spec{data-element=SendLINR_PwrPanel_LEDA_ColorCmd, init-value=SendLINR_PwrPanel_LEDA_ColorCmdValue:0}, required-interface=SendLINR_PwrPanel_LEDA_ColorCmd
      SendLINR_PwrPanel_LEDA_ColorCmdVld: nonqueued-receiver-com-spec{data-element=SendLINR_PwrPanel_LEDA_ColorCmdVld, init-value=SendLINR_PwrPanel_LEDA_ColorCmdVldValue:1}, required-interface=SendLINR_PwrPanel_LEDA_ColorCmdVld
      SendLINR_PwrPanel_LEDB_ColorCmd: nonqueued-receiver-com-spec{data-element=SendLINR_PwrPanel_LEDB_ColorCmd, init-value=SendLINR_PwrPanel_LEDB_ColorCmdValue:0}, required-interface=SendLINR_PwrPanel_LEDB_ColorCmd
      SendLINR_PwrPanel_LEDB_ColorCmdVld: nonqueued-receiver-com-spec{data-element=SendLINR_PwrPanel_LEDB_ColorCmdVld, init-value=SendLINR_PwrPanel_LEDB_ColorCmdVldValue:1}, required-interface=SendLINR_PwrPanel_LEDB_ColorCmdVld
      SendLINR_PwrPanel_LEDC_ColorCmd: nonqueued-receiver-com-spec{data-element=SendLINR_PwrPanel_LEDC_ColorCmd, init-value=SendLINR_PwrPanel_LEDC_ColorCmdValue:0}, required-interface=SendLINR_PwrPanel_LEDC_ColorCmd
      SendLINR_PwrPanel_LEDC_ColorCmdVld: nonqueued-receiver-com-spec{data-element=SendLINR_PwrPanel_LEDC_ColorCmdVld, init-value=SendLINR_PwrPanel_LEDC_ColorCmdVldValue:1}, required-interface=SendLINR_PwrPanel_LEDC_ColorCmdVld
      SignalLINR_CACV_RdyForSleep: nonqueued-receiver-com-spec{data-element=SignalLINR_CACV_RdyForSleep, init-value=SignalLINR_CACV_RdyForSleepValue:0}, required-interface=SignalLINR_CACV_RdyForSleep
    36 x provide port:
      VeLINR_e_PwrPanel_LEDA_Feedback: nonqueued-sender-com-spec{data-element=VeLINR_e_PwrPanel_LEDA_Feedback, init-value=VeLINR_e_PwrPanel_LEDA_FeedbackValue:0}, provided-interface=VeLINR_e_PwrPanel_LEDA_Feedback
      VeLINR_b_PwrPanel_LEDA_FeedbackTO: nonqueued-sender-com-spec{data-element=VeLINR_b_PwrPanel_LEDA_FeedbackTO, init-value=VeLINR_b_PwrPanel_LEDA_FeedbackTOValue:0}, provided-interface=VeLINR_b_PwrPanel_LEDA_FeedbackTO
      VeLINR_e_PwrPanel_LEDB_Feedback: nonqueued-sender-com-spec{data-element=VeLINR_e_PwrPanel_LEDB_Feedback, init-value=VeLINR_e_PwrPanel_LEDB_FeedbackValue:0}, provided-interface=VeLINR_e_PwrPanel_LEDB_Feedback
      VeLINR_b_PwrPanel_LEDB_FeedbackTO: nonqueued-sender-com-spec{data-element=VeLINR_b_PwrPanel_LEDB_FeedbackTO, init-value=VeLINR_b_PwrPanel_LEDB_FeedbackTOValue:0}, provided-interface=VeLINR_b_PwrPanel_LEDB_FeedbackTO
      VeLINR_e_PwrPanel_LEDC_Feedback: nonqueued-sender-com-spec{data-element=VeLINR_e_PwrPanel_LEDC_Feedback, init-value=VeLINR_e_PwrPanel_LEDC_FeedbackValue:0}, provided-interface=VeLINR_e_PwrPanel_LEDC_Feedback
      VeLINR_b_PwrPanel_LEDC_FeedbackTO: nonqueued-sender-com-spec{data-element=VeLINR_b_PwrPanel_LEDC_FeedbackTO, init-value=VeLINR_b_PwrPanel_LEDC_FeedbackTOValue:0}, provided-interface=VeLINR_b_PwrPanel_LEDC_FeedbackTO
      VeLINR_e_PwrPanel_LEDA_FailSts: nonqueued-sender-com-spec{data-element=VeLINR_e_PwrPanel_LEDA_FailSts, init-value=VeLINR_e_PwrPanel_LEDA_FailStsValue:0}, provided-interface=VeLINR_e_PwrPanel_LEDA_FailSts
      VeLINR_b_PwrPanel_LEDA_FailStsTO: nonqueued-sender-com-spec{data-element=VeLINR_b_PwrPanel_LEDA_FailStsTO, init-value=VeLINR_b_PwrPanel_LEDA_FailStsTOValue:0}, provided-interface=VeLINR_b_PwrPanel_LEDA_FailStsTO
      VeLINR_e_PwrPanel_LEDB_FailSts: nonqueued-sender-com-spec{data-element=VeLINR_e_PwrPanel_LEDB_FailSts, init-value=VeLINR_e_PwrPanel_LEDB_FailStsValue:0}, provided-interface=VeLINR_e_PwrPanel_LEDB_FailSts
      VeLINR_b_PwrPanel_LEDB_FailStsTO: nonqueued-sender-com-spec{data-element=VeLINR_b_PwrPanel_LEDB_FailStsTO, init-value=VeLINR_b_PwrPanel_LEDB_FailStsTOValue:0}, provided-interface=VeLINR_b_PwrPanel_LEDB_FailStsTO
      VeLINR_e_PwrPanel_LEDC_FailSts: nonqueued-sender-com-spec{data-element=VeLINR_e_PwrPanel_LEDC_FailSts, init-value=VeLINR_e_PwrPanel_LEDC_FailStsValue:0}, provided-interface=VeLINR_e_PwrPanel_LEDC_FailSts
      VeLINR_b_PwrPanel_LEDC_FailStsTO: nonqueued-sender-com-spec{data-element=VeLINR_b_PwrPanel_LEDC_FailStsTO, init-value=VeLINR_b_PwrPanel_LEDC_FailStsTOValue:0}, provided-interface=VeLINR_b_PwrPanel_LEDC_FailStsTO
      VeLINR_e_PwrPanelLEDAColorFdbck: nonqueued-sender-com-spec{data-element=VeLINR_e_PwrPanelLEDAColorFdbck, init-value=VeLINR_e_PwrPanelLEDAColorFdbckValue:0}, provided-interface=VeLINR_e_PwrPanelLEDAColorFdbck
      VeLINR_b_PwrPanelLEDAColorFdbckTO: nonqueued-sender-com-spec{data-element=VeLINR_b_PwrPanelLEDAColorFdbckTO, init-value=VeLINR_b_PwrPanelLEDAColorFdbckTOValue:0}, provided-interface=VeLINR_b_PwrPanelLEDAColorFdbckTO
      VeLINR_e_PwrPanelLEDBColorFdbck: nonqueued-sender-com-spec{data-element=VeLINR_e_PwrPanelLEDBColorFdbck, init-value=VeLINR_e_PwrPanelLEDBColorFdbckValue:0}, provided-interface=VeLINR_e_PwrPanelLEDBColorFdbck
      VeLINR_b_PwrPanelLEDBColorFdbckTO: nonqueued-sender-com-spec{data-element=VeLINR_b_PwrPanelLEDBColorFdbckTO, init-value=VeLINR_b_PwrPanelLEDBColorFdbckTOValue:0}, provided-interface=VeLINR_b_PwrPanelLEDBColorFdbckTO
      VeLINR_e_PwrPanelLEDCColorFdbck: nonqueued-sender-com-spec{data-element=VeLINR_e_PwrPanelLEDCColorFdbck, init-value=VeLINR_e_PwrPanelLEDCColorFdbckValue:0}, provided-interface=VeLINR_e_PwrPanelLEDCColorFdbck
      VeLINR_b_PwrPanelLEDCColorFdbckTO: nonqueued-sender-com-spec{data-element=VeLINR_b_PwrPanelLEDCColorFdbckTO, init-value=VeLINR_b_PwrPanelLEDCColorFdbckTOValue:0}, provided-interface=VeLINR_b_PwrPanelLEDCColorFdbckTO
      VeLINR_b_PwrPanel_LIN_ChksumErr: nonqueued-sender-com-spec{data-element=VeLINR_b_PwrPanel_LIN_ChksumErr, init-value=VeLINR_b_PwrPanel_LIN_ChksumErrValue:0}, provided-interface=VeLINR_b_PwrPanel_LIN_ChksumErr
      VeLINR_b_PwrPanel_LIN_ChksumErrTO: nonqueued-sender-com-spec{data-element=VeLINR_b_PwrPanel_LIN_ChksumErrTO, init-value=VeLINR_b_PwrPanel_LIN_ChksumErrTOValue:0}, provided-interface=VeLINR_b_PwrPanel_LIN_ChksumErrTO
      VeLINR_b_PwrPanel_LIN_DataError: nonqueued-sender-com-spec{data-element=VeLINR_b_PwrPanel_LIN_DataError, init-value=VeLINR_b_PwrPanel_LIN_DataErrorValue:0}, provided-interface=VeLINR_b_PwrPanel_LIN_DataError
      VeLINR_b_PwrPanel_LIN_DataErrorTO: nonqueued-sender-com-spec{data-element=VeLINR_b_PwrPanel_LIN_DataErrorTO, init-value=VeLINR_b_PwrPanel_LIN_DataErrorTOValue:0}, provided-interface=VeLINR_b_PwrPanel_LIN_DataErrorTO
      VeLINR_b_PwrPanel_LIN_ParityErr: nonqueued-sender-com-spec{data-element=VeLINR_b_PwrPanel_LIN_ParityErr, init-value=VeLINR_b_PwrPanel_LIN_ParityErrValue:0}, provided-interface=VeLINR_b_PwrPanel_LIN_ParityErr
      VeLINR_b_PwrPanel_LIN_ParityErrTO: nonqueued-sender-com-spec{data-element=VeLINR_b_PwrPanel_LIN_ParityErrTO, init-value=VeLINR_b_PwrPanel_LIN_ParityErrTOValue:0}, provided-interface=VeLINR_b_PwrPanel_LIN_ParityErrTO
      VeLINR_b_PwrPanelGndFltDetected: nonqueued-sender-com-spec{data-element=VeLINR_b_PwrPanelGndFltDetected, init-value=VeLINR_b_PwrPanelGndFltDetectedValue:0}, provided-interface=VeLINR_b_PwrPanelGndFltDetected
      VeLINR_b_PwrPanelGndFltDetectedTO: nonqueued-sender-com-spec{data-element=VeLINR_b_PwrPanelGndFltDetectedTO, init-value=VeLINR_b_PwrPanelGndFltDetectedTOValue:0}, provided-interface=VeLINR_b_PwrPanelGndFltDetectedTO
      VeLINR_b_RsErr_EAC2: nonqueued-sender-com-spec{data-element=VeLINR_b_RsErr_EAC2, init-value=VeLINR_b_RsErr_EAC2Value:0}, provided-interface=VeLINR_b_RsErr_EAC2
      VeLINR_b_RsErr_EAC2TO: nonqueued-sender-com-spec{data-element=VeLINR_b_RsErr_EAC2TO, init-value=VeLINR_b_RsErr_EAC2TOValue:0}, provided-interface=VeLINR_b_RsErr_EAC2TO
      VeLINR_e_PowerPanel_Fault: nonqueued-sender-com-spec{data-element=VeLINR_e_PowerPanel_Fault, init-value=VeLINR_e_PowerPanel_FaultValue:0}, provided-interface=VeLINR_e_PowerPanel_Fault
      VeLINR_b_PowerPanel_FaultTO: nonqueued-sender-com-spec{data-element=VeLINR_b_PowerPanel_FaultTO, init-value=VeLINR_b_PowerPanel_FaultTOValue:0}, provided-interface=VeLINR_b_PowerPanel_FaultTO
      VeLINR_y_PowerPanel_RatedPower: nonqueued-sender-com-spec{data-element=VeLINR_y_PowerPanel_RatedPower, init-value=VeLINR_y_PowerPanel_RatedPowerValue:0}, provided-interface=VeLINR_y_PowerPanel_RatedPower
      VeLINR_b_PowerPanel_RatedPowerTO: nonqueued-sender-com-spec{data-element=VeLINR_b_PowerPanel_RatedPowerTO, init-value=VeLINR_b_PowerPanel_RatedPowerTOValue:0}, provided-interface=VeLINR_b_PowerPanel_RatedPowerTO
      VeLINR_d_PwrPanelCurrDrawSens1: nonqueued-sender-com-spec{data-element=VeLINR_d_PwrPanelCurrDrawSens1, init-value=VeLINR_d_PwrPanelCurrDrawSens1Value:0}, provided-interface=VeLINR_d_PwrPanelCurrDrawSens1
      VeLINR_b_PwrPanelCurrDrawSens1TO: nonqueued-sender-com-spec{data-element=VeLINR_b_PwrPanelCurrDrawSens1TO, init-value=VeLINR_b_PwrPanelCurrDrawSens1TOValue:0}, provided-interface=VeLINR_b_PwrPanelCurrDrawSens1TO
      VeLINR_d_PwrPanelCurrDrawSens2: nonqueued-sender-com-spec{data-element=VeLINR_d_PwrPanelCurrDrawSens2, init-value=VeLINR_d_PwrPanelCurrDrawSens2Value:0}, provided-interface=VeLINR_d_PwrPanelCurrDrawSens2
      VeLINR_b_PwrPanelCurrDrawSens2TO: nonqueued-sender-com-spec{data-element=VeLINR_b_PwrPanelCurrDrawSens2TO, init-value=VeLINR_b_PwrPanelCurrDrawSens2TOValue:0}, provided-interface=VeLINR_b_PwrPanelCurrDrawSens2TO
    behavior IBApplLinComAb_LIN2: data-type-mapping=[MG_LinEquid_Mapping, ADTtoIDTMapping, BswMMappingSet], handle-termination-and-restart=NO-SUPPORT
      init event IninEve: start-on-event=ApplLinComAb_LIN2Inin
      swc mode switch event MSELinsmComMod: disabled-mode=[MdulPwrMod.AppMode_MDGP_ESH_Mode.POSTRUN, MdulPwrMod.AppMode_MDGP_ESH_Mode.SHUTDOWN], start-on-event=LinsmComModSetScheduleTbl, activation=ON-ENTRY, mode=PP_MS_LinSMComMod.MDGP_MSI_LinSMComMod.LinSMComMod_FULL_COMM  # Triggered when Linsm goes to FULL COMM mode. Used to set the schedule table based on the equipped/learned state of the slaves.
      swc mode switch event MSELinsmInNoComMod: start-on-event=LinsmComModNotifyRdyToPwrDwn, activation=ON-ENTRY, mode=PP_MS_LinSMComMod.MDGP_MSI_LinSMComMod.LinSMComMod_NO_COMM  # When LinSM goes to NO COMM mode
        disabled-mode:
          MdulPwrMod.AppMode_MDGP_ESH_Mode.RUN
          MdulPwrMod.AppMode_MDGP_ESH_Mode.STARTUP
          MdulPwrMod.AppMode_MDGP_ESH_Mode.WAKEUP
      swc mode switch event MSEMdulInPostrun: start-on-event=LinsmComModPostrun, activation=ON-ENTRY, mode=MdulPwrMod.AppMode_MDGP_ESH_Mode.POSTRUN
      data received event DRECOMRXL_AGS2_CurrPos_AGS2_ECM_STATUS_Lin2: start-on-event=COMRXL_AGS2_CurrPos_AGS2_ECM_STATUS_Lin2_Received, data=Lin2ComRxSignalsSR.COMRXL_AGS2_CurrPos_AGS2_ECM_STATUS_Lin2
      data receive error event DEECOMRXL_AGS2_CurrPos_AGS2_ECM_STATUS_Lin2: start-on-event=COMRXL_AGS2_CurrPos_AGS2_ECM_STATUS_Lin2_Error, data=Lin2ComRxSignalsSR.COMRXL_AGS2_CurrPos_AGS2_ECM_STATUS_Lin2
      data received event DRECOMRXL_AGS2_CalStat_AGS2_ECM_STATUS_Lin2: start-on-event=COMRXL_AGS2_CalStat_AGS2_ECM_STATUS_Lin2_Received, data=Lin2ComRxSignalsSR.COMRXL_AGS2_CalStat_AGS2_ECM_STATUS_Lin2
      data receive error event DEECOMRXL_AGS2_CalStat_AGS2_ECM_STATUS_Lin2: start-on-event=COMRXL_AGS2_CalStat_AGS2_ECM_STATUS_Lin2_Error, data=Lin2ComRxSignalsSR.COMRXL_AGS2_CalStat_AGS2_ECM_STATUS_Lin2
      data received event DRECOMRXL_AGS2_CalActv_AGS2_ECM_STATUS_Lin2: start-on-event=COMRXL_AGS2_CalActv_AGS2_ECM_STATUS_Lin2_Received, data=Lin2ComRxSignalsSR.COMRXL_AGS2_CalActv_AGS2_ECM_STATUS_Lin2
      data receive error event DEECOMRXL_AGS2_CalActv_AGS2_ECM_STATUS_Lin2: start-on-event=COMRXL_AGS2_CalActv_AGS2_ECM_STATUS_Lin2_Error, data=Lin2ComRxSignalsSR.COMRXL_AGS2_CalActv_AGS2_ECM_STATUS_Lin2
      data received event DRECOMRXL_AGS2_ErrUnVolt_AGS2_ECM_STATUS_Lin2: start-on-event=COMRXL_AGS2_ErrUnVolt_AGS2_ECM_STATUS_Lin2_Received, data=Lin2ComRxSignalsSR.COMRXL_AGS2_ErrUnVolt_AGS2_ECM_STATUS_Lin2
      data receive error event DEECOMRXL_AGS2_ErrUnVolt_AGS2_ECM_STATUS_Lin2: start-on-event=COMRXL_AGS2_ErrUnVolt_AGS2_ECM_STATUS_Lin2_Error, data=Lin2ComRxSignalsSR.COMRXL_AGS2_ErrUnVolt_AGS2_ECM_STATUS_Lin2
      data received event DRECOMRXL_AGS2_ErrOvrVolt_AGS2_ECM_STATUS_Lin2: start-on-event=COMRXL_AGS2_ErrOvrVolt_AGS2_ECM_STATUS_Lin2_Received, data=Lin2ComRxSignalsSR.COMRXL_AGS2_ErrOvrVolt_AGS2_ECM_STATUS_Lin2
      data receive error event DEECOMRXL_AGS2_ErrOvrVolt_AGS2_ECM_STATUS_Lin2: start-on-event=COMRXL_AGS2_ErrOvrVolt_AGS2_ECM_STATUS_Lin2_Error, data=Lin2ComRxSignalsSR.COMRXL_AGS2_ErrOvrVolt_AGS2_ECM_STATUS_Lin2
      data received event DRECOMRXL_AGS2_ErrOvrTemp_AGS2_ECM_STATUS_Lin2: start-on-event=COMRXL_AGS2_ErrOvrTemp_AGS2_ECM_STATUS_Lin2_Received, data=Lin2ComRxSignalsSR.COMRXL_AGS2_ErrOvrTemp_AGS2_ECM_STATUS_Lin2
      data receive error event DEECOMRXL_AGS2_ErrOvrTemp_AGS2_ECM_STATUS_Lin2: start-on-event=COMRXL_AGS2_ErrOvrTemp_AGS2_ECM_STATUS_Lin2_Error, data=Lin2ComRxSignalsSR.COMRXL_AGS2_ErrOvrTemp_AGS2_ECM_STATUS_Lin2
      data received event DRECOMRXL_AGS2_ErrMechStuck_AGS2_ECM_STATUS_Lin2: start-on-event=COMRXL_AGS2_ErrMechStuck_AGS2_ECM_STATUS_Lin2_Received, data=Lin2ComRxSignalsSR.COMRXL_AGS2_ErrMechStuck_AGS2_ECM_STATUS_Lin2
      data receive error event DEECOMRXL_AGS2_ErrMechStuck_AGS2_ECM_STATUS_Lin2: start-on-event=COMRXL_AGS2_ErrMechStuck_AGS2_ECM_STATUS_Lin2_Error, data=Lin2ComRxSignalsSR.COMRXL_AGS2_ErrMechStuck_AGS2_ECM_STATUS_Lin2
      data received event DRECOMRXL_AGS2_ErrMechBreak_AGS2_ECM_STATUS_Lin2: start-on-event=COMRXL_AGS2_ErrMechBreak_AGS2_ECM_STATUS_Lin2_Received, data=Lin2ComRxSignalsSR.COMRXL_AGS2_ErrMechBreak_AGS2_ECM_STATUS_Lin2
      data receive error event DEECOMRXL_AGS2_ErrMechBreak_AGS2_ECM_STATUS_Lin2: start-on-event=COMRXL_AGS2_ErrMechBreak_AGS2_ECM_STATUS_Lin2_Error, data=Lin2ComRxSignalsSR.COMRXL_AGS2_ErrMechBreak_AGS2_ECM_STATUS_Lin2
      data received event DRECOMRXL_AGS2_ErrLIN_AGS2_ECM_STATUS_Lin2: start-on-event=COMRXL_AGS2_ErrLIN_AGS2_ECM_STATUS_Lin2_Received, data=Lin2ComRxSignalsSR.COMRXL_AGS2_ErrLIN_AGS2_ECM_STATUS_Lin2
      data receive error event DEECOMRXL_AGS2_ErrLIN_AGS2_ECM_STATUS_Lin2: start-on-event=COMRXL_AGS2_ErrLIN_AGS2_ECM_STATUS_Lin2_Error, data=Lin2ComRxSignalsSR.COMRXL_AGS2_ErrLIN_AGS2_ECM_STATUS_Lin2
      data received event DRECOMRXL_RsErr_AGS2_AGS2_ECM_STATUS_Lin2: start-on-event=COMRXL_RsErr_AGS2_AGS2_ECM_STATUS_Lin2_Received, data=Lin2ComRxSignalsSR.COMRXL_RsErr_AGS2_AGS2_ECM_STATUS_Lin2
      data receive error event DEECOMRXL_RsErr_AGS2_AGS2_ECM_STATUS_Lin2: start-on-event=COMRXL_RsErr_AGS2_AGS2_ECM_STATUS_Lin2_Error, data=Lin2ComRxSignalsSR.COMRXL_RsErr_AGS2_AGS2_ECM_STATUS_Lin2
      data received event DRECOMRXL_AGS2_BoostStat_AGS2_ECM_STATUS_Lin2: start-on-event=COMRXL_AGS2_BoostStat_AGS2_ECM_STATUS_Lin2_Received, data=Lin2ComRxSignalsSR.COMRXL_AGS2_BoostStat_AGS2_ECM_STATUS_Lin2
      data receive error event DEECOMRXL_AGS2_BoostStat_AGS2_ECM_STATUS_Lin2: start-on-event=COMRXL_AGS2_BoostStat_AGS2_ECM_STATUS_Lin2_Error, data=Lin2ComRxSignalsSR.COMRXL_AGS2_BoostStat_AGS2_ECM_STATUS_Lin2
      data received event DRECOMRXL_S2MResBit1_AGS2_AGS2_ECM_STATUS_Lin2: start-on-event=COMRXL_S2MResBit1_AGS2_AGS2_ECM_STATUS_Lin2_Received, data=Lin2ComRxSignalsSR.COMRXL_S2MResBit1_AGS2_AGS2_ECM_STATUS_Lin2
      data receive error event DEECOMRXL_S2MResBit1_AGS2_AGS2_ECM_STATUS_Lin2: start-on-event=COMRXL_S2MResBit1_AGS2_AGS2_ECM_STATUS_Lin2_Error, data=Lin2ComRxSignalsSR.COMRXL_S2MResBit1_AGS2_AGS2_ECM_STATUS_Lin2
      data received event DRECOMRXL_AHP_RPM_TGT_PERCT_AHP_STAT_GLOBAL_Lin2: start-on-event=COMRXL_AHP_RPM_TGT_PERCT_AHP_STAT_GLOBAL_Lin2_Received, data=Lin2ComRxSignalsSR.COMRXL_AHP_RPM_TGT_PERCT_AHP_STAT_GLOBAL_Lin2
      data receive error event DEECOMRXL_AHP_RPM_TGT_PERCT_AHP_STAT_GLOBAL_Lin2: start-on-event=COMRXL_AHP_RPM_TGT_PERCT_AHP_STAT_GLOBAL_Lin2_Error, data=Lin2ComRxSignalsSR.COMRXL_AHP_RPM_TGT_PERCT_AHP_STAT_GLOBAL_Lin2
      data received event DRECOMRXL_AHP_RPM_ACTL_PERCT_AHP_STAT_GLOBAL_Lin2: start-on-event=COMRXL_AHP_RPM_ACTL_PERCT_AHP_STAT_GLOBAL_Lin2_Received, data=Lin2ComRxSignalsSR.COMRXL_AHP_RPM_ACTL_PERCT_AHP_STAT_GLOBAL_Lin2
      data receive error event DEECOMRXL_AHP_RPM_ACTL_PERCT_AHP_STAT_GLOBAL_Lin2: start-on-event=COMRXL_AHP_RPM_ACTL_PERCT_AHP_STAT_GLOBAL_Lin2_Error, data=Lin2ComRxSignalsSR.COMRXL_AHP_RPM_ACTL_PERCT_AHP_STAT_GLOBAL_Lin2
      data received event DRECOMRXL_AHP_VLTG_AHP_STAT_GLOBAL_Lin2: start-on-event=COMRXL_AHP_VLTG_AHP_STAT_GLOBAL_Lin2_Received, data=Lin2ComRxSignalsSR.COMRXL_AHP_VLTG_AHP_STAT_GLOBAL_Lin2
      data receive error event DEECOMRXL_AHP_VLTG_AHP_STAT_GLOBAL_Lin2: start-on-event=COMRXL_AHP_VLTG_AHP_STAT_GLOBAL_Lin2_Error, data=Lin2ComRxSignalsSR.COMRXL_AHP_VLTG_AHP_STAT_GLOBAL_Lin2
      data received event DRECOMRXL_AHP_TEMP_AHP_STAT_GLOBAL_Lin2: start-on-event=COMRXL_AHP_TEMP_AHP_STAT_GLOBAL_Lin2_Received, data=Lin2ComRxSignalsSR.COMRXL_AHP_TEMP_AHP_STAT_GLOBAL_Lin2
      data receive error event DEECOMRXL_AHP_TEMP_AHP_STAT_GLOBAL_Lin2: start-on-event=COMRXL_AHP_TEMP_AHP_STAT_GLOBAL_Lin2_Error, data=Lin2ComRxSignalsSR.COMRXL_AHP_TEMP_AHP_STAT_GLOBAL_Lin2
      data received event DRECOMRXL_AHP_CURR_AHP_STAT_GLOBAL_Lin2: start-on-event=COMRXL_AHP_CURR_AHP_STAT_GLOBAL_Lin2_Received, data=Lin2ComRxSignalsSR.COMRXL_AHP_CURR_AHP_STAT_GLOBAL_Lin2
      data receive error event DEECOMRXL_AHP_CURR_AHP_STAT_GLOBAL_Lin2: start-on-event=COMRXL_AHP_CURR_AHP_STAT_GLOBAL_Lin2_Error, data=Lin2ComRxSignalsSR.COMRXL_AHP_CURR_AHP_STAT_GLOBAL_Lin2
      data received event DRECOMRXL_AHP_FL_SAFE_ACTVTD_AHP_STAT_GLOBAL_Lin2: start-on-event=COMRXL_AHP_FL_SAFE_ACTVTD_AHP_STAT_GLOBAL_Lin2_Received, data=Lin2ComRxSignalsSR.COMRXL_AHP_FL_SAFE_ACTVTD_AHP_STAT_GLOBAL_Lin2
      data receive error event DEECOMRXL_AHP_FL_SAFE_ACTVTD_AHP_STAT_GLOBAL_Lin2: start-on-event=COMRXL_AHP_FL_SAFE_ACTVTD_AHP_STAT_GLOBAL_Lin2_Error, data=Lin2ComRxSignalsSR.COMRXL_AHP_FL_SAFE_ACTVTD_AHP_STAT_GLOBAL_Lin2
      data received event DRECOMRXL_AHP_LMP_HM_AN_ON_AHP_STAT_GLOBAL_Lin2: start-on-event=COMRXL_AHP_LMP_HM_AN_ON_AHP_STAT_GLOBAL_Lin2_Received, data=Lin2ComRxSignalsSR.COMRXL_AHP_LMP_HM_AN_ON_AHP_STAT_GLOBAL_Lin2
      data receive error event DEECOMRXL_AHP_LMP_HM_AN_ON_AHP_STAT_GLOBAL_Lin2: start-on-event=COMRXL_AHP_LMP_HM_AN_ON_AHP_STAT_GLOBAL_Lin2_Error, data=Lin2ComRxSignalsSR.COMRXL_AHP_LMP_HM_AN_ON_AHP_STAT_GLOBAL_Lin2
      data received event DRECOMRXL_AHP_AIR_PRE_ERR_AHP_STAT_GLOBAL_Lin2: start-on-event=COMRXL_AHP_AIR_PRE_ERR_AHP_STAT_GLOBAL_Lin2_Received, data=Lin2ComRxSignalsSR.COMRXL_AHP_AIR_PRE_ERR_AHP_STAT_GLOBAL_Lin2
      data receive error event DEECOMRXL_AHP_AIR_PRE_ERR_AHP_STAT_GLOBAL_Lin2: start-on-event=COMRXL_AHP_AIR_PRE_ERR_AHP_STAT_GLOBAL_Lin2_Error, data=Lin2ComRxSignalsSR.COMRXL_AHP_AIR_PRE_ERR_AHP_STAT_GLOBAL_Lin2
      data received event DRECOMRXL_AHP_OVR_TMP_ERR_AHP_STAT_GLOBAL_Lin2: start-on-event=COMRXL_AHP_OVR_TMP_ERR_AHP_STAT_GLOBAL_Lin2_Received, data=Lin2ComRxSignalsSR.COMRXL_AHP_OVR_TMP_ERR_AHP_STAT_GLOBAL_Lin2
      data receive error event DEECOMRXL_AHP_OVR_TMP_ERR_AHP_STAT_GLOBAL_Lin2: start-on-event=COMRXL_AHP_OVR_TMP_ERR_AHP_STAT_GLOBAL_Lin2_Error, data=Lin2ComRxSignalsSR.COMRXL_AHP_OVR_TMP_ERR_AHP_STAT_GLOBAL_Lin2
      data received event DRECOMRXL_AHP_OVR_CUR_ERR_AHP_STAT_GLOBAL_Lin2: start-on-event=COMRXL_AHP_OVR_CUR_ERR_AHP_STAT_GLOBAL_Lin2_Received, data=Lin2ComRxSignalsSR.COMRXL_AHP_OVR_CUR_ERR_AHP_STAT_GLOBAL_Lin2
      data receive error event DEECOMRXL_AHP_OVR_CUR_ERR_AHP_STAT_GLOBAL_Lin2: start-on-event=COMRXL_AHP_OVR_CUR_ERR_AHP_STAT_GLOBAL_Lin2_Error, data=Lin2ComRxSignalsSR.COMRXL_AHP_OVR_CUR_ERR_AHP_STAT_GLOBAL_Lin2
      data received event DRECOMRXL_AHP_DR_RN_ERR_AHP_STAT_GLOBAL_Lin2: start-on-event=COMRXL_AHP_DR_RN_ERR_AHP_STAT_GLOBAL_Lin2_Received, data=Lin2ComRxSignalsSR.COMRXL_AHP_DR_RN_ERR_AHP_STAT_GLOBAL_Lin2
      data receive error event DEECOMRXL_AHP_DR_RN_ERR_AHP_STAT_GLOBAL_Lin2: start-on-event=COMRXL_AHP_DR_RN_ERR_AHP_STAT_GLOBAL_Lin2_Error, data=Lin2ComRxSignalsSR.COMRXL_AHP_DR_RN_ERR_AHP_STAT_GLOBAL_Lin2
      data received event DRECOMRXL_AHP_VLTG_ERR_AHP_STAT_GLOBAL_Lin2: start-on-event=COMRXL_AHP_VLTG_ERR_AHP_STAT_GLOBAL_Lin2_Received, data=Lin2ComRxSignalsSR.COMRXL_AHP_VLTG_ERR_AHP_STAT_GLOBAL_Lin2
      data receive error event DEECOMRXL_AHP_VLTG_ERR_AHP_STAT_GLOBAL_Lin2: start-on-event=COMRXL_AHP_VLTG_ERR_AHP_STAT_GLOBAL_Lin2_Error, data=Lin2ComRxSignalsSR.COMRXL_AHP_VLTG_ERR_AHP_STAT_GLOBAL_Lin2
      data received event DRECOMRXL_AHP_DBLK_ACTV_AHP_STAT_GLOBAL_Lin2: start-on-event=COMRXL_AHP_DBLK_ACTV_AHP_STAT_GLOBAL_Lin2_Received, data=Lin2ComRxSignalsSR.COMRXL_AHP_DBLK_ACTV_AHP_STAT_GLOBAL_Lin2
      data receive error event DEECOMRXL_AHP_DBLK_ACTV_AHP_STAT_GLOBAL_Lin2: start-on-event=COMRXL_AHP_DBLK_ACTV_AHP_STAT_GLOBAL_Lin2_Error, data=Lin2ComRxSignalsSR.COMRXL_AHP_DBLK_ACTV_AHP_STAT_GLOBAL_Lin2
      data received event DRECOMRXL_AHP_MONTRNG_RPM_AHP_STAT_GLOBAL_Lin2: start-on-event=COMRXL_AHP_MONTRNG_RPM_AHP_STAT_GLOBAL_Lin2_Received, data=Lin2ComRxSignalsSR.COMRXL_AHP_MONTRNG_RPM_AHP_STAT_GLOBAL_Lin2
      data receive error event DEECOMRXL_AHP_MONTRNG_RPM_AHP_STAT_GLOBAL_Lin2: start-on-event=COMRXL_AHP_MONTRNG_RPM_AHP_STAT_GLOBAL_Lin2_Error, data=Lin2ComRxSignalsSR.COMRXL_AHP_MONTRNG_RPM_AHP_STAT_GLOBAL_Lin2
      data received event DRECOMRXL_AHP_NODE_ERR_AHP_STAT_GLOBAL_Lin2: start-on-event=COMRXL_AHP_NODE_ERR_AHP_STAT_GLOBAL_Lin2_Received, data=Lin2ComRxSignalsSR.COMRXL_AHP_NODE_ERR_AHP_STAT_GLOBAL_Lin2
      data receive error event DEECOMRXL_AHP_NODE_ERR_AHP_STAT_GLOBAL_Lin2: start-on-event=COMRXL_AHP_NODE_ERR_AHP_STAT_GLOBAL_Lin2_Error, data=Lin2ComRxSignalsSR.COMRXL_AHP_NODE_ERR_AHP_STAT_GLOBAL_Lin2
      data received event DRECOMRXL_AHP_POST_RUN_STAT_AHP_STAT_GLOBAL_Lin2: start-on-event=COMRXL_AHP_POST_RUN_STAT_AHP_STAT_GLOBAL_Lin2_Received, data=Lin2ComRxSignalsSR.COMRXL_AHP_POST_RUN_STAT_AHP_STAT_GLOBAL_Lin2
      data receive error event DEECOMRXL_AHP_POST_RUN_STAT_AHP_STAT_GLOBAL_Lin2: start-on-event=COMRXL_AHP_POST_RUN_STAT_AHP_STAT_GLOBAL_Lin2_Error, data=Lin2ComRxSignalsSR.COMRXL_AHP_POST_RUN_STAT_AHP_STAT_GLOBAL_Lin2
      data received event DRECOMRXL_RsErr_AHP_PUMP_AHP_STAT_GLOBAL_Lin2: start-on-event=COMRXL_RsErr_AHP_PUMP_AHP_STAT_GLOBAL_Lin2_Received, data=Lin2ComRxSignalsSR.COMRXL_RsErr_AHP_PUMP_AHP_STAT_GLOBAL_Lin2
      data receive error event DEECOMRXL_RsErr_AHP_PUMP_AHP_STAT_GLOBAL_Lin2: start-on-event=COMRXL_RsErr_AHP_PUMP_AHP_STAT_GLOBAL_Lin2_Error, data=Lin2ComRxSignalsSR.COMRXL_RsErr_AHP_PUMP_AHP_STAT_GLOBAL_Lin2
      data received event DRECOMRXL_AHP_SUPPLIER_AHP_VER_Lin2: start-on-event=COMRXL_AHP_SUPPLIER_AHP_VER_Lin2_Received, data=Lin2ComRxSignalsSR.COMRXL_AHP_SUPPLIER_AHP_VER_Lin2
      data receive error event DEECOMRXL_AHP_SUPPLIER_AHP_VER_Lin2: start-on-event=COMRXL_AHP_SUPPLIER_AHP_VER_Lin2_Error, data=Lin2ComRxSignalsSR.COMRXL_AHP_SUPPLIER_AHP_VER_Lin2
      data received event DRECOMRXL_BHV_PosAct_BHV_STAT_V2_Lin2: start-on-event=COMRXL_BHV_PosAct_BHV_STAT_V2_Lin2_Received, data=Lin2ComRxSignalsSR.COMRXL_BHV_PosAct_BHV_STAT_V2_Lin2
      data receive error event DEECOMRXL_BHV_PosAct_BHV_STAT_V2_Lin2: start-on-event=COMRXL_BHV_PosAct_BHV_STAT_V2_Lin2_Error, data=Lin2ComRxSignalsSR.COMRXL_BHV_PosAct_BHV_STAT_V2_Lin2
      data received event DRECOMRXL_BHV_ERR_BHV_STAT_V2_Lin2: start-on-event=COMRXL_BHV_ERR_BHV_STAT_V2_Lin2_Received, data=Lin2ComRxSignalsSR.COMRXL_BHV_ERR_BHV_STAT_V2_Lin2
      data receive error event DEECOMRXL_BHV_ERR_BHV_STAT_V2_Lin2: start-on-event=COMRXL_BHV_ERR_BHV_STAT_V2_Lin2_Error, data=Lin2ComRxSignalsSR.COMRXL_BHV_ERR_BHV_STAT_V2_Lin2
      data received event DRECOMRXL_BHV_Sts_BHV_STAT_V2_Lin2: start-on-event=COMRXL_BHV_Sts_BHV_STAT_V2_Lin2_Received, data=Lin2ComRxSignalsSR.COMRXL_BHV_Sts_BHV_STAT_V2_Lin2
      data receive error event DEECOMRXL_BHV_Sts_BHV_STAT_V2_Lin2: start-on-event=COMRXL_BHV_Sts_BHV_STAT_V2_Lin2_Error, data=Lin2ComRxSignalsSR.COMRXL_BHV_Sts_BHV_STAT_V2_Lin2
      data received event DRECOMRXL_RsErr_BHV_BHV_STAT_V2_Lin2: start-on-event=COMRXL_RsErr_BHV_BHV_STAT_V2_Lin2_Received, data=Lin2ComRxSignalsSR.COMRXL_RsErr_BHV_BHV_STAT_V2_Lin2
      data receive error event DEECOMRXL_RsErr_BHV_BHV_STAT_V2_Lin2: start-on-event=COMRXL_RsErr_BHV_BHV_STAT_V2_Lin2_Error, data=Lin2ComRxSignalsSR.COMRXL_RsErr_BHV_BHV_STAT_V2_Lin2
      data received event DRECOMRXL_CompFaultStat_EAC_STAT_Lin2: start-on-event=COMRXL_CompFaultStat_EAC_STAT_Lin2_Received, data=Lin2ComRxSignalsSR.COMRXL_CompFaultStat_EAC_STAT_Lin2
      data receive error event DEECOMRXL_CompFaultStat_EAC_STAT_Lin2: start-on-event=COMRXL_CompFaultStat_EAC_STAT_Lin2_Error, data=Lin2ComRxSignalsSR.COMRXL_CompFaultStat_EAC_STAT_Lin2
      data received event DRECOMRXL_CompStat_EAC_STAT_Lin2: start-on-event=COMRXL_CompStat_EAC_STAT_Lin2_Received, data=Lin2ComRxSignalsSR.COMRXL_CompStat_EAC_STAT_Lin2
      data receive error event DEECOMRXL_CompStat_EAC_STAT_Lin2: start-on-event=COMRXL_CompStat_EAC_STAT_Lin2_Error, data=Lin2ComRxSignalsSR.COMRXL_CompStat_EAC_STAT_Lin2
      data received event DRECOMRXL_CompressorSpd_EAC_STAT_Lin2: start-on-event=COMRXL_CompressorSpd_EAC_STAT_Lin2_Received, data=Lin2ComRxSignalsSR.COMRXL_CompressorSpd_EAC_STAT_Lin2
      data receive error event DEECOMRXL_CompressorSpd_EAC_STAT_Lin2: start-on-event=COMRXL_CompressorSpd_EAC_STAT_Lin2_Error, data=Lin2ComRxSignalsSR.COMRXL_CompressorSpd_EAC_STAT_Lin2
      data received event DRECOMRXL_CompSpdIncrReq_EAC_STAT_Lin2: start-on-event=COMRXL_CompSpdIncrReq_EAC_STAT_Lin2_Received, data=Lin2ComRxSignalsSR.COMRXL_CompSpdIncrReq_EAC_STAT_Lin2
      data receive error event DEECOMRXL_CompSpdIncrReq_EAC_STAT_Lin2: start-on-event=COMRXL_CompSpdIncrReq_EAC_STAT_Lin2_Error, data=Lin2ComRxSignalsSR.COMRXL_CompSpdIncrReq_EAC_STAT_Lin2
      data received event DRECOMRXL_CompElecPwr_EAC_STAT_Lin2: start-on-event=COMRXL_CompElecPwr_EAC_STAT_Lin2_Received, data=Lin2ComRxSignalsSR.COMRXL_CompElecPwr_EAC_STAT_Lin2
      data receive error event DEECOMRXL_CompElecPwr_EAC_STAT_Lin2: start-on-event=COMRXL_CompElecPwr_EAC_STAT_Lin2_Error, data=Lin2ComRxSignalsSR.COMRXL_CompElecPwr_EAC_STAT_Lin2
      data received event DRECOMRXL_CompBoardTemp_EAC_STAT_Lin2: start-on-event=COMRXL_CompBoardTemp_EAC_STAT_Lin2_Received, data=Lin2ComRxSignalsSR.COMRXL_CompBoardTemp_EAC_STAT_Lin2
      data receive error event DEECOMRXL_CompBoardTemp_EAC_STAT_Lin2: start-on-event=COMRXL_CompBoardTemp_EAC_STAT_Lin2_Error, data=Lin2ComRxSignalsSR.COMRXL_CompBoardTemp_EAC_STAT_Lin2
      data received event DRECOMRXL_CompIGBTTemp_EAC_STAT_Lin2: start-on-event=COMRXL_CompIGBTTemp_EAC_STAT_Lin2_Received, data=Lin2ComRxSignalsSR.COMRXL_CompIGBTTemp_EAC_STAT_Lin2
      data receive error event DEECOMRXL_CompIGBTTemp_EAC_STAT_Lin2: start-on-event=COMRXL_CompIGBTTemp_EAC_STAT_Lin2_Error, data=Lin2ComRxSignalsSR.COMRXL_CompIGBTTemp_EAC_STAT_Lin2
      data received event DRECOMRXL_CompElecCurr_EAC_STAT_Lin2: start-on-event=COMRXL_CompElecCurr_EAC_STAT_Lin2_Received, data=Lin2ComRxSignalsSR.COMRXL_CompElecCurr_EAC_STAT_Lin2
      data receive error event DEECOMRXL_CompElecCurr_EAC_STAT_Lin2: start-on-event=COMRXL_CompElecCurr_EAC_STAT_Lin2_Error, data=Lin2ComRxSignalsSR.COMRXL_CompElecCurr_EAC_STAT_Lin2
      data received event DRECOMRXL_CompHVInput_EAC_STAT_Lin2: start-on-event=COMRXL_CompHVInput_EAC_STAT_Lin2_Received, data=Lin2ComRxSignalsSR.COMRXL_CompHVInput_EAC_STAT_Lin2
      data receive error event DEECOMRXL_CompHVInput_EAC_STAT_Lin2: start-on-event=COMRXL_CompHVInput_EAC_STAT_Lin2_Error, data=Lin2ComRxSignalsSR.COMRXL_CompHVInput_EAC_STAT_Lin2
      data received event DRECOMRXL_DriveMdReq_ESBM_1_Lin2: start-on-event=COMRXL_DriveMdReq_ESBM_1_Lin2_Received, data=Lin2ComRxSignalsSR.COMRXL_DriveMdReq_ESBM_1_Lin2
      data receive error event DEECOMRXL_DriveMdReq_ESBM_1_Lin2: start-on-event=COMRXL_DriveMdReq_ESBM_1_Lin2_Error, data=Lin2ComRxSignalsSR.COMRXL_DriveMdReq_ESBM_1_Lin2
      data received event DRECOMRXL_HybridModeRq_LIN_ESBM_1_Lin2: start-on-event=COMRXL_HybridModeRq_LIN_ESBM_1_Lin2_Received, data=Lin2ComRxSignalsSR.COMRXL_HybridModeRq_LIN_ESBM_1_Lin2
      data receive error event DEECOMRXL_HybridModeRq_LIN_ESBM_1_Lin2: start-on-event=COMRXL_HybridModeRq_LIN_ESBM_1_Lin2_Error, data=Lin2ComRxSignalsSR.COMRXL_HybridModeRq_LIN_ESBM_1_Lin2
      data received event DRECOMRXL_ESaveModeRq_LIN_ESBM_1_Lin2: start-on-event=COMRXL_ESaveModeRq_LIN_ESBM_1_Lin2_Received, data=Lin2ComRxSignalsSR.COMRXL_ESaveModeRq_LIN_ESBM_1_Lin2
      data receive error event DEECOMRXL_ESaveModeRq_LIN_ESBM_1_Lin2: start-on-event=COMRXL_ESaveModeRq_LIN_ESBM_1_Lin2_Error, data=Lin2ComRxSignalsSR.COMRXL_ESaveModeRq_LIN_ESBM_1_Lin2
      data received event DRECOMRXL_ElectricModeRq_LIN_ESBM_1_Lin2: start-on-event=COMRXL_ElectricModeRq_LIN_ESBM_1_Lin2_Received, data=Lin2ComRxSignalsSR.COMRXL_ElectricModeRq_LIN_ESBM_1_Lin2
      data receive error event DEECOMRXL_ElectricModeRq_LIN_ESBM_1_Lin2: start-on-event=COMRXL_ElectricModeRq_LIN_ESBM_1_Lin2_Error, data=Lin2ComRxSignalsSR.COMRXL_ElectricModeRq_LIN_ESBM_1_Lin2
      data received event DRECOMRXL_RsErr_ESBM_ESBM_1_Lin2: start-on-event=COMRXL_RsErr_ESBM_ESBM_1_Lin2_Received, data=Lin2ComRxSignalsSR.COMRXL_RsErr_ESBM_ESBM_1_Lin2
      data receive error event DEECOMRXL_RsErr_ESBM_ESBM_1_Lin2: start-on-event=COMRXL_RsErr_ESBM_ESBM_1_Lin2_Error, data=Lin2ComRxSignalsSR.COMRXL_RsErr_ESBM_ESBM_1_Lin2
      data received event DRECOMRXL_PECP_RPM_TGT_PERCT_PECP_STAT_GLOBAL_Lin2: start-on-event=COMRXL_PECP_RPM_TGT_PERCT_PECP_STAT_GLOBAL_Lin2_Received, data=Lin2ComRxSignalsSR.COMRXL_PECP_RPM_TGT_PERCT_PECP_STAT_GLOBAL_Lin2
      data receive error event DEECOMRXL_PECP_RPM_TGT_PERCT_PECP_STAT_GLOBAL_Lin2: start-on-event=COMRXL_PECP_RPM_TGT_PERCT_PECP_STAT_GLOBAL_Lin2_Error, data=Lin2ComRxSignalsSR.COMRXL_PECP_RPM_TGT_PERCT_PECP_STAT_GLOBAL_Lin2
      data received event DRECOMRXL_PECP_RPM_ACTL_PERCT_PECP_STAT_GLOBAL_Lin2: start-on-event=COMRXL_PECP_RPM_ACTL_PERCT_PECP_STAT_GLOBAL_Lin2_Received, data=Lin2ComRxSignalsSR.COMRXL_PECP_RPM_ACTL_PERCT_PECP_STAT_GLOBAL_Lin2
      data receive error event DEECOMRXL_PECP_RPM_ACTL_PERCT_PECP_STAT_GLOBAL_Lin2: start-on-event=COMRXL_PECP_RPM_ACTL_PERCT_PECP_STAT_GLOBAL_Lin2_Error, data=Lin2ComRxSignalsSR.COMRXL_PECP_RPM_ACTL_PERCT_PECP_STAT_GLOBAL_Lin2
      data received event DRECOMRXL_PECP_VLTG_PECP_STAT_GLOBAL_Lin2: start-on-event=COMRXL_PECP_VLTG_PECP_STAT_GLOBAL_Lin2_Received, data=Lin2ComRxSignalsSR.COMRXL_PECP_VLTG_PECP_STAT_GLOBAL_Lin2
      data receive error event DEECOMRXL_PECP_VLTG_PECP_STAT_GLOBAL_Lin2: start-on-event=COMRXL_PECP_VLTG_PECP_STAT_GLOBAL_Lin2_Error, data=Lin2ComRxSignalsSR.COMRXL_PECP_VLTG_PECP_STAT_GLOBAL_Lin2
      data received event DRECOMRXL_PECP_TEMP_PECP_STAT_GLOBAL_Lin2: start-on-event=COMRXL_PECP_TEMP_PECP_STAT_GLOBAL_Lin2_Received, data=Lin2ComRxSignalsSR.COMRXL_PECP_TEMP_PECP_STAT_GLOBAL_Lin2
      data receive error event DEECOMRXL_PECP_TEMP_PECP_STAT_GLOBAL_Lin2: start-on-event=COMRXL_PECP_TEMP_PECP_STAT_GLOBAL_Lin2_Error, data=Lin2ComRxSignalsSR.COMRXL_PECP_TEMP_PECP_STAT_GLOBAL_Lin2
      data received event DRECOMRXL_PECP_CURR_PECP_STAT_GLOBAL_Lin2: start-on-event=COMRXL_PECP_CURR_PECP_STAT_GLOBAL_Lin2_Received, data=Lin2ComRxSignalsSR.COMRXL_PECP_CURR_PECP_STAT_GLOBAL_Lin2
      data receive error event DEECOMRXL_PECP_CURR_PECP_STAT_GLOBAL_Lin2: start-on-event=COMRXL_PECP_CURR_PECP_STAT_GLOBAL_Lin2_Error, data=Lin2ComRxSignalsSR.COMRXL_PECP_CURR_PECP_STAT_GLOBAL_Lin2
      data received event DRECOMRXL_PECP_FL_SAFE_ACTVTD_PECP_STAT_GLOBAL_Lin2: start-on-event=COMRXL_PECP_FL_SAFE_ACTVTD_PECP_STAT_GLOBAL_Lin2_Received, data=Lin2ComRxSignalsSR.COMRXL_PECP_FL_SAFE_ACTVTD_PECP_STAT_GLOBAL_Lin2
      data receive error event DEECOMRXL_PECP_FL_SAFE_ACTVTD_PECP_STAT_GLOBAL_Lin2: start-on-event=COMRXL_PECP_FL_SAFE_ACTVTD_PECP_STAT_GLOBAL_Lin2_Error, data=Lin2ComRxSignalsSR.COMRXL_PECP_FL_SAFE_ACTVTD_PECP_STAT_GLOBAL_Lin2
      data received event DRECOMRXL_PECP_LMP_HM_AN_ON_PECP_STAT_GLOBAL_Lin2: start-on-event=COMRXL_PECP_LMP_HM_AN_ON_PECP_STAT_GLOBAL_Lin2_Received, data=Lin2ComRxSignalsSR.COMRXL_PECP_LMP_HM_AN_ON_PECP_STAT_GLOBAL_Lin2
      data receive error event DEECOMRXL_PECP_LMP_HM_AN_ON_PECP_STAT_GLOBAL_Lin2: start-on-event=COMRXL_PECP_LMP_HM_AN_ON_PECP_STAT_GLOBAL_Lin2_Error, data=Lin2ComRxSignalsSR.COMRXL_PECP_LMP_HM_AN_ON_PECP_STAT_GLOBAL_Lin2
      data received event DRECOMRXL_PECP_AIR_PRE_ERR_PECP_STAT_GLOBAL_Lin2: start-on-event=COMRXL_PECP_AIR_PRE_ERR_PECP_STAT_GLOBAL_Lin2_Received, data=Lin2ComRxSignalsSR.COMRXL_PECP_AIR_PRE_ERR_PECP_STAT_GLOBAL_Lin2
      data receive error event DEECOMRXL_PECP_AIR_PRE_ERR_PECP_STAT_GLOBAL_Lin2: start-on-event=COMRXL_PECP_AIR_PRE_ERR_PECP_STAT_GLOBAL_Lin2_Error, data=Lin2ComRxSignalsSR.COMRXL_PECP_AIR_PRE_ERR_PECP_STAT_GLOBAL_Lin2
      data received event DRECOMRXL_PECP_OVR_TMP_ERR_PECP_STAT_GLOBAL_Lin2: start-on-event=COMRXL_PECP_OVR_TMP_ERR_PECP_STAT_GLOBAL_Lin2_Received, data=Lin2ComRxSignalsSR.COMRXL_PECP_OVR_TMP_ERR_PECP_STAT_GLOBAL_Lin2
      data receive error event DEECOMRXL_PECP_OVR_TMP_ERR_PECP_STAT_GLOBAL_Lin2: start-on-event=COMRXL_PECP_OVR_TMP_ERR_PECP_STAT_GLOBAL_Lin2_Error, data=Lin2ComRxSignalsSR.COMRXL_PECP_OVR_TMP_ERR_PECP_STAT_GLOBAL_Lin2
      data received event DRECOMRXL_PECP_OVR_CUR_ERR_PECP_STAT_GLOBAL_Lin2: start-on-event=COMRXL_PECP_OVR_CUR_ERR_PECP_STAT_GLOBAL_Lin2_Received, data=Lin2ComRxSignalsSR.COMRXL_PECP_OVR_CUR_ERR_PECP_STAT_GLOBAL_Lin2
      data receive error event DEECOMRXL_PECP_OVR_CUR_ERR_PECP_STAT_GLOBAL_Lin2: start-on-event=COMRXL_PECP_OVR_CUR_ERR_PECP_STAT_GLOBAL_Lin2_Error, data=Lin2ComRxSignalsSR.COMRXL_PECP_OVR_CUR_ERR_PECP_STAT_GLOBAL_Lin2
      data received event DRECOMRXL_PECP_DR_RN_ERR_PECP_STAT_GLOBAL_Lin2: start-on-event=COMRXL_PECP_DR_RN_ERR_PECP_STAT_GLOBAL_Lin2_Received, data=Lin2ComRxSignalsSR.COMRXL_PECP_DR_RN_ERR_PECP_STAT_GLOBAL_Lin2
      data receive error event DEECOMRXL_PECP_DR_RN_ERR_PECP_STAT_GLOBAL_Lin2: start-on-event=COMRXL_PECP_DR_RN_ERR_PECP_STAT_GLOBAL_Lin2_Error, data=Lin2ComRxSignalsSR.COMRXL_PECP_DR_RN_ERR_PECP_STAT_GLOBAL_Lin2
      data received event DRECOMRXL_PECP_VLTG_ERR_PECP_STAT_GLOBAL_Lin2: start-on-event=COMRXL_PECP_VLTG_ERR_PECP_STAT_GLOBAL_Lin2_Received, data=Lin2ComRxSignalsSR.COMRXL_PECP_VLTG_ERR_PECP_STAT_GLOBAL_Lin2
      data receive error event DEECOMRXL_PECP_VLTG_ERR_PECP_STAT_GLOBAL_Lin2: start-on-event=COMRXL_PECP_VLTG_ERR_PECP_STAT_GLOBAL_Lin2_Error, data=Lin2ComRxSignalsSR.COMRXL_PECP_VLTG_ERR_PECP_STAT_GLOBAL_Lin2
      data received event DRECOMRXL_PECP_DBLK_ACTV_PECP_STAT_GLOBAL_Lin2: start-on-event=COMRXL_PECP_DBLK_ACTV_PECP_STAT_GLOBAL_Lin2_Received, data=Lin2ComRxSignalsSR.COMRXL_PECP_DBLK_ACTV_PECP_STAT_GLOBAL_Lin2
      data receive error event DEECOMRXL_PECP_DBLK_ACTV_PECP_STAT_GLOBAL_Lin2: start-on-event=COMRXL_PECP_DBLK_ACTV_PECP_STAT_GLOBAL_Lin2_Error, data=Lin2ComRxSignalsSR.COMRXL_PECP_DBLK_ACTV_PECP_STAT_GLOBAL_Lin2
      data received event DRECOMRXL_PECP_MONTRNG_RPM_PECP_STAT_GLOBAL_Lin2: start-on-event=COMRXL_PECP_MONTRNG_RPM_PECP_STAT_GLOBAL_Lin2_Received, data=Lin2ComRxSignalsSR.COMRXL_PECP_MONTRNG_RPM_PECP_STAT_GLOBAL_Lin2
      data receive error event DEECOMRXL_PECP_MONTRNG_RPM_PECP_STAT_GLOBAL_Lin2: start-on-event=COMRXL_PECP_MONTRNG_RPM_PECP_STAT_GLOBAL_Lin2_Error, data=Lin2ComRxSignalsSR.COMRXL_PECP_MONTRNG_RPM_PECP_STAT_GLOBAL_Lin2
      data received event DRECOMRXL_PECP_NODE_ERR_PECP_STAT_GLOBAL_Lin2: start-on-event=COMRXL_PECP_NODE_ERR_PECP_STAT_GLOBAL_Lin2_Received, data=Lin2ComRxSignalsSR.COMRXL_PECP_NODE_ERR_PECP_STAT_GLOBAL_Lin2
      data receive error event DEECOMRXL_PECP_NODE_ERR_PECP_STAT_GLOBAL_Lin2: start-on-event=COMRXL_PECP_NODE_ERR_PECP_STAT_GLOBAL_Lin2_Error, data=Lin2ComRxSignalsSR.COMRXL_PECP_NODE_ERR_PECP_STAT_GLOBAL_Lin2
      data received event DRECOMRXL_PECP_POST_RUN_STAT_PECP_STAT_GLOBAL_Lin2: start-on-event=COMRXL_PECP_POST_RUN_STAT_PECP_STAT_GLOBAL_Lin2_Received, data=Lin2ComRxSignalsSR.COMRXL_PECP_POST_RUN_STAT_PECP_STAT_GLOBAL_Lin2
      data receive error event DEECOMRXL_PECP_POST_RUN_STAT_PECP_STAT_GLOBAL_Lin2: start-on-event=COMRXL_PECP_POST_RUN_STAT_PECP_STAT_GLOBAL_Lin2_Error, data=Lin2ComRxSignalsSR.COMRXL_PECP_POST_RUN_STAT_PECP_STAT_GLOBAL_Lin2
      data received event DRECOMRXL_RsErr_PECP_PUMP_PECP_STAT_GLOBAL_Lin2: start-on-event=COMRXL_RsErr_PECP_PUMP_PECP_STAT_GLOBAL_Lin2_Received, data=Lin2ComRxSignalsSR.COMRXL_RsErr_PECP_PUMP_PECP_STAT_GLOBAL_Lin2
      data receive error event DEECOMRXL_RsErr_PECP_PUMP_PECP_STAT_GLOBAL_Lin2: start-on-event=COMRXL_RsErr_PECP_PUMP_PECP_STAT_GLOBAL_Lin2_Error, data=Lin2ComRxSignalsSR.COMRXL_RsErr_PECP_PUMP_PECP_STAT_GLOBAL_Lin2
      data received event DRECOMRXL_PECP_SUPPLIER_PECP_VER_Lin2: start-on-event=COMRXL_PECP_SUPPLIER_PECP_VER_Lin2_Received, data=Lin2ComRxSignalsSR.COMRXL_PECP_SUPPLIER_PECP_VER_Lin2
      data receive error event DEECOMRXL_PECP_SUPPLIER_PECP_VER_Lin2: start-on-event=COMRXL_PECP_SUPPLIER_PECP_VER_Lin2_Error, data=Lin2ComRxSignalsSR.COMRXL_PECP_SUPPLIER_PECP_VER_Lin2
      data received event DRECOMRXL_PowerPanel_Button_State_PowerPanel_STAT_Lin2: start-on-event=COMRXL_PowerPanel_Button_State_PowerPanel_STAT_Lin2_Received, data=Lin2ComRxSignalsSR.COMRXL_PowerPanel_Button_State_PowerPanel_STAT_Lin2
      data receive error event DEECOMRXL_PowerPanel_Button_State_PowerPanel_STAT_Lin2: start-on-event=COMRXL_PowerPanel_Button_State_PowerPanel_STAT_Lin2_Error, data=Lin2ComRxSignalsSR.COMRXL_PowerPanel_Button_State_PowerPanel_STAT_Lin2
      data received event DRECOMRXL_PowerPanel_Lid_Switch_Sts_120A_PowerPanel_STAT_Lin2: start-on-event=COMRXL_PowerPanel_Lid_Switch_Sts_120A_PowerPanel_STAT_Lin2_Received, data=Lin2ComRxSignalsSR.COMRXL_PowerPanel_Lid_Switch_Sts_120A_PowerPanel_STAT_Lin2
      data receive error event DEECOMRXL_PowerPanel_Lid_Switch_Sts_120A_PowerPanel_STAT_Lin2: start-on-event=COMRXL_PowerPanel_Lid_Switch_Sts_120A_PowerPanel_STAT_Lin2_Error, data=Lin2ComRxSignalsSR.COMRXL_PowerPanel_Lid_Switch_Sts_120A_PowerPanel_STAT_Lin2
      data received event DRECOMRXL_PowerPanel_Lid_Switch_Sts_120B_PowerPanel_STAT_Lin2: start-on-event=COMRXL_PowerPanel_Lid_Switch_Sts_120B_PowerPanel_STAT_Lin2_Received, data=Lin2ComRxSignalsSR.COMRXL_PowerPanel_Lid_Switch_Sts_120B_PowerPanel_STAT_Lin2
      data receive error event DEECOMRXL_PowerPanel_Lid_Switch_Sts_120B_PowerPanel_STAT_Lin2: start-on-event=COMRXL_PowerPanel_Lid_Switch_Sts_120B_PowerPanel_STAT_Lin2_Error, data=Lin2ComRxSignalsSR.COMRXL_PowerPanel_Lid_Switch_Sts_120B_PowerPanel_STAT_Lin2
      data received event DRECOMRXL_PowerPanel_Lid_Switch_Sts_240_PowerPanel_STAT_Lin2: start-on-event=COMRXL_PowerPanel_Lid_Switch_Sts_240_PowerPanel_STAT_Lin2_Received, data=Lin2ComRxSignalsSR.COMRXL_PowerPanel_Lid_Switch_Sts_240_PowerPanel_STAT_Lin2
      data receive error event DEECOMRXL_PowerPanel_Lid_Switch_Sts_240_PowerPanel_STAT_Lin2: start-on-event=COMRXL_PowerPanel_Lid_Switch_Sts_240_PowerPanel_STAT_Lin2_Error, data=Lin2ComRxSignalsSR.COMRXL_PowerPanel_Lid_Switch_Sts_240_PowerPanel_STAT_Lin2
      data received event DRECOMRXL_PowerPanel_Fault_Reason_PowerPanel_STAT_Lin2: start-on-event=COMRXL_PowerPanel_Fault_Reason_PowerPanel_STAT_Lin2_Received, data=Lin2ComRxSignalsSR.COMRXL_PowerPanel_Fault_Reason_PowerPanel_STAT_Lin2
      data receive error event DEECOMRXL_PowerPanel_Fault_Reason_PowerPanel_STAT_Lin2: start-on-event=COMRXL_PowerPanel_Fault_Reason_PowerPanel_STAT_Lin2_Error, data=Lin2ComRxSignalsSR.COMRXL_PowerPanel_Fault_Reason_PowerPanel_STAT_Lin2
      data received event DRECOMRXL_RsErr_SPP_PowerPanel_STAT_Lin2: start-on-event=COMRXL_RsErr_SPP_PowerPanel_STAT_Lin2_Received, data=Lin2ComRxSignalsSR.COMRXL_RsErr_SPP_PowerPanel_STAT_Lin2
      data receive error event DEECOMRXL_RsErr_SPP_PowerPanel_STAT_Lin2: start-on-event=COMRXL_RsErr_SPP_PowerPanel_STAT_Lin2_Error, data=Lin2ComRxSignalsSR.COMRXL_RsErr_SPP_PowerPanel_STAT_Lin2
      36 x data received event:
        DRESendLINR_AGS2_PosRq: start-on-event=SendLINR_AGS2_PosRq, data=SendLINR_AGS2_PosRq.SendLINR_AGS2_PosRq
        DRESendLINR_AGS2_CalRq: start-on-event=SendLINR_AGS2_CalRq, data=SendLINR_AGS2_CalRq.SendLINR_AGS2_CalRq
        DRESendLINR_AGS2_BoostRq: start-on-event=SendLINR_AGS2_BoostRq, data=SendLINR_AGS2_BoostRq.SendLINR_AGS2_BoostRq
        DRESendLINR_M2SRes2Bit_AGS2: start-on-event=SendLINR_M2SRes2Bit_AGS2, data=SendLINR_M2SRes2Bit_AGS2.SendLINR_M2SRes2Bit_AGS2
        DRESendLINR_M2SResByte{1..3}_AGS2: start-on-event=SendLINR_M2SResByte{1..3}_AGS2, data=SendLINR_M2SResByte{1..3}_AGS2.SendLINR_M2SResByte{1..3}_AGS2
        DRESendLINR_AHP_RPM_REQ_PERCT: start-on-event=SendLINR_AHP_RPM_REQ_PERCT, data=SendLINR_AHP_RPM_REQ_PERCT.SendLINR_AHP_RPM_REQ_PERCT
        DRESendLINR_AHP_POST_RUN_REQ: start-on-event=SendLINR_AHP_POST_RUN_REQ, data=SendLINR_AHP_POST_RUN_REQ.SendLINR_AHP_POST_RUN_REQ
        DRESendLINR_AHP_FL_SAFE_ACTVT: start-on-event=SendLINR_AHP_FL_SAFE_ACTVT, data=SendLINR_AHP_FL_SAFE_ACTVT.SendLINR_AHP_FL_SAFE_ACTVT
        DRESendLINR_BHV_PosRq: start-on-event=SendLINR_BHV_PosRq, data=SendLINR_BHV_PosRq.SendLINR_BHV_PosRq
        DRESendLINR_BHV_PosSv: start-on-event=SendLINR_BHV_PosSv, data=SendLINR_BHV_PosSv.SendLINR_BHV_PosSv
        DRESendLINR_BHV_CalRq: start-on-event=SendLINR_BHV_CalRq, data=SendLINR_BHV_CalRq.SendLINR_BHV_CalRq
        DRESendLINR_CompressorSpdReq: start-on-event=SendLINR_CompressorSpdReq, data=SendLINR_CompressorSpdReq.SendLINR_CompressorSpdReq
        DRESendLINR_CompEnable: start-on-event=SendLINR_CompEnable, data=SendLINR_CompEnable.SendLINR_CompEnable
        DRESendLINR_DriveEcohybridLmp: start-on-event=SendLINR_DriveEcohybridLmp, data=SendLINR_DriveEcohybridLmp.SendLINR_DriveEcohybridLmp
        DRESendLINR_DriveElectricLmp: start-on-event=SendLINR_DriveElectricLmp, data=SendLINR_DriveElectricLmp.SendLINR_DriveElectricLmp
        DRESendLINR_DriveESaveLmp: start-on-event=SendLINR_DriveESaveLmp, data=SendLINR_DriveESaveLmp.SendLINR_DriveESaveLmp
        DRESendLINR_DriveSportHybridLmp: start-on-event=SendLINR_DriveSportHybridLmp, data=SendLINR_DriveSportHybridLmp.SendLINR_DriveSportHybridLmp
        DRESendLINR_PanelIntensitySts: start-on-event=SendLINR_PanelIntensitySts, data=SendLINR_PanelIntensitySts.SendLINR_PanelIntensitySts
        DRESendLINR_DAY_LGT_MD: start-on-event=SendLINR_DAY_LGT_MD, data=SendLINR_DAY_LGT_MD.SendLINR_DAY_LGT_MD
        DRESendLINR_PECP_RPM_REQ_PERCT: start-on-event=SendLINR_PECP_RPM_REQ_PERCT, data=SendLINR_PECP_RPM_REQ_PERCT.SendLINR_PECP_RPM_REQ_PERCT
        DRESendLINR_PECP_POST_RUN_REQ: start-on-event=SendLINR_PECP_POST_RUN_REQ, data=SendLINR_PECP_POST_RUN_REQ.SendLINR_PECP_POST_RUN_REQ
        DRESendLINR_PECP_FL_SAFE_ACTVT: start-on-event=SendLINR_PECP_FL_SAFE_ACTVT, data=SendLINR_PECP_FL_SAFE_ACTVT.SendLINR_PECP_FL_SAFE_ACTVT
        DRESendLINR_PwrPanel_LED_A_Command: start-on-event=SendLINR_PwrPanel_LED_A_Command, data=SendLINR_PwrPanel_LED_A_Command.SendLINR_PwrPanel_LED_A_Command
        DRESendLINR_PwrPanel_LED_B_Command: start-on-event=SendLINR_PwrPanel_LED_B_Command, data=SendLINR_PwrPanel_LED_B_Command.SendLINR_PwrPanel_LED_B_Command
        DRESendLINR_DAY_LGT_MD_PowerPanel: start-on-event=SendLINR_DAY_LGT_MD_PowerPanel, data=SendLINR_DAY_LGT_MD_PowerPanel.SendLINR_DAY_LGT_MD_PowerPanel
        DRESignalLINR_AGS2_RdyForSleep: start-on-event=SignalLINR_AGS2_RdyForSleep, data=SignalLINR_AGS2_RdyForSleep.SignalLINR_AGS2_RdyForSleep
          disabled-mode:
            MdulPwrMod.AppMode_MDGP_ESH_Mode.RUN
            MdulPwrMod.AppMode_MDGP_ESH_Mode.STARTUP
            MdulPwrMod.AppMode_MDGP_ESH_Mode.SHUTDOWN
            MdulPwrMod.AppMode_MDGP_ESH_Mode.WAKEUP
        DRESignalLINR_AHP_RdyForSleep: start-on-event=SignalLINR_AHP_RdyForSleep, data=SignalLINR_AHP_RdyForSleep.SignalLINR_AHP_RdyForSleep
          disabled-mode:
            MdulPwrMod.AppMode_MDGP_ESH_Mode.RUN
            MdulPwrMod.AppMode_MDGP_ESH_Mode.STARTUP
            MdulPwrMod.AppMode_MDGP_ESH_Mode.SHUTDOWN
            MdulPwrMod.AppMode_MDGP_ESH_Mode.WAKEUP
        DRESignalLINR_BHV_RdyForSleep: start-on-event=SignalLINR_BHV_RdyForSleep, data=SignalLINR_BHV_RdyForSleep.SignalLINR_BHV_RdyForSleep
          disabled-mode:
            MdulPwrMod.AppMode_MDGP_ESH_Mode.RUN
            MdulPwrMod.AppMode_MDGP_ESH_Mode.STARTUP
            MdulPwrMod.AppMode_MDGP_ESH_Mode.SHUTDOWN
            MdulPwrMod.AppMode_MDGP_ESH_Mode.WAKEUP
        DRESignalLINR_EAC2_RdyForSleep: start-on-event=SignalLINR_EAC2_RdyForSleep, data=SignalLINR_EAC2_RdyForSleep.SignalLINR_EAC2_RdyForSleep
          disabled-mode:
            MdulPwrMod.AppMode_MDGP_ESH_Mode.RUN
            MdulPwrMod.AppMode_MDGP_ESH_Mode.STARTUP
            MdulPwrMod.AppMode_MDGP_ESH_Mode.SHUTDOWN
            MdulPwrMod.AppMode_MDGP_ESH_Mode.WAKEUP
        DRESignalLINR_ESBM_RdyForSleep: start-on-event=SignalLINR_ESBM_RdyForSleep, data=SignalLINR_ESBM_RdyForSleep.SignalLINR_ESBM_RdyForSleep
          disabled-mode:
            MdulPwrMod.AppMode_MDGP_ESH_Mode.RUN
            MdulPwrMod.AppMode_MDGP_ESH_Mode.STARTUP
            MdulPwrMod.AppMode_MDGP_ESH_Mode.SHUTDOWN
            MdulPwrMod.AppMode_MDGP_ESH_Mode.WAKEUP
        DRESignalLINR_OEXV_RdyForSleep: start-on-event=SignalLINR_OEXV_RdyForSleep, data=SignalLINR_OEXV_RdyForSleep.SignalLINR_OEXV_RdyForSleep
          disabled-mode:
            MdulPwrMod.AppMode_MDGP_ESH_Mode.RUN
            MdulPwrMod.AppMode_MDGP_ESH_Mode.STARTUP
            MdulPwrMod.AppMode_MDGP_ESH_Mode.SHUTDOWN
            MdulPwrMod.AppMode_MDGP_ESH_Mode.WAKEUP
        DRESignalLINR_PECP_RdyForSleep: start-on-event=SignalLINR_PECP_RdyForSleep, data=SignalLINR_PECP_RdyForSleep.SignalLINR_PECP_RdyForSleep
          disabled-mode:
            MdulPwrMod.AppMode_MDGP_ESH_Mode.RUN
            MdulPwrMod.AppMode_MDGP_ESH_Mode.STARTUP
            MdulPwrMod.AppMode_MDGP_ESH_Mode.SHUTDOWN
            MdulPwrMod.AppMode_MDGP_ESH_Mode.WAKEUP
        DRESignalLINR_SPP_RdyForSleep: start-on-event=SignalLINR_SPP_RdyForSleep, data=SignalLINR_SPP_RdyForSleep.SignalLINR_SPP_RdyForSleep
          disabled-mode:
            MdulPwrMod.AppMode_MDGP_ESH_Mode.RUN
            MdulPwrMod.AppMode_MDGP_ESH_Mode.STARTUP
            MdulPwrMod.AppMode_MDGP_ESH_Mode.SHUTDOWN
            MdulPwrMod.AppMode_MDGP_ESH_Mode.WAKEUP
        DRECOMRXL_AHP_VERSION_AHP_VER_Lin2: start-on-event=COMRXL_AHP_VERSION_AHP_VER_Lin2_Received, data=Lin2ComRxSignalsSR.COMRXL_AHP_VERSION_AHP_VER_Lin2
      data receive error event DEECOMRXL_AHP_VERSION_AHP_VER_Lin2: start-on-event=COMRXL_AHP_VERSION_AHP_VER_Lin2_Error, data=Lin2ComRxSignalsSR.COMRXL_AHP_VERSION_AHP_VER_Lin2
      data received event DRECOMRXL_PECP_VERSION_PECP_VER_Lin2: start-on-event=COMRXL_PECP_VERSION_PECP_VER_Lin2_Received, data=Lin2ComRxSignalsSR.COMRXL_PECP_VERSION_PECP_VER_Lin2
      data receive error event DEECOMRXL_PECP_VERSION_PECP_VER_Lin2: start-on-event=COMRXL_PECP_VERSION_PECP_VER_Lin2_Error, data=Lin2ComRxSignalsSR.COMRXL_PECP_VERSION_PECP_VER_Lin2
      data received event DRECOMRXL_S2MResByte1_AGS2_AGS2_ECM_STATUS_Lin2: start-on-event=COMRXL_S2MResByte1_AGS2_AGS2_ECM_STATUS_Lin2_Received, data=Lin2ComRxSignalsSR.COMRXL_S2MResByte1_AGS2_AGS2_ECM_STATUS_Lin2
      data receive error event DEECOMRXL_S2MResByte1_AGS2_AGS2_ECM_STATUS_Lin2: start-on-event=COMRXL_S2MResByte1_AGS2_AGS2_ECM_STATUS_Lin2_Error, data=Lin2ComRxSignalsSR.COMRXL_S2MResByte1_AGS2_AGS2_ECM_STATUS_Lin2
      data received event DRECOMRXL_S2MResByte2_AGS2_AGS2_ECM_STATUS_Lin2: start-on-event=COMRXL_S2MResByte2_AGS2_AGS2_ECM_STATUS_Lin2_Received, data=Lin2ComRxSignalsSR.COMRXL_S2MResByte2_AGS2_AGS2_ECM_STATUS_Lin2
      data receive error event DEECOMRXL_S2MResByte2_AGS2_AGS2_ECM_STATUS_Lin2: start-on-event=COMRXL_S2MResByte2_AGS2_AGS2_ECM_STATUS_Lin2_Error, data=Lin2ComRxSignalsSR.COMRXL_S2MResByte2_AGS2_AGS2_ECM_STATUS_Lin2
      data received event DRECOMRXL_BHV_MotorVolt_BHV_STAT_V2_Lin2: start-on-event=COMRXL_BHV_MotorVolt_BHV_STAT_V2_Lin2_Received, data=Lin2ComRxSignalsSR.COMRXL_BHV_MotorVolt_BHV_STAT_V2_Lin2
      data receive error event DEECOMRXL_BHV_MotorVolt_BHV_STAT_V2_Lin2: start-on-event=COMRXL_BHV_MotorVolt_BHV_STAT_V2_Lin2_Error, data=Lin2ComRxSignalsSR.COMRXL_BHV_MotorVolt_BHV_STAT_V2_Lin2
      data received event DRECOMRXL_BHV_CalStat_BHV_STAT_V2_Lin2: start-on-event=COMRXL_BHV_CalStat_BHV_STAT_V2_Lin2_Received, data=Lin2ComRxSignalsSR.COMRXL_BHV_CalStat_BHV_STAT_V2_Lin2
      data receive error event DEECOMRXL_BHV_CalStat_BHV_STAT_V2_Lin2: start-on-event=COMRXL_BHV_CalStat_BHV_STAT_V2_Lin2_Error, data=Lin2ComRxSignalsSR.COMRXL_BHV_CalStat_BHV_STAT_V2_Lin2
      data received event DRECOMRXL_OEXV_PosAct_OEXV_STAT_Lin2: start-on-event=COMRXL_OEXV_PosAct_OEXV_STAT_Lin2_Received, data=Lin2ComRxSignalsSR.COMRXL_OEXV_PosAct_OEXV_STAT_Lin2
      data receive error event DEECOMRXL_OEXV_PosAct_OEXV_STAT_Lin2: start-on-event=COMRXL_OEXV_PosAct_OEXV_STAT_Lin2_Error, data=Lin2ComRxSignalsSR.COMRXL_OEXV_PosAct_OEXV_STAT_Lin2
      data received event DRECOMRXL_OEXV_CalStat_OEXV_STAT_Lin2: start-on-event=COMRXL_OEXV_CalStat_OEXV_STAT_Lin2_Received, data=Lin2ComRxSignalsSR.COMRXL_OEXV_CalStat_OEXV_STAT_Lin2
      data receive error event DEECOMRXL_OEXV_CalStat_OEXV_STAT_Lin2: start-on-event=COMRXL_OEXV_CalStat_OEXV_STAT_Lin2_Error, data=Lin2ComRxSignalsSR.COMRXL_OEXV_CalStat_OEXV_STAT_Lin2
      data received event DRECOMRXL_OEXV_CalRq_OEXV_STAT_Lin2: start-on-event=COMRXL_OEXV_CalRq_OEXV_STAT_Lin2_Received, data=Lin2ComRxSignalsSR.COMRXL_OEXV_CalRq_OEXV_STAT_Lin2
      data receive error event DEECOMRXL_OEXV_CalRq_OEXV_STAT_Lin2: start-on-event=COMRXL_OEXV_CalRq_OEXV_STAT_Lin2_Error, data=Lin2ComRxSignalsSR.COMRXL_OEXV_CalRq_OEXV_STAT_Lin2
      data received event DRECOMRXL_RsErr_OEXV_OEXV_STAT_Lin2: start-on-event=COMRXL_RsErr_OEXV_OEXV_STAT_Lin2_Received, data=Lin2ComRxSignalsSR.COMRXL_RsErr_OEXV_OEXV_STAT_Lin2
      data receive error event DEECOMRXL_RsErr_OEXV_OEXV_STAT_Lin2: start-on-event=COMRXL_RsErr_OEXV_OEXV_STAT_Lin2_Error, data=Lin2ComRxSignalsSR.COMRXL_RsErr_OEXV_OEXV_STAT_Lin2
      data received event DRECOMRXL_OEXV_Sts_OEXV_STAT_Lin2: start-on-event=COMRXL_OEXV_Sts_OEXV_STAT_Lin2_Received, data=Lin2ComRxSignalsSR.COMRXL_OEXV_Sts_OEXV_STAT_Lin2
      data receive error event DEECOMRXL_OEXV_Sts_OEXV_STAT_Lin2: start-on-event=COMRXL_OEXV_Sts_OEXV_STAT_Lin2_Error, data=Lin2ComRxSignalsSR.COMRXL_OEXV_Sts_OEXV_STAT_Lin2
      data received event DRECOMRXL_OEXV_ERR_OEXV_STAT_Lin2: start-on-event=COMRXL_OEXV_ERR_OEXV_STAT_Lin2_Received, data=Lin2ComRxSignalsSR.COMRXL_OEXV_ERR_OEXV_STAT_Lin2
      data receive error event DEECOMRXL_OEXV_ERR_OEXV_STAT_Lin2: start-on-event=COMRXL_OEXV_ERR_OEXV_STAT_Lin2_Error, data=Lin2ComRxSignalsSR.COMRXL_OEXV_ERR_OEXV_STAT_Lin2
      data received event DRECOMRXL_OEXV_SupplyVolt_OEXV_STAT_Lin2: start-on-event=COMRXL_OEXV_SupplyVolt_OEXV_STAT_Lin2_Received, data=Lin2ComRxSignalsSR.COMRXL_OEXV_SupplyVolt_OEXV_STAT_Lin2
      data receive error event DEECOMRXL_OEXV_SupplyVolt_OEXV_STAT_Lin2: start-on-event=COMRXL_OEXV_SupplyVolt_OEXV_STAT_Lin2_Error, data=Lin2ComRxSignalsSR.COMRXL_OEXV_SupplyVolt_OEXV_STAT_Lin2
      data received event DRECOMRXL_OEXV_Refrigerant_Pressure_OEXV_STAT_Lin2: start-on-event=COMRXL_OEXV_Refrigerant_Pressure_OEXV_STAT_Lin2_Received, data=Lin2ComRxSignalsSR.COMRXL_OEXV_Refrigerant_Pressure_OEXV_STAT_Lin2
      data receive error event DEECOMRXL_OEXV_Refrigerant_Pressure_OEXV_STAT_Lin2: start-on-event=COMRXL_OEXV_Refrigerant_Pressure_OEXV_STAT_Lin2_Error, data=Lin2ComRxSignalsSR.COMRXL_OEXV_Refrigerant_Pressure_OEXV_STAT_Lin2
      data received event DRECOMRXL_OEXV_Board_Temp_OEXV_STAT_Lin2: start-on-event=COMRXL_OEXV_Board_Temp_OEXV_STAT_Lin2_Received, data=Lin2ComRxSignalsSR.COMRXL_OEXV_Board_Temp_OEXV_STAT_Lin2
      data receive error event DEECOMRXL_OEXV_Board_Temp_OEXV_STAT_Lin2: start-on-event=COMRXL_OEXV_Board_Temp_OEXV_STAT_Lin2_Error, data=Lin2ComRxSignalsSR.COMRXL_OEXV_Board_Temp_OEXV_STAT_Lin2
      data received event DRECOMRXL_OEXV_Refrigerant_Temp_OEXV_STAT_Lin2: start-on-event=COMRXL_OEXV_Refrigerant_Temp_OEXV_STAT_Lin2_Received, data=Lin2ComRxSignalsSR.COMRXL_OEXV_Refrigerant_Temp_OEXV_STAT_Lin2
      data receive error event DEECOMRXL_OEXV_Refrigerant_Temp_OEXV_STAT_Lin2: start-on-event=COMRXL_OEXV_Refrigerant_Temp_OEXV_STAT_Lin2_Error, data=Lin2ComRxSignalsSR.COMRXL_OEXV_Refrigerant_Temp_OEXV_STAT_Lin2
      data received event DRESendLINR_OEXV_PosRq: start-on-event=SendLINR_OEXV_PosRq, data=SendLINR_OEXV_PosRq.SendLINR_OEXV_PosRq
      data received event DRESendLINR_OEXV_CalCmd: start-on-event=SendLINR_OEXV_CalCmd, data=SendLINR_OEXV_CalCmd.SendLINR_OEXV_CalCmd
      data received event DRECOMRXL_CompFaultStat_800_EAC_STAT_800_Lin2: start-on-event=COMRXL_CompFaultStat_800_EAC_STAT_800_Lin2_Received, data=Lin2ComRxSignalsSR.COMRXL_CompFaultStat_800_EAC_STAT_800_Lin2
      data receive error event DEECOMRXL_CompFaultStat_800_EAC_STAT_800_Lin2: start-on-event=COMRXL_CompFaultStat_800_EAC_STAT_800_Lin2_Error, data=Lin2ComRxSignalsSR.COMRXL_CompFaultStat_800_EAC_STAT_800_Lin2
      data received event DRECOMRXL_CompStat_800_EAC_STAT_800_Lin2: start-on-event=COMRXL_CompStat_800_EAC_STAT_800_Lin2_Received, data=Lin2ComRxSignalsSR.COMRXL_CompStat_800_EAC_STAT_800_Lin2
      data receive error event DEECOMRXL_CompStat_800_EAC_STAT_800_Lin2: start-on-event=COMRXL_CompStat_800_EAC_STAT_800_Lin2_Error, data=Lin2ComRxSignalsSR.COMRXL_CompStat_800_EAC_STAT_800_Lin2
      data received event DRECOMRXL_CompressorSpd_800_EAC_STAT_800_Lin2: start-on-event=COMRXL_CompressorSpd_800_EAC_STAT_800_Lin2_Received, data=Lin2ComRxSignalsSR.COMRXL_CompressorSpd_800_EAC_STAT_800_Lin2
      data receive error event DEECOMRXL_CompressorSpd_800_EAC_STAT_800_Lin2: start-on-event=COMRXL_CompressorSpd_800_EAC_STAT_800_Lin2_Error, data=Lin2ComRxSignalsSR.COMRXL_CompressorSpd_800_EAC_STAT_800_Lin2
      data received event DRECOMRXL_CompSpdIncrReq_800_EAC_STAT_800_Lin2: start-on-event=COMRXL_CompSpdIncrReq_800_EAC_STAT_800_Lin2_Received, data=Lin2ComRxSignalsSR.COMRXL_CompSpdIncrReq_800_EAC_STAT_800_Lin2
      data receive error event DEECOMRXL_CompSpdIncrReq_800_EAC_STAT_800_Lin2: start-on-event=COMRXL_CompSpdIncrReq_800_EAC_STAT_800_Lin2_Error, data=Lin2ComRxSignalsSR.COMRXL_CompSpdIncrReq_800_EAC_STAT_800_Lin2
      data received event DRECOMRXL_RsErr_EAC2_800_EAC_STAT_800_Lin2: start-on-event=COMRXL_RsErr_EAC2_800_EAC_STAT_800_Lin2_Received, data=Lin2ComRxSignalsSR.COMRXL_RsErr_EAC2_800_EAC_STAT_800_Lin2
      data receive error event DEECOMRXL_RsErr_EAC2_800_EAC_STAT_800_Lin2: start-on-event=COMRXL_RsErr_EAC2_800_EAC_STAT_800_Lin2_Error, data=Lin2ComRxSignalsSR.COMRXL_RsErr_EAC2_800_EAC_STAT_800_Lin2
      data received event DRECOMRXL_CompElecPwr_800_EAC_STAT_800_Lin2: start-on-event=COMRXL_CompElecPwr_800_EAC_STAT_800_Lin2_Received, data=Lin2ComRxSignalsSR.COMRXL_CompElecPwr_800_EAC_STAT_800_Lin2
      data receive error event DEECOMRXL_CompElecPwr_800_EAC_STAT_800_Lin2: start-on-event=COMRXL_CompElecPwr_800_EAC_STAT_800_Lin2_Error, data=Lin2ComRxSignalsSR.COMRXL_CompElecPwr_800_EAC_STAT_800_Lin2
      data received event DRECOMRXL_CompBoardTemp_800_EAC_STAT_800_Lin2: start-on-event=COMRXL_CompBoardTemp_800_EAC_STAT_800_Lin2_Received, data=Lin2ComRxSignalsSR.COMRXL_CompBoardTemp_800_EAC_STAT_800_Lin2
      data receive error event DEECOMRXL_CompBoardTemp_800_EAC_STAT_800_Lin2: start-on-event=COMRXL_CompBoardTemp_800_EAC_STAT_800_Lin2_Error, data=Lin2ComRxSignalsSR.COMRXL_CompBoardTemp_800_EAC_STAT_800_Lin2
      data received event DRECOMRXL_CompIGBTTemp_800_EAC_STAT_800_Lin2: start-on-event=COMRXL_CompIGBTTemp_800_EAC_STAT_800_Lin2_Received, data=Lin2ComRxSignalsSR.COMRXL_CompIGBTTemp_800_EAC_STAT_800_Lin2
      data receive error event DEECOMRXL_CompIGBTTemp_800_EAC_STAT_800_Lin2: start-on-event=COMRXL_CompIGBTTemp_800_EAC_STAT_800_Lin2_Error, data=Lin2ComRxSignalsSR.COMRXL_CompIGBTTemp_800_EAC_STAT_800_Lin2
      data received event DRECOMRXL_CompElecCurr_800_EAC_STAT_800_Lin2: start-on-event=COMRXL_CompElecCurr_800_EAC_STAT_800_Lin2_Received, data=Lin2ComRxSignalsSR.COMRXL_CompElecCurr_800_EAC_STAT_800_Lin2
      data receive error event DEECOMRXL_CompElecCurr_800_EAC_STAT_800_Lin2: start-on-event=COMRXL_CompElecCurr_800_EAC_STAT_800_Lin2_Error, data=Lin2ComRxSignalsSR.COMRXL_CompElecCurr_800_EAC_STAT_800_Lin2
      data received event DRECOMRXL_CompHVInput_800_EAC_STAT_800_Lin2: start-on-event=COMRXL_CompHVInput_800_EAC_STAT_800_Lin2_Received, data=Lin2ComRxSignalsSR.COMRXL_CompHVInput_800_EAC_STAT_800_Lin2
      data receive error event DEECOMRXL_CompHVInput_800_EAC_STAT_800_Lin2: start-on-event=COMRXL_CompHVInput_800_EAC_STAT_800_Lin2_Error, data=Lin2ComRxSignalsSR.COMRXL_CompHVInput_800_EAC_STAT_800_Lin2
      6 x data received event:
        DRESendLINR_PwrPanel_LED_C_Command: start-on-event=SendLINR_PwrPanel_LED_C_Command, data=SendLINR_PwrPanel_LED_C_Command.SendLINR_PwrPanel_LED_C_Command
        DRESendLINR_PwrPanel_LEDA_ColorCmd: start-on-event=SendLINR_PwrPanel_LEDA_ColorCmd, data=SendLINR_PwrPanel_LEDA_ColorCmd.SendLINR_PwrPanel_LEDA_ColorCmd
        DRESendLINR_PwrPanel_LEDB_ColorCmd: start-on-event=SendLINR_PwrPanel_LEDB_ColorCmd, data=SendLINR_PwrPanel_LEDB_ColorCmd.SendLINR_PwrPanel_LEDB_ColorCmd
        DRESendLINR_PwrPanel_LEDC_ColorCmd: start-on-event=SendLINR_PwrPanel_LEDC_ColorCmd, data=SendLINR_PwrPanel_LEDC_ColorCmd.SendLINR_PwrPanel_LEDC_ColorCmd
        DRESignalLINR_CACV_RdyForSleep: start-on-event=SignalLINR_CACV_RdyForSleep, data=SignalLINR_CACV_RdyForSleep.SignalLINR_CACV_RdyForSleep
          disabled-mode:
            MdulPwrMod.AppMode_MDGP_ESH_Mode.RUN
            MdulPwrMod.AppMode_MDGP_ESH_Mode.STARTUP
            MdulPwrMod.AppMode_MDGP_ESH_Mode.SHUTDOWN
            MdulPwrMod.AppMode_MDGP_ESH_Mode.WAKEUP
        DRECOMRXL_PowerPanel_LED_A_Feedback_PowerPanel_STAT_Lin2: start-on-event=COMRXL_PowerPanel_LED_A_Feedback_PowerPanel_STAT_Lin2_Received, data=Lin2ComRxSignalsSR.COMRXL_PowerPanel_LED_A_Feedback_PowerPanel_STAT_Lin2
      data receive error event DEECOMRXL_PowerPanel_LED_A_Feedback_PowerPanel_STAT_Lin2: start-on-event=COMRXL_PowerPanel_LED_A_Feedback_PowerPanel_STAT_Lin2_Error, data=Lin2ComRxSignalsSR.COMRXL_PowerPanel_LED_A_Feedback_PowerPanel_STAT_Lin2
      data received event DRECOMRXL_PowerPanel_LED_B_Feedback_PowerPanel_STAT_Lin2: start-on-event=COMRXL_PowerPanel_LED_B_Feedback_PowerPanel_STAT_Lin2_Received, data=Lin2ComRxSignalsSR.COMRXL_PowerPanel_LED_B_Feedback_PowerPanel_STAT_Lin2
      data receive error event DEECOMRXL_PowerPanel_LED_B_Feedback_PowerPanel_STAT_Lin2: start-on-event=COMRXL_PowerPanel_LED_B_Feedback_PowerPanel_STAT_Lin2_Error, data=Lin2ComRxSignalsSR.COMRXL_PowerPanel_LED_B_Feedback_PowerPanel_STAT_Lin2
      data received event DRECOMRXL_PowerPanel_LED_C_Feedback_PowerPanel_STAT_Lin2: start-on-event=COMRXL_PowerPanel_LED_C_Feedback_PowerPanel_STAT_Lin2_Received, data=Lin2ComRxSignalsSR.COMRXL_PowerPanel_LED_C_Feedback_PowerPanel_STAT_Lin2
      data receive error event DEECOMRXL_PowerPanel_LED_C_Feedback_PowerPanel_STAT_Lin2: start-on-event=COMRXL_PowerPanel_LED_C_Feedback_PowerPanel_STAT_Lin2_Error, data=Lin2ComRxSignalsSR.COMRXL_PowerPanel_LED_C_Feedback_PowerPanel_STAT_Lin2
      data received event DRECOMRXL_PowerPanel_LED_A_FailStatus_PowerPanel_STAT_Lin2: start-on-event=COMRXL_PowerPanel_LED_A_FailStatus_PowerPanel_STAT_Lin2_Received, data=Lin2ComRxSignalsSR.COMRXL_PowerPanel_LED_A_FailStatus_PowerPanel_STAT_Lin2
      data receive error event DEECOMRXL_PowerPanel_LED_A_FailStatus_PowerPanel_STAT_Lin2: start-on-event=COMRXL_PowerPanel_LED_A_FailStatus_PowerPanel_STAT_Lin2_Error, data=Lin2ComRxSignalsSR.COMRXL_PowerPanel_LED_A_FailStatus_PowerPanel_STAT_Lin2
      data received event DRECOMRXL_PowerPanel_LED_B_FailStatus_PowerPanel_STAT_Lin2: start-on-event=COMRXL_PowerPanel_LED_B_FailStatus_PowerPanel_STAT_Lin2_Received, data=Lin2ComRxSignalsSR.COMRXL_PowerPanel_LED_B_FailStatus_PowerPanel_STAT_Lin2
      data receive error event DEECOMRXL_PowerPanel_LED_B_FailStatus_PowerPanel_STAT_Lin2: start-on-event=COMRXL_PowerPanel_LED_B_FailStatus_PowerPanel_STAT_Lin2_Error, data=Lin2ComRxSignalsSR.COMRXL_PowerPanel_LED_B_FailStatus_PowerPanel_STAT_Lin2
